VERSION ""

NS_ :

BS_:

BU_: Gateway_25 FCM_A0 FLR SRR_RL External_Tool SRR_FL Steering_E4 VCU_47 CLS_17 ESC_0B EMS_00
VAL_TABLE_ TSC1CtrlPurpose 31 "Temporary Powertrain Control" 6 " Automated Driving System Input\r" 5 "Transient-Optimized Torque Limi" 4 "Engine Protection\r" 3 "Road Speed Governor\r" 2 " PTO Governor\r" 1 "Cruise Control\r" 0 "AcceleratorPedalOperatorSelect" ;
VAL_TABLE_ TrctrMntdTrailerABSWarningSignal 3 " Take no action" 2 "Reserved\r" 1 "on" 0 "Off\r" ;
VAL_TABLE_ EBSBrakeSwitch 3 "Not available" 2 "Error" 1 "Brake pedal being pressed\r" 0 "Brake pedal not beingpressed\r" ;
VAL_TABLE_ TSC1TransRate 6 "20 ms transmission rate\r" 5 "50 ms transmission rate\r" 4 "100 ms transmission rate\r" 3 "250 ms transmission rate\r" 2 "500 ms transmission rate\r" 1 "750 ms transmission rate\r" 0 "1000 ms transmission rate" ;
VAL_TABLE_ SeatBeltSwitch 3 "Not Available" 2 " Error - Switch state cannot be determined\r" 1 "OK - Seat Belt is buckled\r" 0 "NOT Buckled\r" ;
VAL_TABLE_ HighLowBeamSwitch 3 "not available" 2 "error" 1 "High Beam Selected\r" 0 "Low Beam Selected\r" ;
VAL_TABLE_ HazardLightSwitch 3 "not available" 2 "error" 1 "Hazard Lamps to be Flashing" 0 "Hazard Lamps to be Off\r" ;
VAL_TABLE_ TurnSignalSwitch 15 "Not available (do not change)" 14 "Error (to include both left and right selected simultaneously)\r" 13 "Description for the value '0xD'" 12 "Description for the value '0xC'" 11 "Description for the value '0xB'" 10 "Description for the value '0xA'" 9 "Description for the value '0x9'" 8 "Description for the value '0x8'" 7 "Description for the value '0x7'" 6 "Description for the value '0x6'" 5 "Description for the value '0x5'" 4 "Description for the value '0x4'" 3 "Description for the value '0x3'" 2 "Right turn to be Flashing\r" 1 "Left Turn to be Flashing\r" 0 "No Turn being signaled\r" ;
VAL_TABLE_ YCBrakeCtrlActive 3 "take no action" 2 "reserved" 1 "YC brake control active" 0 "YC brake control passive but installed\r" ;
VAL_TABLE_ YCEngCtrlActive 3 "Don't care/Take no action" 2 "reserved" 1 "YC engine control active" 0 "YC engine control passive but installed\r" ;
VAL_TABLE_ ROPBrakeCtrlActive 3 "take no action" 2 "reserved" 1 "ROP brake control active\r" 0 "ROP brake control passive but installed\r" ;
VAL_TABLE_ ROPEngCtrlActive 3 "take no action" 2 "reserved" 1 "ROP engine control active\r" 0 "ROP engine control passive but installed\r" ;
VAL_TABLE_ VDCBrakeLightRq 3 "don't care/ take no action" 2 "reserved" 1 "Turn brake light on\r" 0 "Turn brake light not on\r" ;
VAL_TABLE_ VDCFullyOperational 3 "Don't care/Take no action" 2 "Reserved\r" 1 "Fully operational\r" 0 "Not fully operationa" ;
VAL_TABLE_ XBRActiveCtrlMode 15 "Not available" 14 "Description for the value '0xE'" 13 "Description for the value '0xD'" 12 "Description for the value '0xC'" 11 "Description for the value '0xB'" 10 "Description for the value '0xA'" 9 "Description for the value '0x9'" 8 "Description for the value '0x8'" 7 "Description for the value '0x7'" 6 "Description for the value '0x6'" 5 "Description for the value '0x5'" 4 "XBR Brake Hold is being executed to hold the vehicle still based on XBR Brake Hold Request\r" 3 "Maximum mode of XBR acceleration control being executed" 2 "Addition mode of XBR acceleration control being executed" 1 "Driver's brake demand being executed, no external brake demand\r" 0 "No brake demand being executed (default mode)\r" ;
VAL_TABLE_ XBRSystemState 3 "not available" 2 " No external brake demand will be accepted " 1 "Only external brake demand of highest XBR Priority (00b) will be accepted " 0 "Any external brake demand will be accepted (brake system fully operational)\r" ;
VAL_TABLE_ FoundationBrakeUse 3 "not available" 2 "reserved" 1 "Foundation brakes in use\r" 0 "Foundation brakes not in use" ;
VAL_TABLE_ ABSFullyOperational 3 "not available" 2 "reserved" 1 " Fully Operational" 0 "Not Fully Operational\r" ;
VAL_TABLE_ AntiLockBrakingActive 3 "not available" 2 "reserved" 1 "ABS active\r" 0 "ABS passive but installed" ;
VAL_TABLE_ ASRBrakeCtrlActive 3 "not available" 2 "reserved" 1 "ASR brake control active" 0 "ASR brake control passive but installed\r" ;
VAL_TABLE_ ASREngCtrlActive 3 "not available" 2 "reserved" 1 "ASR engine control active" 0 "ASR engine control passive but installed\r" ;
VAL_TABLE_ AccelPedalKickdownSwitch 3 "not available" 2 "error" 1 "kickdown active" 0 "kickdown passive" ;
VAL_TABLE_ brakeSwitch 3 "no available" 2 "error" 1 "pedal depressed" 0 "pedal released" ;
VAL_TABLE_ FrontOperatorWiperSwitch 15 "Not available (do not change)" 14 "Description for the value '0xE'" 13 "Description for the value '0xD'" 12 "Description for the value '0xC'" 11 "Description for the value '0xB'" 10 "Description for the value '0xA'" 9 "Description for the value '0x9'" 8 "Description for the value '0x8'" 7 "Description for the value '0x7'" 6 "Mist (position where external sensor  controls wiper rate)\r" 5 "Delayed 2 (used for the second delay choice when the wiper switch position controls the delay" 4 "Delayed 1 (used for the first delay choice when the wiper switch position controls the delay)\r" 3 "high" 2 "medium" 1 "low" 0 "Off" ;
VAL_TABLE_ LaneDepartureWarningEnableCmd 3 "dont care" 2 "Reserved\r" 1 "Enable Lane Departure Warning\r" 0 "Disable Lane Departure Warning\r" ;
VAL_TABLE_ DrvrActvtnDmndFrAdvncdEmrgncyBrk 3 "don't' care / take no action" 2 "reserved" 1 "the driver wants the Advanced Emergency Braking System to warn or intervene if necessary (no deactivation of system)\r" 0 " the driver does not want the Advanced Emergency Braking System to warn or intervene at any time (deactivation of system)\r" ;
VAL_TABLE_ WarningRelevanObjectDetected 7 "Not available / not installed" 6 "Error " 5 "Relevant object(s) is not being detected reliably " 4 "Description for the value '0x4'" 3 "Description for the value '0x3'" 2 "Multiple relevant objects are being monitored" 1 "Single relevant object is being monitored " 0 "No relevant object monitored" ;
VAL_TABLE_ CollisionWarningLevel 15 "don't care / take no action" 14 "reserved" 13 "reserved" 12 "reserved" 11 "reserved" 10 "reserved" 9 "reserved" 8 "reserved" 7 "warning level 7 - HIGHEST" 6 "warning level 6" 5 "warning level 5" 4 "warning level 4" 3 "warning level 3" 2 "warning level 2" 1 "warning level 1 - lowest\r" 0 "no warning\r" ;
VAL_TABLE_ MOISsystemState 15 "not available / not installed" 14 "error indication" 13 "Description for the value '0xD'" 12 "Description for the value '0xC'" 11 "Description for the value '0xB'" 10 "Description for the value '0xA'" 9 "Description for the value '0x9'" 8 "system performance and/or sensitivity limited (no warning and no braking active) " 7 "Description for the value '0x7'" 6 "collision warning with additional system response (e.g. braking/steering) " 5 "collision warning active with visual/audio cues (e.g. acoustic signal) " 4 "driver overrides system" 3 "system is ready and activated (no warning and no braking active) " 2 "system is deactivated by driver / Inform only mode" 1 "system is temporarily not available (e.g. due to boundary conditions necessary for operation" 0 "system is not ready (initialization not finished)" ;
VAL_TABLE_ BendOffProbMostImportantObject 7 "signal not available / not installed" 6 "error indication " 5 "monitored object is already in a bend-off maneuver " 4 "highest probability for a bend-off maneuver of the object " 3 "high probability for a bend-off maneuver of the object " 2 "medium probability for a bend-off maneuver of the object " 1 "low probability for a bend-off maneuver of the object " 0 "no indication for a bend-off maneuver of the object " ;
VAL_TABLE_ BSWarningRelevantObjectDetected 7 "Not available / not installed" 6 "Error " 5 "Relevant object(s) is not being detected reliably " 4 "Description for the value '0x4'" 3 "Description for the value '0x3'" 2 "Multiple relevant objects are being monitored" 1 "Single relevant object is being monitored " 0 "No relevant object monitored" ;
VAL_TABLE_ BlindSpotCollisionWarningLevel 15 "don't care / take no action" 14 "reserved" 13 "reserved" 12 "reserved" 11 "reserved" 10 "reserved" 9 "reserved" 8 "reserved" 7 "warning level 7 - HIGHEST" 6 "warning level 6" 5 "warning level 5" 4 "warning level 4" 3 "warning level 3" 2 "warning level 2" 1 "warning level 1 - lowest\r" 0 "no warning\r" ;
VAL_TABLE_ BlindspotDetectionState 15 "not available / not installed" 14 "error indication" 13 "Description for the value '0xD'" 12 "Description for the value '0xC'" 11 "Description for the value '0xB'" 10 "Description for the value '0xA'" 9 "Description for the value '0x9'" 8 "system performance and/or sensitivity limited (no warning and no braking active) " 7 "Description for the value '0x7'" 6 "collision warning with additional system response (e.g. braking/steering) " 5 "collision warning active with visual/audio cues (e.g. acoustic signal) " 4 "driver overrides system" 3 "system is ready and activated (no warning and no braking active) " 2 "system is deactivated by driver / Inform only mode" 1 "system is temporarily not available (e.g. due to boundary conditions necessary for operation" 0 "system is not ready (initialization not finished)" ;
VAL_TABLE_ ImagerStatus 15 "not available" 14 "error" 13 "Description for the value '0xD'" 12 "Description for the value '0xC'" 11 "Description for the value '0xB'" 10 "Description for the value '0xA'" 9 "Description for the value '0x9'" 8 "Description for the value '0x8'" 7 "Description for the value '0x7'" 6 "Description for the value '0x6'" 5 "Imager view degraded but functional\r" 4 "Imager misaligned" 3 "Imager fully blocked / fully blind\r" 2 "Imager partially blocked / partially blind" 1 "Imager warming up / initializing\r" 0 "Imager fully operational" ;
VAL_TABLE_ DepWarnSysSt 15 "Not available" 14 "Error\r" 13 "Description for the value '0xD'" 12 "Description for the value '0xC'" 11 "Description for the value '0xB'" 10 "Description for the value '0xA'" 9 "Description for the value '0x9'" 8 "Description for the value '0x8'" 7 "Description for the value '0x7'" 6 "Description for the value '0x6'" 5 "System is warning lane departure\r" 4 "Active warning suppressed by operator behavior (e.g. turn signal)\r" 3 "System is ready (no warnings active)\r" 2 "System is deactivated by driver\r" 1 "System is temporarily not available (not all activation conditions fulfulled)\r" 0 "System is not ready (initialization not finished" ;
VAL_TABLE_ DriverAlertnessWarningSysState 7 "Not Available / Not Installed" 6 "Description for the value '0x6'" 5 "Description for the value '0x5'" 4 "System monitoring driver behavior\r" 3 "System available" 2 "System temporarily not available\r" 1 "Initializing" 0 "System installed but disabled\r" ;
VAL_TABLE_ LnDpartureIndicationEnableStatus 3 "not used" 2 "Reserved\r" 1 "Lane Departure Indication enabled \r" 0 "Lane Departure indication disabled\r" ;
VAL_TABLE_ LeftSideLaneDepHapticWarnCmd 3 "not available" 2 "reserved" 1 "warning\r" 0 "Not warning" ;
VAL_TABLE_ RightSideLaneDepHapticWarnCmd 3 "not available" 2 "reserved" 1 "warning\r" 0 "Not warning" ;
VAL_TABLE_ LeftSideLaneDepAcstWarnCmd 3 "not available" 2 "reserved" 1 "warning\r" 0 "Not warning" ;
VAL_TABLE_ RightSideLaneDepAcstWarnCmd 3 "not available" 2 "reserved" 1 "warning\r" 0 "Not warning" ;
VAL_TABLE_ LeftSideLaneDepOpticalWarnCmd 3 "not available" 2 "reserved" 1 "warning\r" 0 "Not warning" ;
VAL_TABLE_ RightSideLaneDepOpticalWarnCmd 3 "not available" 2 "reserved" 1 "warning\r" 0 "Not warning" ;
VAL_TABLE_ DriverAlertnessWarning 7 "Not Available" 6 "Description for the value '0x6'" 5 "Description for the value '0x5'" 4 "Description for the value '0x4'" 3 "Level 3 - Driver alertness warning" 2 "Level 2 - Degradation in driving behavior detected" 1 "Level 1 - Mild distraction or extended driving condition detected" 0 "No distracted driving condition detected\r" ;
VAL_TABLE_ LaneDepartureImminentLeftside 3 "not used" 2 "reserved" 1 "Imminent\r" 0 "Not imminent\r" ;
VAL_TABLE_ LaneDepartureImminentRightSide 3 "not used" 2 "reserved" 1 "Imminent\r" 0 "Not imminent\r" ;
VAL_TABLE_ LaneDepartureRight 3 " Take no action" 2 "Reserved\r" 1 "Middle of the vehicle departs the lane to the right side\r" 0 "Middle of the vehicle does not depart the lane to the right side\r" ;
VAL_TABLE_ LaneDepartureLeft 3 "Take no action" 2 "Reserved\r" 1 "Middle of the vehicle departs the lane to the left side\r" 0 "Middle of the vehicle does not depart the lane to the left side" ;
VAL_TABLE_ XBRCtrlMode 3 "Not defined" 2 "Acceleration control with maximum mode Execute the XBR acceleration demand .\r" 1 "Acceleration control with addition mode - Add the XBR acceleration demand to the driver's acceleration demand.\r" 0 "Override disabled � Disable any existing control commanded by the source of this command" ;
VAL_TABLE_ XBRPriority 3 "Low priority � used in override disabled  XBR Control Mode" 2 "Medium priority � used for ACC-Systems." 1 "High priority � not defined" 0 " Highest priority � used for emergency situations" ;
VAL_TABLE_ XBREBIMode 3 "Not defined" 2 "Endurance Brake Integration allowed" 1 "Only Endurance Brakes allowed\r" 0 "No Endurance Brake Integration allowed\r\r
" ;
VAL_TABLE_ OverrideCtrlModePriority 3 "Low priority" 2 "Medium priority\r" 1 "High priority\r" 0 "Highest priority" ;
VAL_TABLE_ EngRequestedSpeedCtrlConditions 3 "Stability Optimized for driveline engaged and/or in lockup condition 2 (e.g., PTO driveline)\r" 2 "Stability Optimized for driveline engaged and/or in lockup condition 1 (e.g., vehicle driveline" 1 "Stability Optimized for driveline disengaged and non-lockup conditions\r" 0 " Transient Optimized for driveline disengaged and non-lockup conditions\r" ;
VAL_TABLE_ EngOverrideCtrlMode 3 "Speed/torque limit control - Limit speed and/or torque based on the included limit values.  " 2 "Torque control - Control torque to the included desired torque value" 1 "Speed control - Govern speed to the included desired speed value.\r" 0 "Override disabled - Disable any existing control commanded by the source of this command.\r" ;
VAL_TABLE_ RlvntObjctDtctdFrAdvncdEmrgncyBr 7 "Signal not available / not installed" 6 "Error indication\r" 5 "RESERVED" 4 "Description for the value '0x4'" 3 "Description for the value '0x3'" 2 "Relevant object is not being detected reliably" 1 "Relevant object is being monitored\r" 0 "No relevant object monitored" ;
VAL_TABLE_ AdvncdEmrgencyBrakingSystemState 15 "not available / not installed" 14 "error indication\r" 13 "Description for the value '0xD'" 12 "Description for the value '0xC'" 11 "Description for the value '0xB'" 10 "reserved for future use\r" 9 "reserved for future use\r" 8 "system performance and/or sensitivity limited (no warning and no braking active)\r" 7 "forward collision emergency braking active\r" 6 "forward collision warning with braking (e.g. brake jerk or partial braking)\r" 5 " forward collision warning active (e.g. acoustic signal, cruise control turned off, torque limitation" 4 "driver overrides system" 3 " system is ready and activated (no warning and no braking active)\r" 2 "system is deactivated by driver\r" 1 "system is temporarily not available (e.g. due to boundary conditions necessary for operation" 0 "system is not ready (initialization not finished" ;

BO_ 3221225472 VECTOR__INDEPENDENT_SIG_MSG: 0 Vector__XXX
 SG_ STS_XCP_RES_CTO_Byte7_Copy_1 : 0|8@0+ (1,0) [0|255] "" Vector__XXX
 SG_ CAP_AngleAzimuthRangeEnd_Copy_1 : 0|9@1- (1,0) [-180|180] "degree" Vector__XXX
 SG_ IDSM_Audit_Log : 0|64@0+ (1,0) [0|1.8446744074E+19] "" Vector__XXX
 SG_ AL_STS_002_CYCLE_COUNTER : 0|8@1+ (1,0) [0|255] "" Vector__XXX
 SG_ AL_STS_002_MH_CRC16 : 0|16@1+ (1,0) [0|65535] "" Vector__XXX
 SG_ STS_AlignmentShortTrackStatus : 0|3@1+ (1,0) [0|4] "" Vector__XXX
 SG_ STS_AverageSpeed : 0|32@1+ (0.01,0) [0|200] "m/s" Vector__XXX
 SG_ STS_DurationEffective : 0|32@1+ (1,0) [0|4294967295] "ms" Vector__XXX
 SG_ STS_DurationAbsolute : 0|32@1+ (1,0) [0|4294967295] "ms" Vector__XXX
 SG_ STS_AverageNumberOfDetections : 0|32@1+ (1,0) [0|4294967295] "" Vector__XXX
 SG_ STS_DistanceEffective : 0|32@1+ (1,0) [0|4294967295] "m" Vector__XXX
 SG_ STS_DistanceAbsolute : 0|32@1+ (1,0) [0|4294967295] "m" Vector__XXX
 SG_ STS_VehicleCondition : 0|3@1+ (1,0) [0|6] "" Vector__XXX
 SG_ STS_AlignmentServiceStatus : 0|3@1+ (1,0) [0|4] "" Vector__XXX
 SG_ STS_ImpactByInterference : 0|1@1+ (1,0) [0|1] "" Vector__XXX
 SG_ STS_MeasuredAmpSTD : 0|15@1+ (0.01,0) [0|327.67] "dBsm" Vector__XXX
 SG_ STS_MeasuredRawAmplitude : 0|13@1- (0.01,0) [-5|40] "dBsm" Vector__XXX
 SG_ STS_MeasuredRangeRateStd : 0|16@1- (1,0) [-10000|10000] "mm/s" Vector__XXX
 SG_ STS_MeasuredRangeRate : 0|18@1- (1,0) [-128000|128000] "mm/s" Vector__XXX
 SG_ STS_MeasuredRangeStd : 0|16@1+ (1,0) [0|10000] "mm" Vector__XXX
 SG_ STS_Measured_Range : 0|14@1+ (1,0) [0|10000] "mm" Vector__XXX
 SG_ STS_AlignmentStaticStatus : 0|3@1+ (1,0) [0|4] "" Vector__XXX
 SG_ STS_StartRoll : 0|15@1- (0.0002,0) [-3.14|3.14] "rad" Vector__XXX
 SG_ STS_AACurrentRoll : 0|15@1- (0.0002,0) [-3.14159|3.14159] "rad" Vector__XXX
 SG_ STS_AARoll_Std : 0|14@1+ (0.0002,0) [0|3.14] "rad" Vector__XXX
 SG_ STS_RollErrorNegative : 0|15@1- (0.0002,0) [-3.14|3.14] "rad" Vector__XXX
 SG_ STS_Roll_Updates : 0|32@1+ (1,0) [0|4294967295] "" Vector__XXX
 SG_ AL_STS_001_CYCLE_COUNTER : 0|8@1+ (1,0) [0|255] "" Vector__XXX
 SG_ AL_STS_001_MH_CRC16 : 0|16@1+ (1,0) [0|65535] "" Vector__XXX
 SG_ STS_ElevationUpdates : 0|32@1+ (1,0) [0|4294967295] "" Vector__XXX
 SG_ STS_AzimuthUpdates : 0|32@1+ (1,0) [0|4294967295] "" Vector__XXX
 SG_ STS_HostSpdCompensationFactorQF : 0|2@1+ (1,0) [0|3] "" Vector__XXX
 SG_ STS_HostSpeedCompensationFactor : 0|7@1+ (0.01,0) [0.9|1.1] "" Vector__XXX
 SG_ STS_ElevationErrorNegative : 0|11@1- (0.0002,0) [-0.1745|0.1745] "rad" Vector__XXX
 SG_ STS_AzimuthErrorNegative : 0|15@1- (0.0002,0) [-3.14|3.14] "rad" Vector__XXX
 SG_ STS_RollErrorPositive : 0|10@1- (0.01,0) [-3.14|3.14] "rad" Vector__XXX
 SG_ STS_ElevationErrorPositive : 0|11@1- (0.0002,0) [-0.1745|0.1745] "rad" Vector__XXX
 SG_ STS_AzimuthErrorPositive : 0|15@1- (0.0002,0) [-3.14|3.14] "rad" Vector__XXX
 SG_ STS_AAElevationStd : 0|14@1+ (0.0002,0) [0|3.14] "rad" Vector__XXX
 SG_ STS_AAAzimuthStd : 0|14@1+ (0.0002,0) [0|3.14] "rad" Vector__XXX
 SG_ STS_AACurrentElevation : 0|11@1- (0.0002,0) [-0.1745|0.1745] "rad" Vector__XXX
 SG_ STS_AACurrentAzimuth : 0|15@1- (0.0002,0) [-3.1416|3.1416] "rad" Vector__XXX
 SG_ STS_StartElevation : 0|11@1- (0.0002,0) [-0.139|0.139] "rad" Vector__XXX
 SG_ STS_StartAzimuth : 0|15@1- (0.0002,0) [-3.14|3.14] "rad" Vector__XXX
 SG_ STS_AutoAlignmentFailRootCause : 0|5@1+ (1,0) [0|20] "" Vector__XXX
 SG_ STS_AlignmentAutoStatus : 0|3@1+ (1,0) [0|4] "" Vector__XXX
 SG_ STS_CalDisplay : 0|1@1+ (1,0) [0|1] "" Vector__XXX
 SG_ STS_AlignmentError : 0|5@1+ (1,0) [0|18] "" Vector__XXX
 SG_ STS_ProgressPercent : 0|7@1+ (1,0) [0|100] "%" Vector__XXX
 SG_ STS_CalTime : 0|12@1+ (1,0) [0|3600] "s" Vector__XXX
 SG_ STS_ElevationStd : 0|13@1+ (0.001,0) [0|6] "degree" Vector__XXX
 SG_ STS_AzimuthStd : 0|13@1+ (0.001,0) [0|6] "degree" Vector__XXX
 SG_ STS_AlignmentElevation : 0|15@1+ (0.001,-10) [-10|10] "degree" Vector__XXX
 SG_ STS_AlignmentAzimuth : 0|15@1+ (0.001,-10) [-10|10] "degree" Vector__XXX
 SG_ STS_InitAlignRsltHostSpdCompFac : 0|7@1+ (0.01,0) [0.9|1.1] "" Vector__XXX
 SG_ STS_InitAlignRsltElevationUpdate : 0|16@1+ (1,0) [0|65535] "" Vector__XXX
 SG_ STS_InitAlignResultAzimuthUpdate : 0|16@1+ (1,0) [0|65535] "" Vector__XXX
 SG_ STS_AlignmentModeOut : 0|3@1+ (1,0) [0|4] "" Vector__XXX
 SG_ STS_InitLastSuccessfulAlignMode : 0|3@1+ (1,0) [0|5] "" Vector__XXX
 SG_ STS_InitAlignmentResultElevation : 0|14@1- (0.001,0) [-6|6] "degree" Vector__XXX
 SG_ STS_InitAlignmentResultAzimuth : 0|15@1- (0.001,0) [-10|10] "degree" Vector__XXX
 SG_ STS_RadarTypeInput : 0|3@1+ (1,0) [0|7] "" Vector__XXX
 SG_ STS_CoordinateSystemInput : 0|2@1+ (1,0) [0|2] "" Vector__XXX
 SG_ STS_AlignmentModeIn : 0|3@1+ (1,0) [0|5] "" Vector__XXX
 SG_ CAP_MaxDetRangePedestrian_2 : 0|9@1+ (1,0) [0|500] "m" Vector__XXX
 SG_ CAP_MaxDetRangePedestrian_1 : 0|9@1+ (1,0) [0|500] "m" Vector__XXX
 SG_ CAP_MaxDetRangeMotorbike_2 : 0|9@1+ (1,0) [0|500] "m" Vector__XXX
 SG_ CAP_MaxDetRangeMotorbike_0 : 0|9@1+ (1,0) [0|500] "m" Vector__XXX
 SG_ CAP_MaxDetectionRangeCar_2 : 0|9@1+ (1,0) [0|500] "m" Vector__XXX
 SG_ CAP_MaxDetectionRangeCar_1 : 0|9@1+ (1,0) [0|500] "m" Vector__XXX
 SG_ CAP_CYCLE_COUNTER : 0|8@1+ (1,0) [0|255] "" Vector__XXX
 SG_ CAP_MH_CRC16 : 0|16@1+ (1,0) [0|65535] "" Vector__XXX
 SG_ CAP_SideLobeLevelBeamformer : 0|8@1+ (1,0) [0|255] "" Vector__XXX
 SG_ CAP_SLLMonitoringStatus : 0|3@1+ (1,0) [0|4] "" Vector__XXX
 SG_ CAP_SLLMonitoringActive : 0|1@1+ (1,0) [0|1] "" Vector__XXX
 SG_ CAP_AngleAzimuthRangeEnd : 0|9@1- (1,0) [-180|180] "degree" Vector__XXX
 SG_ CAP_AngleAzimuthRangeStart : 0|9@1- (1,0) [-180|180] "degree" Vector__XXX
 SG_ CAP_MaxDetRangePedestrian_0 : 0|9@1+ (1,0) [0|500] "m" Vector__XXX
 SG_ CAP_MaxDetRangeMotorbike_1 : 0|9@1+ (1,0) [0|500] "m" Vector__XXX
 SG_ CAP_MaxDetectionRangeCar_0 : 0|9@1+ (1,0) [0|500] "m" Vector__XXX
 SG_ CAP_RangeEstimationStatus : 0|3@1+ (1,0) [0|4] "" Vector__XXX
 SG_ CAP_RangeEstimationActive : 0|1@1+ (1,0) [0|1] "" Vector__XXX
 SG_ CAP_DampingStandardDeviation : 0|8@1+ (1,0) [0|255] "dB" Vector__XXX
 SG_ CAP_DampingStatus : 0|3@1+ (1,0) [0|4] "" Vector__XXX
 SG_ CAP_DampingActive : 0|1@1+ (1,0) [0|1] "" Vector__XXX
 SG_ CAP_DampingCurrent : 0|16@1+ (0.01,0) [0|255] "dB" Vector__XXX
 SG_ CAP_SLBlockageFilterValue : 0|6@1+ (1,0) [0|35] "dB" Vector__XXX
 SG_ CAP_SLBlockageFlag : 0|1@1+ (1,0) [0|1] "" Vector__XXX
 SG_ CAP_FreeSightCheckStatus : 0|8@1+ (1,0) [0|255] "" Vector__XXX
 SG_ CAP_FreeSightCheckActive : 0|8@1+ (1,0) [0|255] "" Vector__XXX
 SG_ CAP_BlockageProbability : 0|7@1+ (1,0) [0|100] "%" Vector__XXX
 SG_ CAP_BlockageValue : 0|3@1+ (1,0) [0|6] "" Vector__XXX
 SG_ CAP_BlockageStatus : 0|3@1+ (1,0) [0|4] "" Vector__XXX
 SG_ CAP_BlockageActive : 0|1@1+ (1,0) [0|1] "" Vector__XXX
 SG_ CAP_BlockageSensitivity : 0|8@1+ (1,0) [0|255] "" Vector__XXX
 SG_ RDR_NM_PNC_Reserved3 : 0|8@0+ (1,0) [0|255] "" Vector__XXX
 SG_ RDR_NM_PNC_Reserved2 : 0|8@0+ (1,0) [0|255] "" Vector__XXX
 SG_ RDR_NM_PNC_Reserved1 : 0|8@0+ (1,0) [0|255] "" Vector__XXX
 SG_ RDR_NM_Wakeup_And_Reason : 0|8@0+ (1,0) [0|255] "" Vector__XXX
 SG_ RDR_NM_PN_User_Data : 0|8@0+ (1,0) [0|255] "" Vector__XXX
 SG_ RDR_NM_CAN_NM_State : 0|8@0+ (1,0) [0|255] "" Vector__XXX
 SG_ RDR_NM_CBV_ResdBit_7 : 0|1@0+ (1,0) [0|1] "" Vector__XXX
 SG_ RDR_NM_CBV_ResdBit_5 : 0|1@0+ (1,0) [0|1] "" Vector__XXX
 SG_ RDR_NM_CBV_ResdBit_2 : 0|1@0+ (1,0) [0|1] "" Vector__XXX
 SG_ RDR_NM_CBV_ResdBit_1 : 0|1@0+ (1,0) [0|1] "" Vector__XXX
 SG_ RDR_NM_CBV_ReptMsgBit0 : 0|1@0+ (1,0) [0|1] "" Vector__XXX
 SG_ RDR_NM_CBV_PNIBit_6 : 0|1@0+ (1,0) [0|1] "" Vector__XXX
 SG_ RDR_NM_CBV_NMCoordBit_3 : 0|1@0+ (1,0) [0|1] "" Vector__XXX
 SG_ RDR_NM_CBV_ActWakeBit_4 : 0|1@0+ (1,0) [0|1] "" Vector__XXX
 SG_ RDR_NM_SrcNodeID : 0|8@0+ (1,0) [0|255] "" Vector__XXX
 SG_ Diag_Req_Phys : 0|64@0+ (1,0) [0|0] "" Vector__XXX
 SG_ Diag_Resp_Phys : 0|64@0+ (1,0) [0|0] "" Vector__XXX
 SG_ STS_DIST_FRNT_BMPR_TO_RR_AXL : 0|13@1+ (0.001,0) [0|8.191] "m" Vector__XXX
 SG_ STS_SENSOR_POLARITY : 0|1@1+ (1,0) [0|1] "" Vector__XXX
 SG_ STS_SP_CORE_TIME_PEAK : 0|8@1+ (0.5,0) [0|127.5] "ms" Vector__XXX
 SG_ STS_SP_CORE_TIME_INST : 0|8@1+ (0.5,0) [0|127.5] "ms" Vector__XXX
 SG_ STS_RDD_CORE_TIME_PEAK : 0|8@1+ (0.5,0) [0|127.5] "ms" Vector__XXX
 SG_ STS_RDD_CORE_TIME_INST : 0|8@1+ (0.5,0) [0|127.5] "ms" Vector__XXX
 SG_ STS_MAIN_CORE_TIME_PEAK : 0|8@1+ (0.5,0) [0|127.5] "ms" Vector__XXX
 SG_ STS_MAIN_CORE_TIME_INST : 0|8@1+ (0.5,0) [0|127.5] "ms" Vector__XXX
 SG_ STS_AF_TIME_PEAK : 0|8@1+ (0.5,0) [0|127.5] "ms" Vector__XXX
 SG_ STS_AF_TIME_INST : 0|8@1+ (0.5,0) [0|127.5] "ms" Vector__XXX
 SG_ STS_PCAN_PROTOCOL_VER_MINOR : 0|8@1+ (1,0) [0|255] "" Vector__XXX
 SG_ STS_PCAN_PROTOCOL_VER_MAJOR : 0|8@1+ (1,0) [0|255] "" Vector__XXX
 SG_ STS_PLATFORM_VARIANT : 0|5@1+ (1,0) [0|18] "" Vector__XXX
 SG_ STS_HARDWARE_VERSION : 0|3@1+ (1,0) [0|5] "" Vector__XXX
 SG_ STS_SERIAL_NUMBER_SEQUENCE : 0|14@1+ (1,0) [0|9999] "" Vector__XXX
 SG_ STS_SERIAL_NUM_JULIAN_YEAR : 0|3@1+ (1,2020) [2020|2027] "years" Vector__XXX
 SG_ STS_SERIAL_NUM_JULIAN_DAY : 0|9@1+ (1,0) [0|366] "" Vector__XXX
 SG_ STS_SW_VERSION_FIELD1 : 0|8@1+ (1,0) [0|255] "" Vector__XXX
 SG_ STS_SW_VERSION_FIELD2 : 0|8@1+ (1,0) [0|255] "" Vector__XXX
 SG_ STS_SW_VERSION_FIELD3 : 0|8@1+ (1,0) [0|255] "" Vector__XXX
 SG_ STS_SW_VERSION_FIELD4 : 0|8@1+ (1,0) [0|255] "" Vector__XXX
 SG_ STS_PBL_VERSION_FIELD1 : 0|8@1+ (1,0) [0|255] "" Vector__XXX
 SG_ STS_PBL_VERSION_FIELD2 : 0|8@1+ (1,0) [0|255] "" Vector__XXX
 SG_ STS_PBL_VERSION_FIELD3 : 0|8@1+ (1,0) [0|255] "" Vector__XXX
 SG_ STS_PBL_VERSION_FIELD4 : 0|8@1+ (1,0) [0|255] "" Vector__XXX
 SG_ STS_USC_CAL_VER_MAJOR : 0|16@1+ (1,0) [0|65535] "" Vector__XXX
 SG_ STS_USC_CAL_VER_MINOR : 0|16@1+ (1,0) [0|65535] "" Vector__XXX
 SG_ STS_USC_SECTION_COMPTBLITY : 0|16@1+ (1,0) [0|255] "" Vector__XXX
 SG_ STS_SMC_CAL_VER_MAJOR : 0|16@1+ (1,0) [0|65535] "" Vector__XXX
 SG_ STS_SMC_CAL_VER_MINOR : 0|16@1+ (1,0) [0|65535] "" Vector__XXX
 SG_ STS_SMC_SECTION_COMPTBLITY : 0|16@1+ (1,0) [0|65535] "" Vector__XXX
 SG_ STS_SMC_PLATFROM_VERSION : 0|8@1+ (1,0) [0|14] "" Vector__XXX
 SG_ STS_SENSOR_MOUNT_POS_X : 0|14@1+ (0.001,-8.192) [-8.192|8.191] "m" Vector__XXX
 SG_ STS_SENSOR_MOUNT_POS_Y : 0|16@1+ (0.0001,-3.2768) [-3.2768|3.2767] "m" Vector__XXX
 SG_ STS_SENSOR_MOUNT_POS_Z : 0|16@1+ (0.0001,-3.2768) [-3.2768|3.2767] "m" Vector__XXX
 SG_ STS_SENSOR_MOUNT_ORNT_YAW : 0|14@1- (0.0004,0) [-3.14|3.14] "rad" Vector__XXX
 SG_ STS_SENSOR_MOUNT_ORNT_PITCH : 0|14@1- (0.0004,0) [-3.14|3.14] "rad" Vector__XXX
 SG_ STS_SENSOR_MOUNT_ORNT_ROLL : 0|14@1+ (0.0004,-3.14159) [-3.14159|3.41161] "rad" Vector__XXX
 SG_ STS_SENSOR_HEIGHT : 0|32@1+ (0.01,0) [0|42949672.95] "m" Vector__XXX
 SG_ STS_DET_DBC_BASE_VER_MINOR : 0|8@1+ (1,0) [0|255] "" Vector__XXX
 SG_ STS_DET_DBC_BASE_VER_MAJOR : 0|8@1+ (1,0) [0|255] "" Vector__XXX
 SG_ STS_TIME_SINCE_POWER_ON : 0|32@1+ (1,0) [0|4294967295] "s" Vector__XXX
 SG_ STS_SENSOR_POSITION : 0|3@1+ (1,0) [0|7] "" Vector__XXX
 SG_ STS_MH_001_CRC16 : 0|16@1+ (1,0) [0|65535] "" Vector__XXX
 SG_ STS_MH_001_CYCLE_COUNTER : 0|8@1+ (1,0) [0|255] "" Vector__XXX
 SG_ STS_INTRFC_VERSION_ID_PATCH : 0|8@1+ (1,0) [0|255] "" Vector__XXX
 SG_ STS_INTRFC_VERSION_ID_MINOR : 0|8@1+ (1,0) [0|255] "" Vector__XXX
 SG_ STS_INTRFC_VERSION_ID_MAJOR : 0|8@1+ (1,0) [0|255] "" Vector__XXX
 SG_ STS_Yaw_Rate_Calc_QF : 0|2@1+ (1,0) [0|3] "" Vector__XXX
 SG_ STS_Vehicle_Speed_Calc_QF : 0|2@1+ (1,0) [0|3] "" Vector__XXX
 SG_ STS_Gear_Position : 0|4@1+ (1,0) [0|15] "" Vector__XXX
 SG_ STS_RAIN_COUNT : 0|9@1+ (1,0) [0|400] "" Vector__XXX
 SG_ STS_Last_CAN_Det_Inst_Latency : 0|12@1+ (0.1,0) [0|255] "ms" Vector__XXX
 SG_ STS_First_CAN_Det_Inst_Latency : 0|12@1+ (0.1,0) [0|255] "ms" Vector__XXX
 SG_ STS_CAN_NM_State : 0|8@1+ (1,0) [0|255] "" Vector__XXX
 SG_ STS_Project_ACTV_FLT_BYTE_4_to_5 : 0|16@1+ (1,0) [0|65535] "" Vector__XXX
 SG_ STS_Project_ACTV_FLT_BYTE_0_to_3 : 0|32@1+ (1,0) [0|4294967295] "" Vector__XXX
 SG_ STS_CORE_ACTV_FLT_BYTE_11_to_15 : 0|32@1+ (1,0) [0|4294967295] "" Vector__XXX
 SG_ STS_CORE_ACTV_FLT_BYTE_8_to_11 : 0|32@1+ (1,0) [0|4294967295] "" Vector__XXX
 SG_ STS_CORE_ACTV_FLT_BYTE_0_to_3 : 0|32@1+ (1,0) [0|4294967295] "" Vector__XXX
 SG_ STS_MMIC_TEMP_TX0 : 0|8@1+ (1,-50) [-50|205] "C" Vector__XXX
 SG_ STS_VEHICLE_SUPPLY_VOLTAGE : 0|4@1+ (1,0) [0|15] "" Vector__XXX
 SG_ STS_MH_002_CYCLE_COUNTER : 0|8@1+ (1,0) [0|255] "" Vector__XXX
 SG_ STS_MH_002_CRC16 : 0|16@1+ (1,0) [0|65535] "" Vector__XXX
 SG_ STS_POINT_OF_TRIGGER : 0|10@1+ (0.1,0) [0|102.3] "ms" Vector__XXX
 SG_ STS_NO_TSYN_ERROR : 0|1@1+ (1,0) [0|1] "" Vector__XXX
 SG_ STS_BRR_STATUS : 0|2@1+ (1,0) [0|2] "" Vector__XXX
 SG_ STS_MMIC_TEMP_RX : 0|8@1+ (1,-50) [-50|205] "C" Vector__XXX
 SG_ STS_MMIC_RE_INIT_COUNT : 0|4@1+ (1,0) [0|15] "" Vector__XXX
 SG_ STS_MCU_TEMP : 0|8@1+ (1,-50) [-50|205] "C" Vector__XXX
 SG_ STS_MMIC_TEMP_TX3_4 : 0|8@1+ (1,-50) [-50|205] "C" Vector__XXX
 SG_ STS_MMIC_TEMP_TX1_2 : 0|8@1+ (1,-50) [-50|205] "C" Vector__XXX
 SG_ STS_RDD_CORE_THROUGHPUT : 0|6@1+ (1.588,0) [0|100] "%" Vector__XXX
 SG_ STS_AF_CORE_THROUGHPUT : 0|6@1+ (1.588,0) [0|100] "%" Vector__XXX
 SG_ STS_SCAN_TYPE : 0|1@1+ (1,0) [0|1] "" Vector__XXX
 SG_ STS_XCVR_OPERATIONAL : 0|1@1+ (1,0) [0|1] "" Vector__XXX
 SG_ STS_YAW_RATE_BIAS : 0|4@1+ (0.025,0) [0|0.375] "rad/s" Vector__XXX
 SG_ STS_CORE_ACTV_FLT_BYTE_4_to_7 : 0|32@1+ (1,0) [0|4294967295] "" Vector__XXX
 SG_ STS_VEH_SPEED_DIRECTION : 0|1@1+ (1,0) [0|1] "" Vector__XXX
 SG_ STS_STEERING_ANGLE_SIGN : 0|1@1+ (1,0) [0|1] "" Vector__XXX
 SG_ STS_STEERING_ANGLE : 0|8@1+ (0.0174533,0) [0|3.141599] "rad" Vector__XXX
 SG_ STS_VEHICLE_SPEED_CALC : 0|14@1+ (0.01,0) [0|163.83] "m/s" Vector__XXX
 SG_ STS_TIME_SYNC_OFFSET : 0|16@1- (1,0) [-32768|32767] "us" Vector__XXX
 SG_ HED_RDR_HEADER_CMAC : 0|40@1+ (1,0) [0|1099511627800] "" Vector__XXX
 SG_ HED_RDR_HEADER_FV : 0|56@1+ (1,0) [0|7.2057594038E+16] "" Vector__XXX
 SG_ HED_Rain_Level : 0|2@1+ (1,0) [0|2] "" Vector__XXX
 SG_ HED_V_WRAPPING : 0|11@1+ (0.01,-40) [-40|-19.53] "mps" Vector__XXX
 SG_ HED_R_WRAPPING : 0|8@1+ (0.01,-0.9) [-0.9|1.65] "m" Vector__XXX
 SG_ HED_Auth_CRC32 : 0|32@1+ (1,0) [0|4294967295] "" Vector__XXX
 SG_ HED_SLOPE_CORR_EXECUTIONFLAG : 0|2@1+ (1,0) [0|3] "" Vector__XXX
 SG_ HED_PROCESSED_RANGE : 0|9@1+ (1,0) [0|500] "" Vector__XXX
 SG_ HED_LOOK_INDEX : 0|16@1+ (1,0) [0|65535] "" Vector__XXX
 SG_ HED_OPERATION_MODE : 0|3@1+ (1,0) [0|5] "" Vector__XXX
 SG_ HED_MAX_NUM_OF_DETECTIONS : 0|9@1+ (1,0) [0|400] "" Vector__XXX
 SG_ HED_NUM_OF_RESTBINS_USED : 0|9@1+ (1,0) [0|511] "" Vector__XXX
 SG_ HED_NUM_OF_VALID_DETECTIONS : 0|9@1+ (1,0) [0|500] "" Vector__XXX
 SG_ HED_LOOK_ID : 0|2@1+ (1,0) [0|3] "" Vector__XXX
 SG_ HED_SCAN_INDEX : 0|16@1+ (1,0) [0|65535] "" Vector__XXX
 SG_ HED_MH_CYCLE_COUNTER : 0|8@1+ (1,0) [0|255] "" Vector__XXX
 SG_ HED_DATA_QUALIFIER : 0|3@1+ (1,0) [0|7] "" Vector__XXX
 SG_ HED_DET_RANGE_MAX : 0|16@1+ (0.01,0) [0|500] "m" Vector__XXX
 SG_ HED_DET_SPEED_RANGE_MAX : 0|16@1+ (0.00390625,-128) [-128|127.99609375] "m/s" Vector__XXX
 SG_ HED_FOV_HOR_MAX : 0|8@1+ (0.0174533,0) [0|3.14159] "rad" Vector__XXX
 SG_ HED_FOV_VER_MAX : 0|8@1+ (0.0174533,0) [0|3.14159] "rad" Vector__XXX
 SG_ HED_DET_RANGE_MIN : 0|16@1+ (0.01,0) [0|500] "m" Vector__XXX
 SG_ HED_DET_SPEED_RANGE_MIN : 0|16@1+ (0.00390625,-128) [-128|127.99609375] "m/s" Vector__XXX
 SG_ HED_FOV_HOR_MIN : 0|8@1- (0.0174533,0) [-2.2340224|2.2165691] "rad" Vector__XXX
 SG_ HED_FOV_VER_MIN : 0|8@1- (0.0174533,0) [-2.2340224|2.2165691] "rad" Vector__XXX
 SG_ HED_ALIGN_VER_REF : 0|10@1+ (0.0005,-0.1745) [-0.1745|0.337] "rad" Vector__XXX
 SG_ HED_ALIGN_HOR_REF : 0|13@1+ (0.0005,-0.1745) [-0.1745|3.921] "rad" Vector__XXX
 SG_ HED_SENSOR_TIME_STAMP_NS : 0|32@1+ (1,0) [0|4294967295] "ns" Vector__XXX
 SG_ HED_SENSOR_TIME_STAMP_SEC : 0|32@1+ (1,0) [0|4294967295] "s" Vector__XXX
 SG_ HED_TIME_SYNC_SRC_MASTER : 0|1@1+ (1,0) [0|1] "" Vector__XXX
 SG_ HED_TIME_SYNC_VALIDITY_FLAG : 0|2@1+ (1,0) [0|2] "" Vector__XXX
 SG_ HED_MH_CRC16 : 0|16@1+ (1,0) [0|65535] "" Vector__XXX
 SG_ HED_DET_NUM_OF_1PASS : 0|10@1+ (1,0) [0|1023] "" Vector__XXX
 SG_ HED_DET_NUM_OF_2PASS : 0|9@1+ (1,0) [0|511] "" Vector__XXX
 SG_ HED_TRIGGER_TIME : 0|32@1+ (1,0) [0|4294967295] "ns" Vector__XXX
 SG_ HED_DET_BI_STATIC_COUNT : 0|8@1+ (1,0) [0|255] "" Vector__XXX
 SG_ STS_XCP_REQ_CTO_Byte1 : 0|8@0+ (1,0) [0|255] "" Vector__XXX
 SG_ STS_XCP_REQ_CTO_Byte2 : 0|8@0+ (1,0) [0|255] "" Vector__XXX
 SG_ STS_XCP_REQ_CTO_Byte3 : 0|8@0+ (1,0) [0|255] "" Vector__XXX
 SG_ STS_XCP_REQ_CTO_Byte4 : 0|8@0+ (1,0) [0|255] "" Vector__XXX
 SG_ STS_XCP_REQ_CTO_Byte5 : 0|8@0+ (1,0) [0|255] "" Vector__XXX
 SG_ STS_XCP_REQ_CTO_Byte6 : 0|8@0+ (1,0) [0|255] "" Vector__XXX
 SG_ STS_XCP_REQ_CTO_Byte7 : 0|8@0+ (1,0) [0|255] "" Vector__XXX
 SG_ STS_XCP_REQ_CTO_Byte8 : 0|8@0+ (1,0) [0|255] "" Vector__XXX
 SG_ STS_XCP_REQ_CTO_Byte9 : 0|8@0+ (1,0) [0|255] "" Vector__XXX
 SG_ STS_XCP_REQ_CTO_Byte10 : 0|8@0+ (1,0) [0|255] "" Vector__XXX
 SG_ STS_XCP_REQ_CTO_Byte11 : 0|8@0+ (1,0) [0|255] "" Vector__XXX
 SG_ STS_XCP_REQ_CTO_Byte12 : 0|8@0+ (1,0) [0|255] "" Vector__XXX
 SG_ STS_XCP_REQ_CTO_Byte13 : 0|8@0+ (1,0) [0|255] "" Vector__XXX
 SG_ STS_XCP_REQ_CTO_Byte14 : 0|8@0+ (1,0) [0|255] "" Vector__XXX
 SG_ STS_XCP_REQ_CTO_Byte15 : 0|8@0+ (1,0) [0|255] "" Vector__XXX
 SG_ STS_XCP_REQ_CTO_Byte16 : 0|8@0+ (1,0) [0|255] "" Vector__XXX
 SG_ STS_XCP_REQ_CTO_Byte17 : 0|8@0+ (1,0) [0|255] "" Vector__XXX
 SG_ STS_XCP_REQ_CTO_Byte18 : 0|8@0+ (1,0) [0|255] "" Vector__XXX
 SG_ STS_XCP_REQ_CTO_Byte19 : 0|8@0+ (1,0) [0|255] "" Vector__XXX
 SG_ STS_XCP_REQ_CTO_Byte20 : 0|8@0+ (1,0) [0|255] "" Vector__XXX
 SG_ STS_XCP_REQ_CTO_Byte21 : 0|8@0+ (1,0) [0|255] "" Vector__XXX
 SG_ STS_XCP_REQ_CTO_Byte22 : 0|8@0+ (1,0) [0|255] "" Vector__XXX
 SG_ STS_XCP_REQ_CTO_Byte23 : 0|8@0+ (1,0) [0|255] "" Vector__XXX
 SG_ STS_XCP_REQ_CTO_Byte24 : 0|8@0+ (1,0) [0|255] "" Vector__XXX
 SG_ STS_XCP_REQ_CTO_Byte25 : 0|8@0+ (1,0) [0|255] "" Vector__XXX
 SG_ STS_XCP_REQ_CTO_Byte26 : 0|8@0+ (1,0) [0|255] "" Vector__XXX
 SG_ STS_XCP_REQ_CTO_Byte27 : 0|8@0+ (1,0) [0|255] "" Vector__XXX
 SG_ STS_XCP_REQ_CTO_Byte28 : 0|8@0+ (1,0) [0|255] "" Vector__XXX
 SG_ STS_XCP_REQ_CTO_Byte29 : 0|8@0+ (1,0) [0|255] "" Vector__XXX
 SG_ STS_XCP_REQ_CTO_Byte30 : 0|8@0+ (1,0) [0|255] "" Vector__XXX
 SG_ STS_XCP_REQ_CTO_Byte31 : 0|8@0+ (1,0) [0|255] "" Vector__XXX
 SG_ STS_XCP_REQ_CTO_Byte32 : 0|8@0+ (1,0) [0|255] "" Vector__XXX
 SG_ STS_XCP_REQ_CTO_Byte33 : 0|8@0+ (1,0) [0|255] "" Vector__XXX
 SG_ STS_XCP_REQ_CTO_Byte34 : 0|8@0+ (1,0) [0|255] "" Vector__XXX
 SG_ STS_XCP_REQ_CTO_Byte35 : 0|8@0+ (1,0) [0|255] "" Vector__XXX
 SG_ STS_XCP_REQ_CTO_Byte36 : 0|8@0+ (1,0) [0|255] "" Vector__XXX
 SG_ STS_XCP_REQ_CTO_Byte37 : 0|8@0+ (1,0) [0|255] "" Vector__XXX
 SG_ STS_XCP_REQ_CTO_Byte38 : 0|8@0+ (1,0) [0|255] "" Vector__XXX
 SG_ STS_XCP_REQ_CTO_Byte39 : 0|8@0+ (1,0) [0|255] "" Vector__XXX
 SG_ STS_XCP_REQ_CTO_Byte40 : 0|8@0+ (1,0) [0|255] "" Vector__XXX
 SG_ STS_XCP_REQ_CTO_Byte41 : 0|8@0+ (1,0) [0|255] "" Vector__XXX
 SG_ STS_XCP_REQ_CTO_Byte42 : 0|8@0+ (1,0) [0|255] "" Vector__XXX
 SG_ STS_XCP_REQ_CTO_Byte43 : 0|8@0+ (1,0) [0|255] "" Vector__XXX
 SG_ STS_XCP_REQ_CTO_Byte44 : 0|8@0+ (1,0) [0|255] "" Vector__XXX
 SG_ STS_XCP_REQ_CTO_Byte45 : 0|8@0+ (1,0) [0|255] "" Vector__XXX
 SG_ STS_XCP_REQ_CTO_Byte46 : 0|8@0+ (1,0) [0|255] "" Vector__XXX
 SG_ STS_XCP_REQ_CTO_Byte47 : 0|8@0+ (1,0) [0|255] "" Vector__XXX
 SG_ STS_XCP_REQ_CTO_Byte48 : 0|8@0+ (1,0) [0|255] "" Vector__XXX
 SG_ STS_XCP_REQ_CTO_Byte49 : 0|8@0+ (1,0) [0|255] "" Vector__XXX
 SG_ STS_XCP_REQ_CTO_Byte50 : 0|8@0+ (1,0) [0|255] "" Vector__XXX
 SG_ STS_XCP_REQ_CTO_Byte51 : 0|8@0+ (1,0) [0|255] "" Vector__XXX
 SG_ STS_XCP_REQ_CTO_Byte52 : 0|8@0+ (1,0) [0|255] "" Vector__XXX
 SG_ STS_XCP_REQ_CTO_Byte53 : 0|8@0+ (1,0) [0|255] "" Vector__XXX
 SG_ STS_XCP_REQ_CTO_Byte54 : 0|8@0+ (1,0) [0|255] "" Vector__XXX
 SG_ STS_XCP_REQ_CTO_Byte55 : 0|8@0+ (1,0) [0|255] "" Vector__XXX
 SG_ STS_XCP_REQ_CTO_Byte56 : 0|8@0+ (1,0) [0|255] "" Vector__XXX
 SG_ STS_XCP_REQ_CTO_Byte57 : 0|8@0+ (1,0) [0|255] "" Vector__XXX
 SG_ STS_XCP_REQ_CTO_Byte58 : 0|8@0+ (1,0) [0|255] "" Vector__XXX
 SG_ STS_XCP_REQ_CTO_Byte59 : 0|8@0+ (1,0) [0|255] "" Vector__XXX
 SG_ STS_XCP_REQ_CTO_Byte60 : 0|8@0+ (1,0) [0|255] "" Vector__XXX
 SG_ STS_XCP_REQ_CTO_Byte61 : 0|8@0+ (1,0) [0|255] "" Vector__XXX
 SG_ STS_XCP_REQ_CTO_Byte62 : 0|8@0+ (1,0) [0|255] "" Vector__XXX
 SG_ STS_XCP_REQ_CTO_Byte63 : 0|8@0+ (1,0) [0|255] "" Vector__XXX
 SG_ STS_PID : 0|8@0+ (1,0) [0|255] "" Vector__XXX
 SG_ STS_XCP_RES_CTO_Byte0 : 0|8@0+ (1,0) [0|255] "" Vector__XXX
 SG_ STS_XCP_RES_CTO_Byte1 : 0|8@0+ (1,0) [0|255] "" Vector__XXX
 SG_ STS_XCP_RES_CTO_Byte2 : 0|8@0+ (1,0) [0|255] "" Vector__XXX
 SG_ STS_XCP_RES_CTO_Byte3 : 0|8@0+ (1,0) [0|255] "" Vector__XXX
 SG_ STS_XCP_RES_CTO_Byte4 : 0|8@0+ (1,0) [0|255] "" Vector__XXX
 SG_ STS_XCP_RES_CTO_Byte5 : 0|8@0+ (1,0) [0|255] "" Vector__XXX
 SG_ STS_XCP_RES_CTO_Byte6 : 0|8@0+ (1,0) [0|255] "" Vector__XXX
 SG_ STS_XCP_RES_CTO_Byte7 : 0|8@0+ (1,0) [0|255] "" Vector__XXX
 SG_ STS_XCP_RES_CTO_Byte8 : 0|8@0+ (1,0) [0|255] "" Vector__XXX
 SG_ STS_XCP_RES_CTO_Byte9 : 0|8@0+ (1,0) [0|255] "" Vector__XXX
 SG_ STS_XCP_RES_CTO_Byte10 : 0|8@0+ (1,0) [0|255] "" Vector__XXX
 SG_ STS_XCP_RES_CTO_Byte11 : 0|8@0+ (1,0) [0|255] "" Vector__XXX
 SG_ STS_XCP_RES_CTO_Byte12 : 0|8@0+ (1,0) [0|255] "" Vector__XXX
 SG_ STS_XCP_RES_CTO_Byte13 : 0|8@0+ (1,0) [0|255] "" Vector__XXX
 SG_ STS_XCP_RES_CTO_Byte14 : 0|8@0+ (1,0) [0|255] "" Vector__XXX
 SG_ STS_XCP_RES_CTO_Byte15 : 0|8@0+ (1,0) [0|255] "" Vector__XXX
 SG_ STS_XCP_RES_CTO_Byte16 : 0|8@0+ (1,0) [0|255] "" Vector__XXX
 SG_ STS_XCP_RES_CTO_Byte17 : 0|8@0+ (1,0) [0|255] "" Vector__XXX
 SG_ STS_XCP_RES_CTO_Byte18 : 0|8@0+ (1,0) [0|255] "" Vector__XXX
 SG_ STS_XCP_RES_CTO_Byte19 : 0|8@0+ (1,0) [0|255] "" Vector__XXX
 SG_ STS_XCP_RES_CTO_Byte20 : 0|8@0+ (1,0) [0|255] "" Vector__XXX
 SG_ STS_XCP_RES_CTO_Byte21 : 0|8@0+ (1,0) [0|255] "" Vector__XXX
 SG_ STS_XCP_RES_CTO_Byte22 : 0|8@0+ (1,0) [0|255] "" Vector__XXX
 SG_ STS_XCP_RES_CTO_Byte23 : 0|8@0+ (1,0) [0|255] "" Vector__XXX
 SG_ STS_XCP_RES_CTO_Byte24 : 0|8@0+ (1,0) [0|255] "" Vector__XXX
 SG_ STS_XCP_RES_CTO_Byte25 : 0|8@0+ (1,0) [0|255] "" Vector__XXX
 SG_ STS_XCP_RES_CTO_Byte26 : 0|8@0+ (1,0) [0|255] "" Vector__XXX
 SG_ STS_XCP_RES_CTO_Byte27 : 0|8@0+ (1,0) [0|255] "" Vector__XXX
 SG_ STS_XCP_RES_CTO_Byte28 : 0|8@0+ (1,0) [0|255] "" Vector__XXX
 SG_ STS_XCP_RES_CTO_Byte29 : 0|8@0+ (1,0) [0|255] "" Vector__XXX
 SG_ STS_XCP_RES_CTO_Byte30 : 0|8@0+ (1,0) [0|255] "" Vector__XXX
 SG_ STS_XCP_RES_CTO_Byte31 : 0|8@0+ (1,0) [0|255] "" Vector__XXX
 SG_ STS_XCP_RES_CTO_Byte32 : 0|8@0+ (1,0) [0|255] "" Vector__XXX
 SG_ STS_XCP_RES_CTO_Byte33 : 0|8@0+ (1,0) [0|255] "" Vector__XXX
 SG_ STS_XCP_RES_CTO_Byte34 : 0|8@0+ (1,0) [0|255] "" Vector__XXX
 SG_ STS_XCP_RES_CTO_Byte35 : 0|8@0+ (1,0) [0|255] "" Vector__XXX
 SG_ STS_XCP_RES_CTO_Byte36 : 0|8@0+ (1,0) [0|255] "" Vector__XXX
 SG_ STS_XCP_RES_CTO_Byte37 : 0|8@0+ (1,0) [0|255] "" Vector__XXX
 SG_ STS_XCP_RES_CTO_Byte38 : 0|8@0+ (1,0) [0|255] "" Vector__XXX
 SG_ STS_XCP_RES_CTO_Byte39 : 0|8@0+ (1,0) [0|255] "" Vector__XXX
 SG_ STS_XCP_RES_CTO_Byte40 : 0|8@0+ (1,0) [0|255] "" Vector__XXX
 SG_ STS_XCP_RES_CTO_Byte41 : 0|8@0+ (1,0) [0|255] "" Vector__XXX
 SG_ STS_XCP_RES_CTO_Byte42 : 0|8@0+ (1,0) [0|255] "" Vector__XXX
 SG_ STS_XCP_RES_CTO_Byte43 : 0|8@0+ (1,0) [0|255] "" Vector__XXX
 SG_ STS_XCP_RES_CTO_Byte44 : 0|8@0+ (1,0) [0|255] "" Vector__XXX
 SG_ STS_XCP_RES_CTO_Byte45 : 0|8@0+ (1,0) [0|255] "" Vector__XXX
 SG_ STS_XCP_RES_CTO_Byte46 : 0|8@0+ (1,0) [0|255] "" Vector__XXX
 SG_ STS_XCP_RES_CTO_Byte47 : 0|8@0+ (1,0) [0|255] "" Vector__XXX
 SG_ STS_XCP_RES_CTO_Byte48 : 0|8@0+ (1,0) [0|255] "" Vector__XXX
 SG_ STS_XCP_RES_CTO_Byte49 : 0|8@0+ (1,0) [0|255] "" Vector__XXX
 SG_ STS_XCP_RES_CTO_Byte50 : 0|8@0+ (1,0) [0|255] "" Vector__XXX
 SG_ STS_XCP_RES_CTO_Byte51 : 0|8@0+ (1,0) [0|255] "" Vector__XXX
 SG_ STS_XCP_RES_CTO_Byte52 : 0|8@0+ (1,0) [0|255] "" Vector__XXX
 SG_ STS_XCP_RES_CTO_Byte53 : 0|8@0+ (1,0) [0|255] "" Vector__XXX
 SG_ STS_XCP_RES_CTO_Byte54 : 0|8@0+ (1,0) [0|255] "" Vector__XXX
 SG_ STS_XCP_RES_CTO_Byte55 : 0|8@0+ (1,0) [0|255] "" Vector__XXX
 SG_ STS_XCP_RES_CTO_Byte56 : 0|8@0+ (1,0) [0|255] "" Vector__XXX
 SG_ STS_XCP_RES_CTO_Byte57 : 0|8@0+ (1,0) [0|255] "" Vector__XXX
 SG_ STS_XCP_RES_CTO_Byte58 : 0|8@0+ (1,0) [0|255] "" Vector__XXX
 SG_ STS_XCP_RES_CTO_Byte59 : 0|8@0+ (1,0) [0|255] "" Vector__XXX
 SG_ STS_XCP_RES_CTO_Byte60 : 0|8@0+ (1,0) [0|255] "" Vector__XXX
 SG_ STS_XCP_RES_CTO_Byte61 : 0|8@0+ (1,0) [0|255] "" Vector__XXX
 SG_ STS_XCP_RES_CTO_Byte62 : 0|8@0+ (1,0) [0|255] "" Vector__XXX
 SG_ STS_XCP_RES_CTO_Byte63 : 0|8@0+ (1,0) [0|255] "" Vector__XXX
 SG_ STS_XCP_RES_DAQ_Byte0 : 0|8@0+ (1,0) [0|255] "" Vector__XXX
 SG_ STS_XCP_RES_DAQ_Byte1 : 0|8@0+ (1,0) [0|255] "" Vector__XXX
 SG_ STS_XCP_RES_DAQ_Byte2 : 0|8@0+ (1,0) [0|255] "" Vector__XXX
 SG_ STS_XCP_RES_DAQ_Byte3 : 0|8@0+ (1,0) [0|255] "" Vector__XXX
 SG_ STS_XCP_RES_DAQ_Byte4 : 0|8@0+ (1,0) [0|255] "" Vector__XXX
 SG_ STS_XCP_RES_DAQ_Byte5 : 0|8@0+ (1,0) [0|255] "" Vector__XXX
 SG_ STS_XCP_RES_DAQ_Byte6 : 0|8@0+ (1,0) [0|255] "" Vector__XXX
 SG_ STS_XCP_RES_DAQ_Byte7 : 0|8@0+ (1,0) [0|255] "" Vector__XXX
 SG_ STS_XCP_RES_DAQ_Byte8 : 0|8@0+ (1,0) [0|255] "" Vector__XXX
 SG_ STS_XCP_RES_DAQ_Byte9 : 0|8@0+ (1,0) [0|255] "" Vector__XXX
 SG_ STS_XCP_RES_DAQ_Byte10 : 0|8@0+ (1,0) [0|255] "" Vector__XXX
 SG_ STS_XCP_RES_DAQ_Byte11 : 0|8@0+ (1,0) [0|255] "" Vector__XXX
 SG_ STS_XCP_RES_DAQ_Byte12 : 0|8@0+ (1,0) [0|255] "" Vector__XXX
 SG_ STS_XCP_RES_DAQ_Byte13 : 0|8@0+ (1,0) [0|255] "" Vector__XXX
 SG_ STS_XCP_RES_DAQ_Byte14 : 0|8@0+ (1,0) [0|255] "" Vector__XXX
 SG_ STS_XCP_RES_DAQ_Byte15 : 0|8@0+ (1,0) [0|255] "" Vector__XXX
 SG_ STS_XCP_RES_DAQ_Byte16 : 0|8@0+ (1,0) [0|255] "" Vector__XXX
 SG_ STS_XCP_RES_DAQ_Byte17 : 0|8@0+ (1,0) [0|255] "" Vector__XXX
 SG_ STS_XCP_RES_DAQ_Byte18 : 0|8@0+ (1,0) [0|255] "" Vector__XXX
 SG_ STS_XCP_RES_DAQ_Byte19 : 0|8@0+ (1,0) [0|255] "" Vector__XXX
 SG_ STS_XCP_RES_DAQ_Byte20 : 0|8@0+ (1,0) [0|255] "" Vector__XXX
 SG_ STS_XCP_RES_DAQ_Byte21 : 0|8@0+ (1,0) [0|255] "" Vector__XXX
 SG_ STS_XCP_RES_DAQ_Byte22 : 0|8@0+ (1,0) [0|255] "" Vector__XXX
 SG_ STS_XCP_RES_DAQ_Byte23 : 0|8@0+ (1,0) [0|255] "" Vector__XXX
 SG_ STS_XCP_RES_DAQ_Byte24 : 0|8@0+ (1,0) [0|255] "" Vector__XXX
 SG_ STS_XCP_RES_DAQ_Byte25 : 0|8@0+ (1,0) [0|255] "" Vector__XXX
 SG_ STS_XCP_RES_DAQ_Byte26 : 0|8@0+ (1,0) [0|255] "" Vector__XXX
 SG_ STS_XCP_RES_DAQ_Byte27 : 0|8@0+ (1,0) [0|255] "" Vector__XXX
 SG_ STS_XCP_RES_DAQ_Byte28 : 0|8@0+ (1,0) [0|255] "" Vector__XXX
 SG_ STS_XCP_RES_DAQ_Byte29 : 0|8@0+ (1,0) [0|255] "" Vector__XXX
 SG_ STS_XCP_RES_DAQ_Byte30 : 0|8@0+ (1,0) [0|255] "" Vector__XXX
 SG_ STS_XCP_RES_DAQ_Byte31 : 0|8@0+ (1,0) [0|255] "" Vector__XXX
 SG_ STS_XCP_RES_DAQ_Byte32 : 0|8@0+ (1,0) [0|255] "" Vector__XXX
 SG_ STS_XCP_RES_DAQ_Byte33 : 0|8@0+ (1,0) [0|255] "" Vector__XXX
 SG_ STS_XCP_RES_DAQ_Byte34 : 0|8@0+ (1,0) [0|255] "" Vector__XXX
 SG_ STS_XCP_RES_DAQ_Byte35 : 0|8@0+ (1,0) [0|255] "" Vector__XXX
 SG_ STS_XCP_RES_DAQ_Byte36 : 0|8@0+ (1,0) [0|255] "" Vector__XXX
 SG_ STS_XCP_RES_DAQ_Byte37 : 0|8@0+ (1,0) [0|255] "" Vector__XXX
 SG_ STS_XCP_RES_DAQ_Byte38 : 0|8@0+ (1,0) [0|255] "" Vector__XXX
 SG_ STS_XCP_RES_DAQ_Byte39 : 0|8@0+ (1,0) [0|255] "" Vector__XXX
 SG_ STS_XCP_RES_DAQ_Byte40 : 0|8@0+ (1,0) [0|255] "" Vector__XXX
 SG_ STS_XCP_RES_DAQ_Byte41 : 0|8@0+ (1,0) [0|255] "" Vector__XXX
 SG_ STS_XCP_RES_DAQ_Byte42 : 0|8@0+ (1,0) [0|255] "" Vector__XXX
 SG_ STS_XCP_RES_DAQ_Byte43 : 0|8@0+ (1,0) [0|255] "" Vector__XXX
 SG_ STS_XCP_RES_DAQ_Byte44 : 0|8@0+ (1,0) [0|255] "" Vector__XXX
 SG_ STS_XCP_RES_DAQ_Byte45 : 0|8@0+ (1,0) [0|255] "" Vector__XXX
 SG_ STS_XCP_RES_DAQ_Byte46 : 0|8@0+ (1,0) [0|255] "" Vector__XXX
 SG_ STS_XCP_RES_DAQ_Byte47 : 0|8@0+ (1,0) [0|255] "" Vector__XXX
 SG_ STS_XCP_RES_DAQ_Byte48 : 0|8@0+ (1,0) [0|255] "" Vector__XXX
 SG_ STS_XCP_RES_DAQ_Byte49 : 0|8@0+ (1,0) [0|255] "" Vector__XXX
 SG_ STS_XCP_RES_DAQ_Byte50 : 0|8@0+ (1,0) [0|255] "" Vector__XXX
 SG_ STS_XCP_RES_DAQ_Byte51 : 0|8@0+ (1,0) [0|255] "" Vector__XXX
 SG_ STS_XCP_RES_DAQ_Byte52 : 0|8@0+ (1,0) [0|255] "" Vector__XXX
 SG_ STS_XCP_RES_DAQ_Byte53 : 0|8@0+ (1,0) [0|255] "" Vector__XXX
 SG_ STS_XCP_RES_DAQ_Byte54 : 0|8@0+ (1,0) [0|255] "" Vector__XXX
 SG_ STS_XCP_RES_DAQ_Byte55 : 0|8@0+ (1,0) [0|255] "" Vector__XXX
 SG_ STS_XCP_RES_DAQ_Byte56 : 0|8@0+ (1,0) [0|255] "" Vector__XXX
 SG_ STS_XCP_RES_DAQ_Byte57 : 0|8@0+ (1,0) [0|255] "" Vector__XXX
 SG_ STS_XCP_RES_DAQ_Byte58 : 0|8@0+ (1,0) [0|255] "" Vector__XXX
 SG_ STS_XCP_RES_DAQ_Byte59 : 0|8@0+ (1,0) [0|255] "" Vector__XXX
 SG_ STS_XCP_RES_DAQ_Byte60 : 0|8@0+ (1,0) [0|255] "" Vector__XXX
 SG_ STS_XCP_RES_DAQ_Byte61 : 0|8@0+ (1,0) [0|255] "" Vector__XXX
 SG_ STS_XCP_RES_DAQ_Byte62 : 0|8@0+ (1,0) [0|255] "" Vector__XXX
 SG_ STS_XCP_RES_DAQ_Byte63 : 0|8@0+ (1,0) [0|255] "" Vector__XXX
 SG_ SYS_NM_PNC_Reserved3 : 0|8@0+ (1,0) [0|255] "" Vector__XXX
 SG_ SYS_NM_PNC_Reserved2 : 0|8@0+ (1,0) [0|255] "" Vector__XXX
 SG_ SYS_NM_PNC_Reserved1 : 0|8@0+ (1,0) [0|255] "" Vector__XXX
 SG_ SYS_NM_Wakeup_And_Reason : 0|8@0+ (1,0) [0|255] "" Vector__XXX
 SG_ SYS_NM_CAN_NM_State : 0|8@0+ (1,0) [0|255] "" Vector__XXX
 SG_ SYS_NM_PN_User_Data : 0|8@0+ (1,0) [0|255] "" Vector__XXX
 SG_ SYS_NM_CBV_ResdBit_7 : 0|1@0+ (1,0) [0|1] "" Vector__XXX
 SG_ SYS_NM_CBV_ResdBit_5 : 0|1@0+ (1,0) [0|1] "" Vector__XXX
 SG_ SYS_NM_CBV_ResdBit_2 : 0|1@0+ (1,0) [0|1] "" Vector__XXX
 SG_ SYS_NM_CBV_ResdBit_1 : 0|1@0+ (1,0) [0|1] "" Vector__XXX
 SG_ SYS_NM_CBV_ReptMsgBit0 : 0|1@0+ (1,0) [0|1] "" Vector__XXX
 SG_ SYS_NM_CBV_PNIBit_6 : 0|1@0+ (1,0) [0|1] "" Vector__XXX
 SG_ SYS_NM_CBV_NMCoordBit_3 : 0|1@0+ (1,0) [0|1] "" Vector__XXX
 SG_ SYS_NM_CBV_ActWakeBit_4 : 0|1@0+ (1,0) [0|1] "" Vector__XXX
 SG_ SYS_NM_SrcNodeID : 0|8@0+ (1,0) [0|255] "" Vector__XXX
 SG_ RDR_NM_PNC_Reserved3 : 0|8@0+ (1,0) [0|255] "" Vector__XXX
 SG_ RDR_NM_PNC_Reserved2 : 0|8@0+ (1,0) [0|255] "" Vector__XXX
 SG_ RDR_NM_PNC_Reserved1 : 0|8@0+ (1,0) [0|255] "" Vector__XXX
 SG_ RDR_NM_Wakeup_And_Reason : 0|8@0+ (1,0) [0|255] "" Vector__XXX
 SG_ RDR_NM_PN_User_Data : 0|8@0+ (1,0) [0|255] "" Vector__XXX
 SG_ RDR_NM_CAN_NM_State : 0|8@0+ (1,0) [0|255] "" Vector__XXX
 SG_ RDR_NM_CBV_ResdBit_7 : 0|1@0+ (1,0) [0|1] "" Vector__XXX
 SG_ RDR_NM_CBV_ResdBit_5 : 0|1@0+ (1,0) [0|1] "" Vector__XXX
 SG_ RDR_NM_CBV_ResdBit_2 : 0|1@0+ (1,0) [0|1] "" Vector__XXX
 SG_ RDR_NM_CBV_ResdBit_1 : 0|1@0+ (1,0) [0|1] "" Vector__XXX
 SG_ RDR_NM_CBV_ReptMsgBit0 : 0|1@0+ (1,0) [0|1] "" Vector__XXX
 SG_ RDR_NM_CBV_PNIBit_6 : 0|1@0+ (1,0) [0|1] "" Vector__XXX
 SG_ RDR_NM_CBV_NMCoordBit_3 : 0|1@0+ (1,0) [0|1] "" Vector__XXX
 SG_ RDR_NM_CBV_ActWakeBit_4 : 0|1@0+ (1,0) [0|1] "" Vector__XXX
 SG_ RDR_NM_SrcNodeID : 0|8@0+ (1,0) [0|255] "" Vector__XXX
 SG_ IDSM_Audit_Log : 0|64@0+ (1,0) [0|1.8446744074E+19] "" Vector__XXX
 SG_ STS_StartRoll : 0|15@1- (0.0002,0) [-3.14|3.14] "rad" Vector__XXX
 SG_ STS_AACurrentRoll : 0|15@1- (0.0002,0) [-3.14159|3.14159] "rad" Vector__XXX
 SG_ STS_AARoll_Std : 0|14@1+ (0.0002,0) [0|3.14] "rad" Vector__XXX
 SG_ STS_RollErrorNegative : 0|15@1- (0.0002,0) [-3.14|3.14] "rad" Vector__XXX
 SG_ STS_Roll_Updates : 0|32@1+ (1,0) [0|4294967295] "" Vector__XXX
 SG_ STS_RollErrorPositive : 0|10@1- (0.01,0) [-3.14|3.14] "rad" Vector__XXX
 SG_ STS_RadarTypeInput : 0|3@1+ (1,0) [0|7] "" Vector__XXX
 SG_ STS_StartRoll : 0|15@1- (0.0002,0) [-3.14|3.14] "rad" Vector__XXX
 SG_ STS_AACurrentRoll : 0|15@1- (0.0002,0) [-3.14159|3.14159] "rad" Vector__XXX
 SG_ STS_AARoll_Std : 0|14@1+ (0.0002,0) [0|3.14] "rad" Vector__XXX
 SG_ STS_RollErrorNegative : 0|15@1- (0.0002,0) [-3.14|3.14] "rad" Vector__XXX
 SG_ STS_Roll_Updates : 0|32@1+ (1,0) [0|4294967295] "" Vector__XXX
 SG_ STS_RollErrorPositive : 0|10@1- (0.01,0) [-3.14|3.14] "rad" Vector__XXX
 SG_ STS_RadarTypeInput : 0|3@1+ (1,0) [0|7] "" Vector__XXX
 SG_ STS_StartRoll : 0|15@1- (0.0002,0) [-3.14|3.14] "rad" Vector__XXX
 SG_ STS_AACurrentRoll : 0|15@1- (0.0002,0) [-3.14159|3.14159] "rad" Vector__XXX
 SG_ STS_AARoll_Std : 0|14@1+ (0.0002,0) [0|3.14] "rad" Vector__XXX
 SG_ STS_RollErrorNegative : 0|15@1- (0.0002,0) [-3.14|3.14] "rad" Vector__XXX
 SG_ STS_Roll_Updates : 0|32@1+ (1,0) [0|4294967295] "" Vector__XXX
 SG_ STS_RollErrorPositive : 0|10@1- (0.01,0) [-3.14|3.14] "rad" Vector__XXX
 SG_ STS_RadarTypeInput : 0|3@1+ (1,0) [0|7] "" Vector__XXX
 SG_ HED_RDR_HEADER_CMAC : 0|40@1+ (1,0) [0|1099511627800] "" Vector__XXX
 SG_ HED_RDR_HEADER_FV : 0|56@1+ (1,0) [0|7.2057594038E+16] "" Vector__XXX
 SG_ BlindSpotWarnigRelevantObjDetect : 0|3@1+ (1,0) [0|7] "" Vector__XXX
 SG_ BendOffPrbablityofMstImportatObj : 0|3@1+ (1,0) [0|7] "" Vector__XXX

BO_ 1796 FCM_IFV_SWVersion: 64 Vector__XXX
 SG_ SWVersion_PATCH : 16|8@1+ (1,0) [0|255] "" Vector__XXX
 SG_ SWVersion_MINOR : 8|8@1+ (1,0) [0|255] "" Vector__XXX
 SG_ SWVersion_MAJOR : 0|8@1+ (1,0) [0|255] "" Vector__XXX

BO_ 82 FCM_XCP_DAQ_RESP: 64 FCM_A0
 SG_ STS_XCP_RES_DAQ_Byte0 : 7|8@0+ (1,0) [0|255] "" Vector__XXX
 SG_ STS_XCP_RES_DAQ_Byte1 : 15|8@0+ (1,0) [0|255] "" Vector__XXX
 SG_ STS_XCP_RES_DAQ_Byte2 : 23|8@0+ (1,0) [0|255] "" Vector__XXX
 SG_ STS_XCP_RES_DAQ_Byte3 : 31|8@0+ (1,0) [0|255] "" Vector__XXX
 SG_ STS_XCP_RES_DAQ_Byte4 : 39|8@0+ (1,0) [0|255] "" Vector__XXX
 SG_ STS_XCP_RES_DAQ_Byte5 : 47|8@0+ (1,0) [0|255] "" Vector__XXX
 SG_ STS_XCP_RES_DAQ_Byte6 : 55|8@0+ (1,0) [0|255] "" Vector__XXX
 SG_ STS_XCP_RES_DAQ_Byte7 : 63|8@0+ (1,0) [0|255] "" Vector__XXX
 SG_ STS_XCP_RES_DAQ_Byte8 : 71|8@0+ (1,0) [0|255] "" Vector__XXX
 SG_ STS_XCP_RES_DAQ_Byte9 : 79|8@0+ (1,0) [0|255] "" Vector__XXX
 SG_ STS_XCP_RES_DAQ_Byte10 : 87|8@0+ (1,0) [0|255] "" Vector__XXX
 SG_ STS_XCP_RES_DAQ_Byte11 : 95|8@0+ (1,0) [0|255] "" Vector__XXX
 SG_ STS_XCP_RES_DAQ_Byte12 : 103|8@0+ (1,0) [0|255] "" Vector__XXX
 SG_ STS_XCP_RES_DAQ_Byte13 : 111|8@0+ (1,0) [0|255] "" Vector__XXX
 SG_ STS_XCP_RES_DAQ_Byte14 : 119|8@0+ (1,0) [0|255] "" Vector__XXX
 SG_ STS_XCP_RES_DAQ_Byte15 : 127|8@0+ (1,0) [0|255] "" Vector__XXX
 SG_ STS_XCP_RES_DAQ_Byte16 : 135|8@0+ (1,0) [0|255] "" Vector__XXX
 SG_ STS_XCP_RES_DAQ_Byte17 : 143|8@0+ (1,0) [0|255] "" Vector__XXX
 SG_ STS_XCP_RES_DAQ_Byte18 : 151|8@0+ (1,0) [0|255] "" Vector__XXX
 SG_ STS_XCP_RES_DAQ_Byte19 : 159|8@0+ (1,0) [0|255] "" Vector__XXX
 SG_ STS_XCP_RES_DAQ_Byte20 : 167|8@0+ (1,0) [0|255] "" Vector__XXX
 SG_ STS_XCP_RES_DAQ_Byte21 : 175|8@0+ (1,0) [0|255] "" Vector__XXX
 SG_ STS_XCP_RES_DAQ_Byte22 : 183|8@0+ (1,0) [0|255] "" Vector__XXX
 SG_ STS_XCP_RES_DAQ_Byte23 : 191|8@0+ (1,0) [0|255] "" Vector__XXX
 SG_ STS_XCP_RES_DAQ_Byte24 : 199|8@0+ (1,0) [0|255] "" Vector__XXX
 SG_ STS_XCP_RES_DAQ_Byte25 : 207|8@0+ (1,0) [0|255] "" Vector__XXX
 SG_ STS_XCP_RES_DAQ_Byte26 : 215|8@0+ (1,0) [0|255] "" Vector__XXX
 SG_ STS_XCP_RES_DAQ_Byte27 : 223|8@0+ (1,0) [0|255] "" Vector__XXX
 SG_ STS_XCP_RES_DAQ_Byte28 : 231|8@0+ (1,0) [0|255] "" Vector__XXX
 SG_ STS_XCP_RES_DAQ_Byte29 : 239|8@0+ (1,0) [0|255] "" Vector__XXX
 SG_ STS_XCP_RES_DAQ_Byte30 : 247|8@0+ (1,0) [0|255] "" Vector__XXX
 SG_ STS_XCP_RES_DAQ_Byte31 : 255|8@0+ (1,0) [0|255] "" Vector__XXX
 SG_ STS_XCP_RES_DAQ_Byte32 : 263|8@0+ (1,0) [0|255] "" Vector__XXX
 SG_ STS_XCP_RES_DAQ_Byte33 : 271|8@0+ (1,0) [0|255] "" Vector__XXX
 SG_ STS_XCP_RES_DAQ_Byte34 : 279|8@0+ (1,0) [0|255] "" Vector__XXX
 SG_ STS_XCP_RES_DAQ_Byte35 : 287|8@0+ (1,0) [0|255] "" Vector__XXX
 SG_ STS_XCP_RES_DAQ_Byte36 : 295|8@0+ (1,0) [0|255] "" Vector__XXX
 SG_ STS_XCP_RES_DAQ_Byte37 : 303|8@0+ (1,0) [0|255] "" Vector__XXX
 SG_ STS_XCP_RES_DAQ_Byte38 : 311|8@0+ (1,0) [0|255] "" Vector__XXX
 SG_ STS_XCP_RES_DAQ_Byte39 : 319|8@0+ (1,0) [0|255] "" Vector__XXX
 SG_ STS_XCP_RES_DAQ_Byte40 : 327|8@0+ (1,0) [0|255] "" Vector__XXX
 SG_ STS_XCP_RES_DAQ_Byte41 : 335|8@0+ (1,0) [0|255] "" Vector__XXX
 SG_ STS_XCP_RES_DAQ_Byte42 : 343|8@0+ (1,0) [0|255] "" Vector__XXX
 SG_ STS_XCP_RES_DAQ_Byte43 : 351|8@0+ (1,0) [0|255] "" Vector__XXX
 SG_ STS_XCP_RES_DAQ_Byte44 : 359|8@0+ (1,0) [0|255] "" Vector__XXX
 SG_ STS_XCP_RES_DAQ_Byte45 : 367|8@0+ (1,0) [0|255] "" Vector__XXX
 SG_ STS_XCP_RES_DAQ_Byte46 : 375|8@0+ (1,0) [0|255] "" Vector__XXX
 SG_ STS_XCP_RES_DAQ_Byte47 : 383|8@0+ (1,0) [0|255] "" Vector__XXX
 SG_ STS_XCP_RES_DAQ_Byte48 : 391|8@0+ (1,0) [0|255] "" Vector__XXX
 SG_ STS_XCP_RES_DAQ_Byte49 : 399|8@0+ (1,0) [0|255] "" Vector__XXX
 SG_ STS_XCP_RES_DAQ_Byte50 : 407|8@0+ (1,0) [0|255] "" Vector__XXX
 SG_ STS_XCP_RES_DAQ_Byte51 : 415|8@0+ (1,0) [0|255] "" Vector__XXX
 SG_ STS_XCP_RES_DAQ_Byte52 : 423|8@0+ (1,0) [0|255] "" Vector__XXX
 SG_ STS_XCP_RES_DAQ_Byte53 : 431|8@0+ (1,0) [0|255] "" Vector__XXX
 SG_ STS_XCP_RES_DAQ_Byte54 : 439|8@0+ (1,0) [0|255] "" Vector__XXX
 SG_ STS_XCP_RES_DAQ_Byte55 : 447|8@0+ (1,0) [0|255] "" Vector__XXX
 SG_ STS_XCP_RES_DAQ_Byte56 : 455|8@0+ (1,0) [0|255] "" Vector__XXX
 SG_ STS_XCP_RES_DAQ_Byte57 : 463|8@0+ (1,0) [0|255] "" Vector__XXX
 SG_ STS_XCP_RES_DAQ_Byte58 : 471|8@0+ (1,0) [0|255] "" Vector__XXX
 SG_ STS_XCP_RES_DAQ_Byte59 : 479|8@0+ (1,0) [0|255] "" Vector__XXX
 SG_ STS_XCP_RES_DAQ_Byte60 : 487|8@0+ (1,0) [0|255] "" Vector__XXX
 SG_ STS_XCP_RES_DAQ_Byte61 : 495|8@0+ (1,0) [0|255] "" Vector__XXX
 SG_ STS_XCP_RES_DAQ_Byte62 : 503|8@0+ (1,0) [0|255] "" Vector__XXX
 SG_ STS_XCP_RES_DAQ_Byte63 : 511|8@0+ (1,0) [0|255] "" Vector__XXX

BO_ 81 FCM_XCP_CTO_RESP: 64 FCM_A0
 SG_ STS_XCP_RES_CTO_Byte0 : 7|8@0+ (1,0) [0|255] "" Vector__XXX
 SG_ STS_XCP_RES_CTO_Byte1 : 15|8@0+ (1,0) [0|255] "" Vector__XXX
 SG_ STS_XCP_RES_CTO_Byte2 : 23|8@0+ (1,0) [0|255] "" Vector__XXX
 SG_ STS_XCP_RES_CTO_Byte3 : 31|8@0+ (1,0) [0|255] "" Vector__XXX
 SG_ STS_XCP_RES_CTO_Byte4 : 39|8@0+ (1,0) [0|255] "" Vector__XXX
 SG_ STS_XCP_RES_CTO_Byte5 : 47|8@0+ (1,0) [0|255] "" Vector__XXX
 SG_ STS_XCP_RES_CTO_Byte6 : 55|8@0+ (1,0) [0|255] "" Vector__XXX
 SG_ STS_XCP_RES_CTO_Byte7 : 63|8@0+ (1,0) [0|255] "" Vector__XXX
 SG_ STS_XCP_RES_CTO_Byte8 : 71|8@0+ (1,0) [0|255] "" Vector__XXX
 SG_ STS_XCP_RES_CTO_Byte9 : 79|8@0+ (1,0) [0|255] "" Vector__XXX
 SG_ STS_XCP_RES_CTO_Byte10 : 87|8@0+ (1,0) [0|255] "" Vector__XXX
 SG_ STS_XCP_RES_CTO_Byte11 : 95|8@0+ (1,0) [0|255] "" Vector__XXX
 SG_ STS_XCP_RES_CTO_Byte12 : 103|8@0+ (1,0) [0|255] "" Vector__XXX
 SG_ STS_XCP_RES_CTO_Byte13 : 111|8@0+ (1,0) [0|255] "" Vector__XXX
 SG_ STS_XCP_RES_CTO_Byte14 : 119|8@0+ (1,0) [0|255] "" Vector__XXX
 SG_ STS_XCP_RES_CTO_Byte15 : 127|8@0+ (1,0) [0|255] "" Vector__XXX
 SG_ STS_XCP_RES_CTO_Byte16 : 135|8@0+ (1,0) [0|255] "" Vector__XXX
 SG_ STS_XCP_RES_CTO_Byte17 : 143|8@0+ (1,0) [0|255] "" Vector__XXX
 SG_ STS_XCP_RES_CTO_Byte18 : 151|8@0+ (1,0) [0|255] "" Vector__XXX
 SG_ STS_XCP_RES_CTO_Byte19 : 159|8@0+ (1,0) [0|255] "" Vector__XXX
 SG_ STS_XCP_RES_CTO_Byte20 : 167|8@0+ (1,0) [0|255] "" Vector__XXX
 SG_ STS_XCP_RES_CTO_Byte21 : 175|8@0+ (1,0) [0|255] "" Vector__XXX
 SG_ STS_XCP_RES_CTO_Byte22 : 183|8@0+ (1,0) [0|255] "" Vector__XXX
 SG_ STS_XCP_RES_CTO_Byte23 : 191|8@0+ (1,0) [0|255] "" Vector__XXX
 SG_ STS_XCP_RES_CTO_Byte24 : 199|8@0+ (1,0) [0|255] "" Vector__XXX
 SG_ STS_XCP_RES_CTO_Byte25 : 207|8@0+ (1,0) [0|255] "" Vector__XXX
 SG_ STS_XCP_RES_CTO_Byte26 : 215|8@0+ (1,0) [0|255] "" Vector__XXX
 SG_ STS_XCP_RES_CTO_Byte27 : 223|8@0+ (1,0) [0|255] "" Vector__XXX
 SG_ STS_XCP_RES_CTO_Byte28 : 231|8@0+ (1,0) [0|255] "" Vector__XXX
 SG_ STS_XCP_RES_CTO_Byte29 : 239|8@0+ (1,0) [0|255] "" Vector__XXX
 SG_ STS_XCP_RES_CTO_Byte30 : 247|8@0+ (1,0) [0|255] "" Vector__XXX
 SG_ STS_XCP_RES_CTO_Byte31 : 255|8@0+ (1,0) [0|255] "" Vector__XXX
 SG_ STS_XCP_RES_CTO_Byte32 : 263|8@0+ (1,0) [0|255] "" Vector__XXX
 SG_ STS_XCP_RES_CTO_Byte33 : 271|8@0+ (1,0) [0|255] "" Vector__XXX
 SG_ STS_XCP_RES_CTO_Byte34 : 279|8@0+ (1,0) [0|255] "" Vector__XXX
 SG_ STS_XCP_RES_CTO_Byte35 : 287|8@0+ (1,0) [0|255] "" Vector__XXX
 SG_ STS_XCP_RES_CTO_Byte36 : 295|8@0+ (1,0) [0|255] "" Vector__XXX
 SG_ STS_XCP_RES_CTO_Byte37 : 303|8@0+ (1,0) [0|255] "" Vector__XXX
 SG_ STS_XCP_RES_CTO_Byte38 : 311|8@0+ (1,0) [0|255] "" Vector__XXX
 SG_ STS_XCP_RES_CTO_Byte39 : 319|8@0+ (1,0) [0|255] "" Vector__XXX
 SG_ STS_XCP_RES_CTO_Byte40 : 327|8@0+ (1,0) [0|255] "" Vector__XXX
 SG_ STS_XCP_RES_CTO_Byte41 : 335|8@0+ (1,0) [0|255] "" Vector__XXX
 SG_ STS_XCP_RES_CTO_Byte42 : 343|8@0+ (1,0) [0|255] "" Vector__XXX
 SG_ STS_XCP_RES_CTO_Byte43 : 351|8@0+ (1,0) [0|255] "" Vector__XXX
 SG_ STS_XCP_RES_CTO_Byte44 : 359|8@0+ (1,0) [0|255] "" Vector__XXX
 SG_ STS_XCP_RES_CTO_Byte45 : 367|8@0+ (1,0) [0|255] "" Vector__XXX
 SG_ STS_XCP_RES_CTO_Byte46 : 375|8@0+ (1,0) [0|255] "" Vector__XXX
 SG_ STS_XCP_RES_CTO_Byte47 : 383|8@0+ (1,0) [0|255] "" Vector__XXX
 SG_ STS_XCP_RES_CTO_Byte48 : 391|8@0+ (1,0) [0|255] "" Vector__XXX
 SG_ STS_XCP_RES_CTO_Byte49 : 399|8@0+ (1,0) [0|255] "" Vector__XXX
 SG_ STS_XCP_RES_CTO_Byte50 : 407|8@0+ (1,0) [0|255] "" Vector__XXX
 SG_ STS_XCP_RES_CTO_Byte51 : 415|8@0+ (1,0) [0|255] "" Vector__XXX
 SG_ STS_XCP_RES_CTO_Byte52 : 423|8@0+ (1,0) [0|255] "" Vector__XXX
 SG_ STS_XCP_RES_CTO_Byte53 : 431|8@0+ (1,0) [0|255] "" Vector__XXX
 SG_ STS_XCP_RES_CTO_Byte54 : 439|8@0+ (1,0) [0|255] "" Vector__XXX
 SG_ STS_XCP_RES_CTO_Byte55 : 447|8@0+ (1,0) [0|255] "" Vector__XXX
 SG_ STS_XCP_RES_CTO_Byte56 : 455|8@0+ (1,0) [0|255] "" Vector__XXX
 SG_ STS_XCP_RES_CTO_Byte57 : 463|8@0+ (1,0) [0|255] "" Vector__XXX
 SG_ STS_XCP_RES_CTO_Byte58 : 471|8@0+ (1,0) [0|255] "" Vector__XXX
 SG_ STS_XCP_RES_CTO_Byte59 : 479|8@0+ (1,0) [0|255] "" Vector__XXX
 SG_ STS_XCP_RES_CTO_Byte60 : 487|8@0+ (1,0) [0|255] "" Vector__XXX
 SG_ STS_XCP_RES_CTO_Byte61 : 495|8@0+ (1,0) [0|255] "" Vector__XXX
 SG_ STS_XCP_RES_CTO_Byte62 : 503|8@0+ (1,0) [0|255] "" Vector__XXX
 SG_ STS_XCP_RES_CTO_Byte63 : 511|8@0+ (1,0) [0|255] "" Vector__XXX

BO_ 80 FCM_XCP_CTO_REQ: 64 Vector__XXX
 SG_ STS_XCP_REQ_CTO_Byte1 : 15|8@0+ (1,0) [0|255] ""  FCM_A0
 SG_ STS_XCP_REQ_CTO_Byte2 : 23|8@0+ (1,0) [0|255] ""  FCM_A0
 SG_ STS_XCP_REQ_CTO_Byte3 : 31|8@0+ (1,0) [0|255] ""  FCM_A0
 SG_ STS_XCP_REQ_CTO_Byte4 : 39|8@0+ (1,0) [0|255] ""  FCM_A0
 SG_ STS_XCP_REQ_CTO_Byte5 : 47|8@0+ (1,0) [0|255] ""  FCM_A0
 SG_ STS_XCP_REQ_CTO_Byte6 : 55|8@0+ (1,0) [0|255] ""  FCM_A0
 SG_ STS_XCP_REQ_CTO_Byte7 : 63|8@0+ (1,0) [0|255] ""  FCM_A0
 SG_ STS_XCP_REQ_CTO_Byte8 : 71|8@0+ (1,0) [0|255] ""  FCM_A0
 SG_ STS_XCP_REQ_CTO_Byte9 : 79|8@0+ (1,0) [0|255] ""  FCM_A0
 SG_ STS_XCP_REQ_CTO_Byte10 : 87|8@0+ (1,0) [0|255] ""  FCM_A0
 SG_ STS_XCP_REQ_CTO_Byte11 : 95|8@0+ (1,0) [0|255] ""  FCM_A0
 SG_ STS_XCP_REQ_CTO_Byte12 : 103|8@0+ (1,0) [0|255] ""  FCM_A0
 SG_ STS_XCP_REQ_CTO_Byte13 : 111|8@0+ (1,0) [0|255] ""  FCM_A0
 SG_ STS_XCP_REQ_CTO_Byte14 : 119|8@0+ (1,0) [0|255] ""  FCM_A0
 SG_ STS_XCP_REQ_CTO_Byte15 : 127|8@0+ (1,0) [0|255] ""  FCM_A0
 SG_ STS_XCP_REQ_CTO_Byte16 : 135|8@0+ (1,0) [0|255] ""  FCM_A0
 SG_ STS_XCP_REQ_CTO_Byte17 : 143|8@0+ (1,0) [0|255] ""  FCM_A0
 SG_ STS_XCP_REQ_CTO_Byte18 : 151|8@0+ (1,0) [0|255] ""  FCM_A0
 SG_ STS_XCP_REQ_CTO_Byte19 : 159|8@0+ (1,0) [0|255] ""  FCM_A0
 SG_ STS_XCP_REQ_CTO_Byte20 : 167|8@0+ (1,0) [0|255] ""  FCM_A0
 SG_ STS_XCP_REQ_CTO_Byte21 : 175|8@0+ (1,0) [0|255] ""  FCM_A0
 SG_ STS_XCP_REQ_CTO_Byte22 : 183|8@0+ (1,0) [0|255] ""  FCM_A0
 SG_ STS_XCP_REQ_CTO_Byte23 : 191|8@0+ (1,0) [0|255] ""  FCM_A0
 SG_ STS_XCP_REQ_CTO_Byte24 : 199|8@0+ (1,0) [0|255] ""  FCM_A0
 SG_ STS_XCP_REQ_CTO_Byte25 : 207|8@0+ (1,0) [0|255] ""  FCM_A0
 SG_ STS_XCP_REQ_CTO_Byte26 : 215|8@0+ (1,0) [0|255] ""  FCM_A0
 SG_ STS_XCP_REQ_CTO_Byte27 : 223|8@0+ (1,0) [0|255] ""  FCM_A0
 SG_ STS_XCP_REQ_CTO_Byte28 : 231|8@0+ (1,0) [0|255] ""  FCM_A0
 SG_ STS_XCP_REQ_CTO_Byte29 : 239|8@0+ (1,0) [0|255] ""  FCM_A0
 SG_ STS_XCP_REQ_CTO_Byte30 : 247|8@0+ (1,0) [0|255] ""  FCM_A0
 SG_ STS_XCP_REQ_CTO_Byte31 : 255|8@0+ (1,0) [0|255] ""  FCM_A0
 SG_ STS_XCP_REQ_CTO_Byte32 : 263|8@0+ (1,0) [0|255] ""  FCM_A0
 SG_ STS_XCP_REQ_CTO_Byte33 : 271|8@0+ (1,0) [0|255] ""  FCM_A0
 SG_ STS_XCP_REQ_CTO_Byte34 : 279|8@0+ (1,0) [0|255] ""  FCM_A0
 SG_ STS_XCP_REQ_CTO_Byte35 : 287|8@0+ (1,0) [0|255] ""  FCM_A0
 SG_ STS_XCP_REQ_CTO_Byte36 : 295|8@0+ (1,0) [0|255] ""  FCM_A0
 SG_ STS_XCP_REQ_CTO_Byte37 : 303|8@0+ (1,0) [0|255] ""  FCM_A0
 SG_ STS_XCP_REQ_CTO_Byte38 : 311|8@0+ (1,0) [0|255] ""  FCM_A0
 SG_ STS_XCP_REQ_CTO_Byte39 : 319|8@0+ (1,0) [0|255] ""  FCM_A0
 SG_ STS_XCP_REQ_CTO_Byte40 : 327|8@0+ (1,0) [0|255] ""  FCM_A0
 SG_ STS_XCP_REQ_CTO_Byte41 : 335|8@0+ (1,0) [0|255] ""  FCM_A0
 SG_ STS_XCP_REQ_CTO_Byte42 : 343|8@0+ (1,0) [0|255] ""  FCM_A0
 SG_ STS_XCP_REQ_CTO_Byte43 : 351|8@0+ (1,0) [0|255] ""  FCM_A0
 SG_ STS_XCP_REQ_CTO_Byte44 : 359|8@0+ (1,0) [0|255] ""  FCM_A0
 SG_ STS_XCP_REQ_CTO_Byte45 : 367|8@0+ (1,0) [0|255] ""  FCM_A0
 SG_ STS_XCP_REQ_CTO_Byte46 : 375|8@0+ (1,0) [0|255] ""  FCM_A0
 SG_ STS_XCP_REQ_CTO_Byte47 : 383|8@0+ (1,0) [0|255] ""  FCM_A0
 SG_ STS_XCP_REQ_CTO_Byte48 : 391|8@0+ (1,0) [0|255] ""  FCM_A0
 SG_ STS_XCP_REQ_CTO_Byte49 : 399|8@0+ (1,0) [0|255] ""  FCM_A0
 SG_ STS_XCP_REQ_CTO_Byte50 : 407|8@0+ (1,0) [0|255] ""  FCM_A0
 SG_ STS_XCP_REQ_CTO_Byte51 : 415|8@0+ (1,0) [0|255] ""  FCM_A0
 SG_ STS_XCP_REQ_CTO_Byte52 : 423|8@0+ (1,0) [0|255] ""  FCM_A0
 SG_ STS_XCP_REQ_CTO_Byte53 : 431|8@0+ (1,0) [0|255] ""  FCM_A0
 SG_ STS_XCP_REQ_CTO_Byte54 : 439|8@0+ (1,0) [0|255] ""  FCM_A0
 SG_ STS_XCP_REQ_CTO_Byte55 : 447|8@0+ (1,0) [0|255] ""  FCM_A0
 SG_ STS_XCP_REQ_CTO_Byte56 : 455|8@0+ (1,0) [0|255] ""  FCM_A0
 SG_ STS_XCP_REQ_CTO_Byte57 : 463|8@0+ (1,0) [0|255] ""  FCM_A0
 SG_ STS_XCP_REQ_CTO_Byte58 : 471|8@0+ (1,0) [0|255] ""  FCM_A0
 SG_ STS_XCP_REQ_CTO_Byte59 : 479|8@0+ (1,0) [0|255] ""  FCM_A0
 SG_ STS_XCP_REQ_CTO_Byte60 : 487|8@0+ (1,0) [0|255] ""  FCM_A0
 SG_ STS_XCP_REQ_CTO_Byte61 : 495|8@0+ (1,0) [0|255] ""  FCM_A0
 SG_ STS_XCP_REQ_CTO_Byte62 : 503|8@0+ (1,0) [0|255] ""  FCM_A0
 SG_ STS_XCP_REQ_CTO_Byte63 : 511|8@0+ (1,0) [0|255] ""  FCM_A0
 SG_ STS_PID : 7|8@0+ (1,0) [0|255] ""  FCM_A0

BO_ 2564530421 FCM_DIAG_REQ_FUNC_PLANT: 64 Vector__XXX
 SG_ Dummy_signal : 0|64@1+ (1,0) [0|1.84467440737096E+19] ""  FCM_A0

BO_ 2564530420 FCM_DIAG_REQ_FUNC_OTA: 64 Vector__XXX
 SG_ Dummy_signal : 0|64@1+ (1,0) [0|1.84467440737096E+19] ""  FCM_A0

BO_ 2564464885 FCM_DIAG_REQ_PHYS_PLANT: 64 Vector__XXX
 SG_ Dummy_signal : 0|64@1+ (1,0) [0|1.84467440737096E+19] ""  FCM_A0

BO_ 2564464884 FCM_DIAG_REQ_PHYS_OTA: 64 Vector__XXX
 SG_ Dummy_signal : 0|64@1+ (1,0) [0|1.84467440737096E+19] ""  FCM_A0

BO_ 2564486560 FCM_DIAG_RESP_PHYS_PLANT: 64 FCM_A0
 SG_ Dummy_signal : 0|64@1+ (1,0) [0|1.84467440737096E+19] "" Vector__XXX

BO_ 2564486304 FCM_DIAG_RESP_PHYS_OTA: 64 FCM_A0
 SG_ Dummy_signal : 0|64@1+ (1,0) [0|1.84467440737096E+19] "" Vector__XXX

BO_ 2564485536 FCM_DIAG_RESP_PHYS_OBD2: 64 FCM_A0
 SG_ Dummy_signal : 0|64@1+ (1,0) [0|1.84467440737096E+19] "" Vector__XXX

BO_ 2564485280 FCM_DIAG_RESP_PHYS_OBD1: 64 FCM_A0
 SG_ Dummy_signal : 0|64@1+ (1,0) [0|1.84467440737096E+19] "" Vector__XXX

BO_ 2564552096 FCM_DIAG_RESP_FUNC_PLANT: 8 FCM_A0
 SG_ Dummy_signal : 0|64@1+ (1,0) [0|1.84467440737096E+19] "" Vector__XXX

BO_ 2564551840 FCM_DIAG_RESP_FUNC_OTA: 8 FCM_A0
 SG_ Dummy_signal : 0|64@1+ (1,0) [0|1.84467440737096E+19] "" Vector__XXX

BO_ 2564551072 FCM_DIAG_RESP_FUNC_OBD2: 8 FCM_A0
 SG_ Dummy_signal : 0|64@1+ (1,0) [0|1.84467440737096E+19] "" Vector__XXX

BO_ 2564550816 FCM_DIAG_RESP_FUNC_OBD1: 8 FCM_A0
 SG_ Dummy_signal : 0|64@1+ (1,0) [0|1.84467440737096E+19] "" Vector__XXX

BO_ 2564464881 FCM_DIAG_REQ_PHYS_OBD2: 64 Vector__XXX
 SG_ Dummy_signal : 0|64@1+ (1,0) [0|1.84467440737096E+19] ""  FCM_A0

BO_ 2564464880 FCM_DIAG_REQ_PHYS_OBD1: 64 Vector__XXX
 SG_ Dummy_signal : 0|64@1+ (1,0) [0|1.84467440737096E+19] ""  FCM_A0

BO_ 2564530417 FCM_DIAG_REQ_FUNC_OBD2: 64 Vector__XXX
 SG_ Dummy_signal : 0|64@1+ (1,0) [0|1.84467440737096E+19] ""  FCM_A0

BO_ 2564530416 FCM_DIAG_REQ_FUNC_OBD1: 64 Vector__XXX
 SG_ Dummy_signal : 0|64@1+ (1,0) [0|1.84467440737096E+19] ""  FCM_A0

BO_ 2566843429 FLR_VI: 8 FLR
 SG_ VehicleIdentification : 0|8@1+ (1,0) [0|255] ""  SRR_RL,SRR_FL

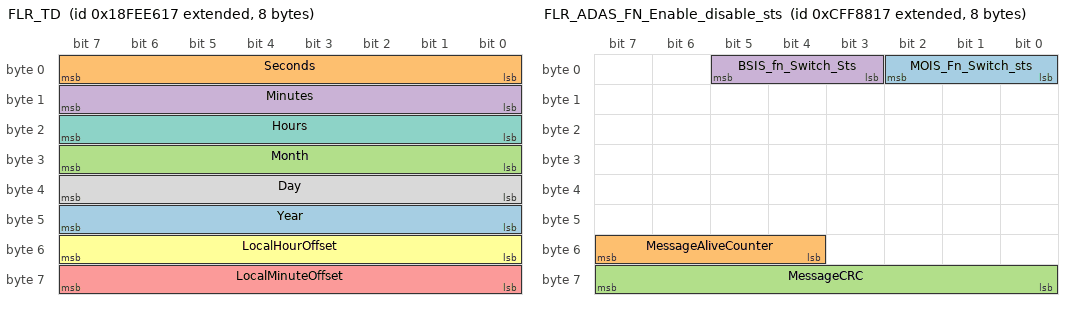
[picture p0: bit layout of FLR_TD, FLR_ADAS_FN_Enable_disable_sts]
BO_ 2566841879 FLR_TD: 8 FLR
 SG_ Year : 40|8@1+ (1,0) [0|255] "year"  SRR_RL,SRR_FL
 SG_ Seconds : 0|8@1+ (0.25,0) [0|59] "s"  SRR_RL,SRR_FL
 SG_ Month : 24|8@1+ (1,0) [0|12] "month"  SRR_RL,SRR_FL
 SG_ Minutes : 8|8@1+ (1,0) [0|59] "min"  SRR_RL,SRR_FL
 SG_ LocalMinuteOffset : 56|8@1+ (1,-125) [-23|23] "h"  SRR_RL,SRR_FL
 SG_ LocalHourOffset : 48|8@1+ (1,-125) [-59|59] "min"  SRR_RL,SRR_FL
 SG_ Hours : 16|8@1+ (1,0) [0|23] "h"  SRR_RL,SRR_FL
 SG_ Day : 32|8@1+ (0.25,0) [0|31] "day"  SRR_RL,SRR_FL

BO_ 2566848791 FLR_CLS_Tx_16: 8 FLR
 SG_ Transmission_type_info : 41|3@1+ (1,0) [0|7] ""  SRR_RL,SRR_FL
 SG_ Crawler_confi_status_info : 40|1@1+ (1,0) [0|1] ""  SRR_RL,SRR_FL

BO_ 2566869015 FLR_CLS_Tx_4: 8 FLR
 SG_ Ignition : 32|2@1+ (1,0) [0|3] ""  SRR_RL,SRR_FL
 SG_ ReverseSwitchInfo : 28|2@1+ (1,0) [0|3] ""  SRR_RL,SRR_FL

BO_ 2365556759 FLR_ADAS_FN_Enable_disable_sts: 8 FLR
 SG_ MOIS_Fn_Switch_sts : 0|3@1+ (1,0) [0|7] ""  SRR_RL,SRR_FL
 SG_ MessageAliveCounter : 52|4@1+ (1,0) [0|15] "count"  SRR_RL,SRR_FL
 SG_ MessageCRC : 56|8@1+ (1,0) [0|255] "count"  SRR_RL,SRR_FL
 SG_ BSIS_fn_Switch_Sts : 3|3@1+ (1,0) [0|7] ""  SRR_RL,SRR_FL

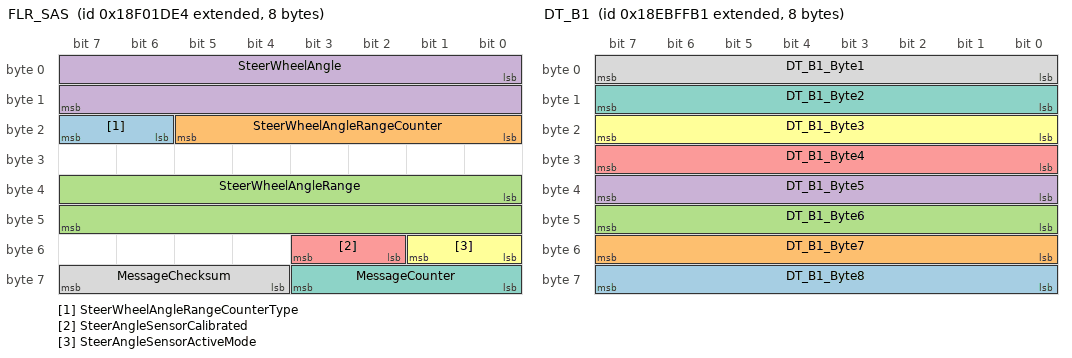
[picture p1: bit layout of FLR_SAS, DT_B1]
BO_ 2565873124 FLR_SAS: 8 FLR
 SG_ SteerWheelAngleRangeCounterType : 22|2@1+ (1,0) [0|3] ""  SRR_RL,SRR_FL
 SG_ SteerWheelAngleRangeCounter : 16|6@1+ (1,-32) [-32|29] "ranges"  SRR_RL,SRR_FL
 SG_ SteerWheelAngleRange : 32|16@1+ (0.0009765625,-31.374) [0|31.374] "rad"  SRR_RL,SRR_FL
 SG_ SteerWheelAngle : 0|16@1+ (0.0009765625,-31.374) [-31.374|31.374] "rad"  SRR_RL,SRR_FL
 SG_ SteerAngleSensorCalibrated : 50|2@1+ (1,0) [0|3] ""  SRR_RL,SRR_FL
 SG_ SteerAngleSensorActiveMode : 48|2@1+ (1,0) [0|3] ""  SRR_RL,SRR_FL
 SG_ MessageCounter : 56|4@1+ (1,0) [0|15] ""  SRR_RL,SRR_FL
 SG_ MessageChecksum : 60|4@1+ (1,0) [0|15] ""  SRR_RL,SRR_FL

BO_ 2365428224 FLR_EOI: 8 Vector__XXX
 SG_ TimeRemainingInEngOperatingState : 48|16@1+ (1,0) [0|64255] "s" Vector__XXX
 SG_ FuelPumpPrimerCtrl : 46|2@1+ (1,0) [0|3] "" Vector__XXX
 SG_ EngStarterMotorRelayCtrl : 44|2@1+ (1,0) [0|3] "" Vector__XXX
 SG_ EngOperatingState : 40|4@1+ (1,0) [0|15] "" Vector__XXX
 SG_ EngOilPrimingPumpCtrl : 38|2@1+ (1,0) [0|3] "" Vector__XXX
 SG_ EngOilPreheaterCtrl : 36|2@1+ (1,0) [0|3] "" Vector__XXX
 SG_ EngFuelShutoffVentCtrl : 34|2@1+ (1,0) [0|3] "" Vector__XXX
 SG_ EngFuelShutoffValveLeakTestCtrl : 32|2@1+ (1,0) [0|3] "" Vector__XXX
 SG_ EngFuelShutoff2Ctrl : 30|2@1+ (1,0) [0|3] "" Vector__XXX
 SG_ EngFuelShutoff1Ctrl : 28|2@1+ (1,0) [0|3] "" Vector__XXX
 SG_ EngEmergencyShutdownIndication : 26|2@1+ (1,0) [0|3] "" Vector__XXX
 SG_ EngElctrclSystmPwrCnsrvationCtrl : 24|2@1+ (1,0) [0|3] "" Vector__XXX
 SG_ EngDesiredTorqueRq : 16|8@1+ (1,-125) [0|125] "%" Vector__XXX
 SG_ EngDerateRq : 8|8@1+ (0.4,0) [0|100] "%" Vector__XXX
 SG_ EngCoolantCirculatingPumpCtrl : 6|2@1+ (1,0) [0|3] "" Vector__XXX
 SG_ EngControlledShutdownRq : 4|2@1+ (1,0) [0|3] "" Vector__XXX
 SG_ EngColdAmbientElevatedIdleStatus : 2|2@1+ (1,0) [0|3] "" Vector__XXX
 SG_ EngBlock_CoolantPreheaterCtrl : 0|2@1+ (1,0) [0|3] "" Vector__XXX

BO_ 2566840320 FLR_VD: 8 FLR
 SG_ Total_vehicle_distance : 32|32@1+ (0.125,0) [0|536870911.875] "km"  SRR_RL,SRR_FL

BO_ 2565481936 FLR_RQST: 8 Vector__XXX
 SG_ ParameterGroupNumber : 0|24@1+ (1,0) [0|16777215] "" Vector__XXX

BO_ 132 SRR_RL_STATUS_002: 64 SRR_RL
 SG_ STS_INTRFC_VERSION_ID_PATCH : 392|8@1+ (1,0) [0|255] "" Vector__XXX
 SG_ STS_INTRFC_VERSION_ID_MINOR : 384|8@1+ (1,0) [0|255] "" Vector__XXX
 SG_ STS_INTRFC_VERSION_ID_MAJOR : 376|8@1+ (1,0) [0|255] "" Vector__XXX
 SG_ STS_Yaw_Rate_Calc_QF : 142|2@1+ (1,0) [0|3] "" Vector__XXX
 SG_ STS_Vehicle_Speed_Calc_QF : 134|2@1+ (1,0) [0|3] "" Vector__XXX
 SG_ STS_Gear_Position : 59|4@1+ (1,0) [0|15] "" Vector__XXX
 SG_ STS_RAIN_COUNT : 360|9@1+ (1,0) [0|400] "" Vector__XXX
 SG_ STS_Last_CAN_Det_Inst_Latency : 336|12@1+ (0.1,0) [0|255] "ms" Vector__XXX
 SG_ STS_First_CAN_Det_Inst_Latency : 348|12@1+ (0.1,0) [0|255] "ms" Vector__XXX
 SG_ STS_CAN_NM_State : 64|8@1+ (1,0) [0|255] "" Vector__XXX
 SG_ STS_Project_ACTV_FLT_BYTE_4_to_5 : 320|16@1+ (1,0) [0|65535] "" Vector__XXX
 SG_ STS_Project_ACTV_FLT_BYTE_0_to_3 : 288|32@1+ (1,0) [0|4294967295] "" Vector__XXX
 SG_ STS_CORE_ACTV_FLT_BYTE_11_to_15 : 256|32@1+ (1,0) [0|4294967295] "" Vector__XXX
 SG_ STS_CORE_ACTV_FLT_BYTE_8_to_11 : 224|32@1+ (1,0) [0|4294967295] "" Vector__XXX
 SG_ STS_CORE_ACTV_FLT_BYTE_0_to_3 : 192|32@1+ (1,0) [0|4294967295] "" Vector__XXX
 SG_ STS_MMIC_TEMP_TX0 : 168|8@1+ (1,-50) [-50|205] "C" Vector__XXX
 SG_ STS_VEHICLE_SUPPLY_VOLTAGE : 24|4@1+ (1,0) [0|15] "" Vector__XXX
 SG_ STS_MH_002_CYCLE_COUNTER : 16|8@1+ (1,0) [0|255] "" Vector__XXX
 SG_ STS_MH_002_CRC16 : 0|16@1+ (1,0) [0|65535] "" Vector__XXX
 SG_ STS_POINT_OF_TRIGGER : 48|10@1+ (0.1,0) [0|102.3] "ms" Vector__XXX
 SG_ STS_NO_TSYN_ERROR : 40|1@1+ (1,0) [0|1] "" Vector__XXX
 SG_ STS_BRR_STATUS : 41|2@1+ (1,0) [0|2] "" Vector__XXX
 SG_ STS_MMIC_TEMP_RX : 144|8@1+ (1,-50) [-50|205] "C" Vector__XXX
 SG_ STS_MMIC_RE_INIT_COUNT : 44|4@1+ (1,0) [0|15] "" Vector__XXX
 SG_ STS_MCU_TEMP : 88|8@1+ (1,-50) [-50|205] "C" Vector__XXX
 SG_ STS_MMIC_TEMP_TX3_4 : 80|8@1+ (1,-50) [-50|205] "C" Vector__XXX
 SG_ STS_MMIC_TEMP_TX1_2 : 72|8@1+ (1,-50) [-50|205] "C" Vector__XXX
 SG_ STS_RDD_CORE_THROUGHPUT : 136|6@1+ (1.588,0) [0|100] "%" Vector__XXX
 SG_ STS_AF_CORE_THROUGHPUT : 128|6@1+ (1.588,0) [0|100] "%" Vector__XXX
 SG_ STS_SCAN_TYPE : 58|1@1+ (1,0) [0|1] "" Vector__XXX
 SG_ STS_XCVR_OPERATIONAL : 43|1@1+ (1,0) [0|1] "" Vector__XXX
 SG_ STS_YAW_RATE_BIAS : 28|4@1+ (0.025,0) [0|0.375] "rad/s" Vector__XXX
 SG_ STS_CORE_ACTV_FLT_BYTE_4_to_7 : 96|32@1+ (1,0) [0|4294967295] "" Vector__XXX
 SG_ STS_VEH_SPEED_DIRECTION : 177|1@1+ (1,0) [0|1] "" Vector__XXX
 SG_ STS_STEERING_ANGLE_SIGN : 176|1@1+ (1,0) [0|1] "" Vector__XXX
 SG_ STS_STEERING_ANGLE : 32|8@1+ (0.0174533,0) [0|3.141599] "rad" Vector__XXX
 SG_ STS_VEHICLE_SPEED_CALC : 178|14@1+ (0.01,0) [0|163.83] "m/s" Vector__XXX
 SG_ STS_TIME_SYNC_OFFSET : 152|16@1- (1,0) [-32768|32767] "us" Vector__XXX

BO_ 131 SRR_RL_STATUS_001: 64 SRR_RL
 SG_ STS_DIST_FRNT_BMPR_TO_RR_AXL : 248|13@1+ (0.001,0) [0|8.191] "m" Vector__XXX
 SG_ STS_SENSOR_POLARITY : 246|1@1+ (1,0) [0|1] "" Vector__XXX
 SG_ STS_SP_CORE_TIME_PEAK : 472|8@1+ (0.5,0) [0|127.5] "ms" Vector__XXX
 SG_ STS_SP_CORE_TIME_INST : 480|8@1+ (0.5,0) [0|127.5] "ms" Vector__XXX
 SG_ STS_RDD_CORE_TIME_PEAK : 464|8@1+ (0.5,0) [0|127.5] "ms" Vector__XXX
 SG_ STS_RDD_CORE_TIME_INST : 456|8@1+ (0.5,0) [0|127.5] "ms" Vector__XXX
 SG_ STS_MAIN_CORE_TIME_PEAK : 448|8@1+ (0.5,0) [0|127.5] "ms" Vector__XXX
 SG_ STS_MAIN_CORE_TIME_INST : 440|8@1+ (0.5,0) [0|127.5] "ms" Vector__XXX
 SG_ STS_AF_TIME_PEAK : 432|8@1+ (0.5,0) [0|127.5] "ms" Vector__XXX
 SG_ STS_AF_TIME_INST : 424|8@1+ (0.5,0) [0|127.5] "ms" Vector__XXX
 SG_ STS_PCAN_PROTOCOL_VER_MINOR : 128|8@1+ (1,0) [0|255] "" Vector__XXX
 SG_ STS_PCAN_PROTOCOL_VER_MAJOR : 120|8@1+ (1,0) [0|255] "" Vector__XXX
 SG_ STS_PLATFORM_VARIANT : 162|5@1+ (1,0) [0|18] "" Vector__XXX
 SG_ STS_HARDWARE_VERSION : 112|3@1+ (1,0) [0|5] "" Vector__XXX
 SG_ STS_SERIAL_NUMBER_SEQUENCE : 148|14@1+ (1,0) [0|9999] "" Vector__XXX
 SG_ STS_SERIAL_NUM_JULIAN_YEAR : 145|3@1+ (1,2020) [2020|2027] "years" Vector__XXX
 SG_ STS_SERIAL_NUM_JULIAN_DAY : 136|9@1+ (1,0) [0|366] "" Vector__XXX
 SG_ STS_SW_VERSION_FIELD1 : 168|8@1+ (1,0) [0|255] "" Vector__XXX
 SG_ STS_SW_VERSION_FIELD2 : 176|8@1+ (1,0) [0|255] "" Vector__XXX
 SG_ STS_SW_VERSION_FIELD3 : 184|8@1+ (1,0) [0|255] "" Vector__XXX
 SG_ STS_SW_VERSION_FIELD4 : 192|8@1+ (1,0) [0|255] "" Vector__XXX
 SG_ STS_PBL_VERSION_FIELD1 : 200|8@1+ (1,0) [0|255] "" Vector__XXX
 SG_ STS_PBL_VERSION_FIELD2 : 208|8@1+ (1,0) [0|255] "" Vector__XXX
 SG_ STS_PBL_VERSION_FIELD3 : 216|8@1+ (1,0) [0|255] "" Vector__XXX
 SG_ STS_PBL_VERSION_FIELD4 : 224|8@1+ (1,0) [0|255] "" Vector__XXX
 SG_ STS_USC_CAL_VER_MAJOR : 24|16@1+ (1,0) [0|65535] "" Vector__XXX
 SG_ STS_USC_CAL_VER_MINOR : 40|16@1+ (1,0) [0|65535] "" Vector__XXX
 SG_ STS_USC_SECTION_COMPTBLITY : 56|16@1+ (1,0) [0|255] "" Vector__XXX
 SG_ STS_SMC_CAL_VER_MAJOR : 72|16@1+ (1,0) [0|65535] "" Vector__XXX
 SG_ STS_SMC_CAL_VER_MINOR : 88|16@1+ (1,0) [0|65535] "" Vector__XXX
 SG_ STS_SMC_SECTION_COMPTBLITY : 488|16@1+ (1,0) [0|65535] "" Vector__XXX
 SG_ STS_SMC_PLATFROM_VERSION : 104|8@1+ (1,0) [0|14] "" Vector__XXX
 SG_ STS_SENSOR_MOUNT_POS_X : 296|14@1+ (0.001,-8.192) [-8.192|8.191] "m" Vector__XXX
 SG_ STS_SENSOR_MOUNT_POS_Y : 312|16@1+ (0.0001,-3.2768) [-3.2768|3.2767] "m" Vector__XXX
 SG_ STS_SENSOR_MOUNT_POS_Z : 328|16@1+ (0.0001,-3.2768) [-3.2768|3.2767] "m" Vector__XXX
 SG_ STS_SENSOR_MOUNT_ORNT_YAW : 232|14@1- (0.0004,0) [-3.14|3.14] "rad" Vector__XXX
 SG_ STS_SENSOR_MOUNT_ORNT_PITCH : 264|14@1- (0.0004,0) [-3.14|3.14] "rad" Vector__XXX
 SG_ STS_SENSOR_MOUNT_ORNT_ROLL : 280|14@1+ (0.0004,-3.14159) [-3.14159|3.41161] "rad" Vector__XXX
 SG_ STS_SENSOR_HEIGHT : 344|32@1+ (0.01,0) [0|42949672.95] "m" Vector__XXX
 SG_ STS_DET_DBC_BASE_VER_MINOR : 384|8@1+ (1,0) [0|255] "" Vector__XXX
 SG_ STS_DET_DBC_BASE_VER_MAJOR : 376|8@1+ (1,0) [0|255] "" Vector__XXX
 SG_ STS_TIME_SINCE_POWER_ON : 392|32@1+ (1,0) [0|4294967295] "s" Vector__XXX
 SG_ STS_SENSOR_POSITION : 115|3@1+ (1,0) [0|7] "" Vector__XXX
 SG_ STS_MH_001_CRC16 : 0|16@1+ (1,0) [0|65535] "" Vector__XXX
 SG_ STS_MH_001_CYCLE_COUNTER : 16|8@1+ (1,0) [0|255] "" Vector__XXX

BO_ 128 SRR_RL_HEADER_001: 64 SRR_RL
 SG_ HED_RDR_HEADER_CMAC : 472|40@1+ (1,0) [0|1099511627800] "" Vector__XXX
 SG_ HED_RDR_HEADER_FV : 416|56@1+ (1,0) [0|7.2057594038E+16] "" Vector__XXX
 SG_ HED_Rain_Level : 318|2@1+ (1,0) [0|2] "" Vector__XXX
 SG_ HED_V_WRAPPING : 197|11@1+ (0.01,-40) [-40|-19.53] "mps" Vector__XXX
 SG_ HED_R_WRAPPING : 368|8@1+ (0.01,-0.9) [-0.9|1.65] "m" Vector__XXX
 SG_ HED_Auth_CRC32 : 376|32@1+ (1,0) [0|4294967295] "" Vector__XXX
 SG_ HED_SLOPE_CORR_EXECUTIONFLAG : 172|2@1+ (1,0) [0|3] "" Vector__XXX
 SG_ HED_PROCESSED_RANGE : 160|9@1+ (1,0) [0|500] "" Vector__XXX
 SG_ HED_LOOK_INDEX : 208|16@1+ (1,0) [0|65535] "" Vector__XXX
 SG_ HED_OPERATION_MODE : 315|3@1+ (1,0) [0|5] "" Vector__XXX
 SG_ HED_MAX_NUM_OF_DETECTIONS : 352|9@1+ (1,0) [0|400] "" Vector__XXX
 SG_ HED_NUM_OF_RESTBINS_USED : 24|9@1+ (1,0) [0|511] "" Vector__XXX
 SG_ HED_NUM_OF_VALID_DETECTIONS : 33|9@1+ (1,0) [0|500] "" Vector__XXX
 SG_ HED_LOOK_ID : 42|2@1+ (1,0) [0|3] "" Vector__XXX
 SG_ HED_SCAN_INDEX : 48|16@1+ (1,0) [0|65535] "" Vector__XXX
 SG_ HED_MH_CYCLE_COUNTER : 16|8@1+ (1,0) [0|255] "" Vector__XXX
 SG_ HED_DATA_QUALIFIER : 44|3@1+ (1,0) [0|7] "" Vector__XXX
 SG_ HED_DET_RANGE_MAX : 64|16@1+ (0.01,0) [0|500] "m" Vector__XXX
 SG_ HED_DET_SPEED_RANGE_MAX : 96|16@1+ (0.00390625,-128) [-128|127.99609375] "m/s" Vector__XXX
 SG_ HED_FOV_HOR_MAX : 136|8@1+ (0.0174533,0) [0|3.14159] "rad" Vector__XXX
 SG_ HED_FOV_VER_MAX : 152|8@1+ (0.0174533,0) [0|3.14159] "rad" Vector__XXX
 SG_ HED_DET_RANGE_MIN : 80|16@1+ (0.01,0) [0|500] "m" Vector__XXX
 SG_ HED_DET_SPEED_RANGE_MIN : 112|16@1+ (0.00390625,-128) [-128|127.99609375] "m/s" Vector__XXX
 SG_ HED_FOV_HOR_MIN : 128|8@1+ (0.0174533,-2.2340224) [-2.2340224|2.2165691] "rad" Vector__XXX
 SG_ HED_FOV_VER_MIN : 144|8@1+ (0.0174533,0) [-2.2340224|2.2165691] "rad" Vector__XXX
 SG_ HED_ALIGN_VER_REF : 174|10@1+ (0.0005,-0.1745) [-0.1745|0.337] "rad" Vector__XXX
 SG_ HED_ALIGN_HOR_REF : 184|13@1+ (0.0005,-0.1745) [-0.1745|3.921] "rad" Vector__XXX
 SG_ HED_SENSOR_TIME_STAMP_NS : 224|32@1+ (1,0) [0|4294967295] "ns" Vector__XXX
 SG_ HED_SENSOR_TIME_STAMP_SEC : 256|32@1+ (1,0) [0|4294967295] "s" Vector__XXX
 SG_ HED_TIME_SYNC_SRC_MASTER : 169|1@1+ (1,0) [0|1] "" Vector__XXX
 SG_ HED_TIME_SYNC_VALIDITY_FLAG : 170|2@1+ (1,0) [0|2] "" Vector__XXX
 SG_ HED_MH_CRC16 : 0|16@1+ (1,0) [0|65535] "" Vector__XXX
 SG_ HED_DET_NUM_OF_1PASS : 296|10@1+ (1,0) [0|1023] "" Vector__XXX
 SG_ HED_DET_NUM_OF_2PASS : 306|9@1+ (1,0) [0|511] "" Vector__XXX
 SG_ HED_TRIGGER_TIME : 320|32@1+ (1,0) [0|4294967295] "ns" Vector__XXX
 SG_ HED_DET_BI_STATIC_COUNT : 288|8@1+ (1,0) [0|255] "" Vector__XXX

BO_ 2565603249 DT_B1: 8 SRR_FL
 SG_ DT_B1_Byte8 : 56|8@1+ (1,0) [0|255] ""  FLR
 SG_ DT_B1_Byte7 : 48|8@1+ (1,0) [0|255] ""  FLR
 SG_ DT_B1_Byte6 : 40|8@1+ (1,0) [0|255] ""  FLR
 SG_ DT_B1_Byte5 : 32|8@1+ (1,0) [0|255] ""  FLR
 SG_ DT_B1_Byte4 : 24|8@1+ (1,0) [0|255] ""  FLR
 SG_ DT_B1_Byte3 : 16|8@1+ (1,0) [0|255] ""  FLR
 SG_ DT_B1_Byte2 : 8|8@1+ (1,0) [0|255] ""  FLR
 SG_ DT_B1_Byte1 : 0|8@1+ (1,0) [0|255] ""  FLR

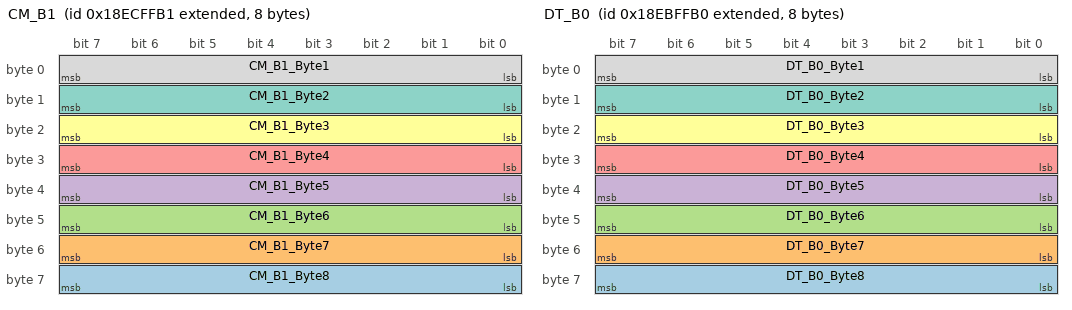
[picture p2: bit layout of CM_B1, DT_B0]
BO_ 2565668785 CM_B1: 8 SRR_FL
 SG_ CM_B1_Byte8 : 56|8@1+ (1,0) [0|255] ""  FLR
 SG_ CM_B1_Byte7 : 48|8@1+ (1,0) [0|255] ""  FLR
 SG_ CM_B1_Byte6 : 40|8@1+ (1,0) [0|255] ""  FLR
 SG_ CM_B1_Byte5 : 32|8@1+ (1,0) [0|255] ""  FLR
 SG_ CM_B1_Byte4 : 24|8@1+ (1,0) [0|255] ""  FLR
 SG_ CM_B1_Byte3 : 16|8@1+ (1,0) [0|255] ""  FLR
 SG_ CM_B1_Byte2 : 8|8@1+ (1,0) [0|255] ""  FLR
 SG_ CM_B1_Byte1 : 0|8@1+ (1,0) [0|255] ""  FLR

BO_ 2565603248 DT_B0: 8 SRR_RL
 SG_ DT_B0_Byte8 : 56|8@1+ (1,0) [0|255] ""  FLR
 SG_ DT_B0_Byte7 : 48|8@1+ (1,0) [0|255] ""  FLR
 SG_ DT_B0_Byte6 : 40|8@1+ (1,0) [0|255] ""  FLR
 SG_ DT_B0_Byte5 : 32|8@1+ (1,0) [0|255] ""  FLR
 SG_ DT_B0_Byte4 : 24|8@1+ (1,0) [0|255] ""  FLR
 SG_ DT_B0_Byte3 : 16|8@1+ (1,0) [0|255] ""  FLR
 SG_ DT_B0_Byte2 : 8|8@1+ (1,0) [0|255] ""  FLR
 SG_ DT_B0_Byte1 : 0|8@1+ (1,0) [0|255] ""  FLR

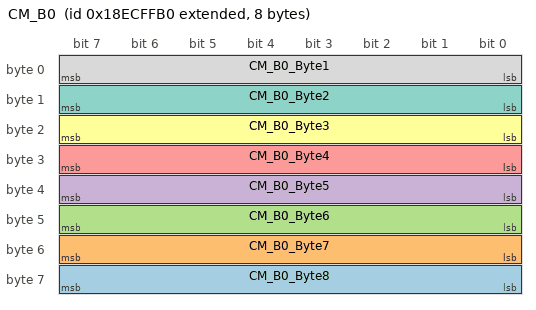
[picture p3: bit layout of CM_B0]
BO_ 2565668784 CM_B0: 8 SRR_RL
 SG_ CM_B0_Byte8 : 56|8@1+ (1,0) [0|255] ""  FLR
 SG_ CM_B0_Byte7 : 48|8@1+ (1,0) [0|255] ""  FLR
 SG_ CM_B0_Byte6 : 40|8@1+ (1,0) [0|255] ""  FLR
 SG_ CM_B0_Byte5 : 32|8@1+ (1,0) [0|255] ""  FLR
 SG_ CM_B0_Byte4 : 24|8@1+ (1,0) [0|255] ""  FLR
 SG_ CM_B0_Byte3 : 16|8@1+ (1,0) [0|255] ""  FLR
 SG_ CM_B0_Byte2 : 8|8@1+ (1,0) [0|255] ""  FLR
 SG_ CM_B0_Byte1 : 0|8@1+ (1,0) [0|255] ""  FLR

BO_ 50 FLR_XCP_DAQ_RESP: 64 FLR
 SG_ STS_XCP_RES_DAQ_Byte0 : 7|8@0+ (1,0) [0|255] ""  External_Tool
 SG_ STS_XCP_RES_DAQ_Byte1 : 15|8@0+ (1,0) [0|255] ""  External_Tool
 SG_ STS_XCP_RES_DAQ_Byte2 : 23|8@0+ (1,0) [0|255] ""  External_Tool
 SG_ STS_XCP_RES_DAQ_Byte3 : 31|8@0+ (1,0) [0|255] ""  External_Tool
 SG_ STS_XCP_RES_DAQ_Byte4 : 39|8@0+ (1,0) [0|255] ""  External_Tool
 SG_ STS_XCP_RES_DAQ_Byte5 : 47|8@0+ (1,0) [0|255] ""  External_Tool
 SG_ STS_XCP_RES_DAQ_Byte6 : 55|8@0+ (1,0) [0|255] ""  External_Tool
 SG_ STS_XCP_RES_DAQ_Byte7 : 63|8@0+ (1,0) [0|255] ""  External_Tool
 SG_ STS_XCP_RES_DAQ_Byte8 : 71|8@0+ (1,0) [0|255] ""  External_Tool
 SG_ STS_XCP_RES_DAQ_Byte9 : 79|8@0+ (1,0) [0|255] ""  External_Tool
 SG_ STS_XCP_RES_DAQ_Byte10 : 87|8@0+ (1,0) [0|255] ""  External_Tool
 SG_ STS_XCP_RES_DAQ_Byte11 : 95|8@0+ (1,0) [0|255] ""  External_Tool
 SG_ STS_XCP_RES_DAQ_Byte12 : 103|8@0+ (1,0) [0|255] ""  External_Tool
 SG_ STS_XCP_RES_DAQ_Byte13 : 111|8@0+ (1,0) [0|255] ""  External_Tool
 SG_ STS_XCP_RES_DAQ_Byte14 : 119|8@0+ (1,0) [0|255] ""  External_Tool
 SG_ STS_XCP_RES_DAQ_Byte15 : 127|8@0+ (1,0) [0|255] ""  External_Tool
 SG_ STS_XCP_RES_DAQ_Byte16 : 135|8@0+ (1,0) [0|255] ""  External_Tool
 SG_ STS_XCP_RES_DAQ_Byte17 : 143|8@0+ (1,0) [0|255] ""  External_Tool
 SG_ STS_XCP_RES_DAQ_Byte18 : 151|8@0+ (1,0) [0|255] ""  External_Tool
 SG_ STS_XCP_RES_DAQ_Byte19 : 159|8@0+ (1,0) [0|255] ""  External_Tool
 SG_ STS_XCP_RES_DAQ_Byte20 : 167|8@0+ (1,0) [0|255] ""  External_Tool
 SG_ STS_XCP_RES_DAQ_Byte21 : 175|8@0+ (1,0) [0|255] ""  External_Tool
 SG_ STS_XCP_RES_DAQ_Byte22 : 183|8@0+ (1,0) [0|255] ""  External_Tool
 SG_ STS_XCP_RES_DAQ_Byte23 : 191|8@0+ (1,0) [0|255] ""  External_Tool
 SG_ STS_XCP_RES_DAQ_Byte24 : 199|8@0+ (1,0) [0|255] ""  External_Tool
 SG_ STS_XCP_RES_DAQ_Byte25 : 207|8@0+ (1,0) [0|255] ""  External_Tool
 SG_ STS_XCP_RES_DAQ_Byte26 : 215|8@0+ (1,0) [0|255] ""  External_Tool
 SG_ STS_XCP_RES_DAQ_Byte27 : 223|8@0+ (1,0) [0|255] ""  External_Tool
 SG_ STS_XCP_RES_DAQ_Byte28 : 231|8@0+ (1,0) [0|255] ""  External_Tool
 SG_ STS_XCP_RES_DAQ_Byte29 : 239|8@0+ (1,0) [0|255] ""  External_Tool
 SG_ STS_XCP_RES_DAQ_Byte30 : 247|8@0+ (1,0) [0|255] ""  External_Tool
 SG_ STS_XCP_RES_DAQ_Byte31 : 255|8@0+ (1,0) [0|255] ""  External_Tool
 SG_ STS_XCP_RES_DAQ_Byte32 : 263|8@0+ (1,0) [0|255] ""  External_Tool
 SG_ STS_XCP_RES_DAQ_Byte33 : 271|8@0+ (1,0) [0|255] ""  External_Tool
 SG_ STS_XCP_RES_DAQ_Byte34 : 279|8@0+ (1,0) [0|255] ""  External_Tool
 SG_ STS_XCP_RES_DAQ_Byte35 : 287|8@0+ (1,0) [0|255] ""  External_Tool
 SG_ STS_XCP_RES_DAQ_Byte36 : 295|8@0+ (1,0) [0|255] ""  External_Tool
 SG_ STS_XCP_RES_DAQ_Byte37 : 303|8@0+ (1,0) [0|255] ""  External_Tool
 SG_ STS_XCP_RES_DAQ_Byte38 : 311|8@0+ (1,0) [0|255] ""  External_Tool
 SG_ STS_XCP_RES_DAQ_Byte39 : 319|8@0+ (1,0) [0|255] ""  External_Tool
 SG_ STS_XCP_RES_DAQ_Byte40 : 327|8@0+ (1,0) [0|255] ""  External_Tool
 SG_ STS_XCP_RES_DAQ_Byte41 : 335|8@0+ (1,0) [0|255] ""  External_Tool
 SG_ STS_XCP_RES_DAQ_Byte42 : 343|8@0+ (1,0) [0|255] ""  External_Tool
 SG_ STS_XCP_RES_DAQ_Byte43 : 351|8@0+ (1,0) [0|255] ""  External_Tool
 SG_ STS_XCP_RES_DAQ_Byte44 : 359|8@0+ (1,0) [0|255] ""  External_Tool
 SG_ STS_XCP_RES_DAQ_Byte45 : 367|8@0+ (1,0) [0|255] ""  External_Tool
 SG_ STS_XCP_RES_DAQ_Byte46 : 375|8@0+ (1,0) [0|255] ""  External_Tool
 SG_ STS_XCP_RES_DAQ_Byte47 : 383|8@0+ (1,0) [0|255] ""  External_Tool
 SG_ STS_XCP_RES_DAQ_Byte48 : 391|8@0+ (1,0) [0|255] ""  External_Tool
 SG_ STS_XCP_RES_DAQ_Byte49 : 399|8@0+ (1,0) [0|255] ""  External_Tool
 SG_ STS_XCP_RES_DAQ_Byte50 : 407|8@0+ (1,0) [0|255] ""  External_Tool
 SG_ STS_XCP_RES_DAQ_Byte51 : 415|8@0+ (1,0) [0|255] ""  External_Tool
 SG_ STS_XCP_RES_DAQ_Byte52 : 423|8@0+ (1,0) [0|255] ""  External_Tool
 SG_ STS_XCP_RES_DAQ_Byte53 : 431|8@0+ (1,0) [0|255] ""  External_Tool
 SG_ STS_XCP_RES_DAQ_Byte54 : 439|8@0+ (1,0) [0|255] ""  External_Tool
 SG_ STS_XCP_RES_DAQ_Byte55 : 447|8@0+ (1,0) [0|255] ""  External_Tool
 SG_ STS_XCP_RES_DAQ_Byte56 : 455|8@0+ (1,0) [0|255] ""  External_Tool
 SG_ STS_XCP_RES_DAQ_Byte57 : 463|8@0+ (1,0) [0|255] ""  External_Tool
 SG_ STS_XCP_RES_DAQ_Byte58 : 471|8@0+ (1,0) [0|255] ""  External_Tool
 SG_ STS_XCP_RES_DAQ_Byte59 : 479|8@0+ (1,0) [0|255] ""  External_Tool
 SG_ STS_XCP_RES_DAQ_Byte60 : 487|8@0+ (1,0) [0|255] ""  External_Tool
 SG_ STS_XCP_RES_DAQ_Byte61 : 495|8@0+ (1,0) [0|255] ""  External_Tool
 SG_ STS_XCP_RES_DAQ_Byte62 : 503|8@0+ (1,0) [0|255] ""  External_Tool
 SG_ STS_XCP_RES_DAQ_Byte63 : 511|8@0+ (1,0) [0|255] ""  External_Tool

BO_ 49 FLR_XCP_CTO_RESP: 64 FLR
 SG_ STS_XCP_RES_CTO_Byte0 : 7|8@0+ (1,0) [0|255] ""  External_Tool
 SG_ STS_XCP_RES_CTO_Byte1 : 15|8@0+ (1,0) [0|255] ""  External_Tool
 SG_ STS_XCP_RES_CTO_Byte2 : 23|8@0+ (1,0) [0|255] ""  External_Tool
 SG_ STS_XCP_RES_CTO_Byte3 : 31|8@0+ (1,0) [0|255] ""  External_Tool
 SG_ STS_XCP_RES_CTO_Byte4 : 39|8@0+ (1,0) [0|255] ""  External_Tool
 SG_ STS_XCP_RES_CTO_Byte5 : 47|8@0+ (1,0) [0|255] ""  External_Tool
 SG_ STS_XCP_RES_CTO_Byte6 : 55|8@0+ (1,0) [0|255] ""  External_Tool
 SG_ STS_XCP_RES_CTO_Byte7 : 63|8@0+ (1,0) [0|255] ""  External_Tool
 SG_ STS_XCP_RES_CTO_Byte8 : 71|8@0+ (1,0) [0|255] ""  External_Tool
 SG_ STS_XCP_RES_CTO_Byte9 : 79|8@0+ (1,0) [0|255] ""  External_Tool
 SG_ STS_XCP_RES_CTO_Byte10 : 87|8@0+ (1,0) [0|255] ""  External_Tool
 SG_ STS_XCP_RES_CTO_Byte11 : 95|8@0+ (1,0) [0|255] ""  External_Tool
 SG_ STS_XCP_RES_CTO_Byte12 : 103|8@0+ (1,0) [0|255] ""  External_Tool
 SG_ STS_XCP_RES_CTO_Byte13 : 111|8@0+ (1,0) [0|255] ""  External_Tool
 SG_ STS_XCP_RES_CTO_Byte14 : 119|8@0+ (1,0) [0|255] ""  External_Tool
 SG_ STS_XCP_RES_CTO_Byte15 : 127|8@0+ (1,0) [0|255] ""  External_Tool
 SG_ STS_XCP_RES_CTO_Byte16 : 135|8@0+ (1,0) [0|255] ""  External_Tool
 SG_ STS_XCP_RES_CTO_Byte17 : 143|8@0+ (1,0) [0|255] ""  External_Tool
 SG_ STS_XCP_RES_CTO_Byte18 : 151|8@0+ (1,0) [0|255] ""  External_Tool
 SG_ STS_XCP_RES_CTO_Byte19 : 159|8@0+ (1,0) [0|255] ""  External_Tool
 SG_ STS_XCP_RES_CTO_Byte20 : 167|8@0+ (1,0) [0|255] ""  External_Tool
 SG_ STS_XCP_RES_CTO_Byte21 : 175|8@0+ (1,0) [0|255] ""  External_Tool
 SG_ STS_XCP_RES_CTO_Byte22 : 183|8@0+ (1,0) [0|255] ""  External_Tool
 SG_ STS_XCP_RES_CTO_Byte23 : 191|8@0+ (1,0) [0|255] ""  External_Tool
 SG_ STS_XCP_RES_CTO_Byte24 : 199|8@0+ (1,0) [0|255] ""  External_Tool
 SG_ STS_XCP_RES_CTO_Byte25 : 207|8@0+ (1,0) [0|255] ""  External_Tool
 SG_ STS_XCP_RES_CTO_Byte26 : 215|8@0+ (1,0) [0|255] ""  External_Tool
 SG_ STS_XCP_RES_CTO_Byte27 : 223|8@0+ (1,0) [0|255] ""  External_Tool
 SG_ STS_XCP_RES_CTO_Byte28 : 231|8@0+ (1,0) [0|255] ""  External_Tool
 SG_ STS_XCP_RES_CTO_Byte29 : 239|8@0+ (1,0) [0|255] ""  External_Tool
 SG_ STS_XCP_RES_CTO_Byte30 : 247|8@0+ (1,0) [0|255] ""  External_Tool
 SG_ STS_XCP_RES_CTO_Byte31 : 255|8@0+ (1,0) [0|255] ""  External_Tool
 SG_ STS_XCP_RES_CTO_Byte32 : 263|8@0+ (1,0) [0|255] ""  External_Tool
 SG_ STS_XCP_RES_CTO_Byte33 : 271|8@0+ (1,0) [0|255] ""  External_Tool
 SG_ STS_XCP_RES_CTO_Byte34 : 279|8@0+ (1,0) [0|255] ""  External_Tool
 SG_ STS_XCP_RES_CTO_Byte35 : 287|8@0+ (1,0) [0|255] ""  External_Tool
 SG_ STS_XCP_RES_CTO_Byte36 : 295|8@0+ (1,0) [0|255] ""  External_Tool
 SG_ STS_XCP_RES_CTO_Byte37 : 303|8@0+ (1,0) [0|255] ""  External_Tool
 SG_ STS_XCP_RES_CTO_Byte38 : 311|8@0+ (1,0) [0|255] ""  External_Tool
 SG_ STS_XCP_RES_CTO_Byte39 : 319|8@0+ (1,0) [0|255] ""  External_Tool
 SG_ STS_XCP_RES_CTO_Byte40 : 327|8@0+ (1,0) [0|255] ""  External_Tool
 SG_ STS_XCP_RES_CTO_Byte41 : 335|8@0+ (1,0) [0|255] ""  External_Tool
 SG_ STS_XCP_RES_CTO_Byte42 : 343|8@0+ (1,0) [0|255] ""  External_Tool
 SG_ STS_XCP_RES_CTO_Byte43 : 351|8@0+ (1,0) [0|255] ""  External_Tool
 SG_ STS_XCP_RES_CTO_Byte44 : 359|8@0+ (1,0) [0|255] ""  External_Tool
 SG_ STS_XCP_RES_CTO_Byte45 : 367|8@0+ (1,0) [0|255] ""  External_Tool
 SG_ STS_XCP_RES_CTO_Byte46 : 375|8@0+ (1,0) [0|255] ""  External_Tool
 SG_ STS_XCP_RES_CTO_Byte47 : 383|8@0+ (1,0) [0|255] ""  External_Tool
 SG_ STS_XCP_RES_CTO_Byte48 : 391|8@0+ (1,0) [0|255] ""  External_Tool
 SG_ STS_XCP_RES_CTO_Byte49 : 399|8@0+ (1,0) [0|255] ""  External_Tool
 SG_ STS_XCP_RES_CTO_Byte50 : 407|8@0+ (1,0) [0|255] ""  External_Tool
 SG_ STS_XCP_RES_CTO_Byte51 : 415|8@0+ (1,0) [0|255] ""  External_Tool
 SG_ STS_XCP_RES_CTO_Byte52 : 423|8@0+ (1,0) [0|255] ""  External_Tool
 SG_ STS_XCP_RES_CTO_Byte53 : 431|8@0+ (1,0) [0|255] ""  External_Tool
 SG_ STS_XCP_RES_CTO_Byte54 : 439|8@0+ (1,0) [0|255] ""  External_Tool
 SG_ STS_XCP_RES_CTO_Byte55 : 447|8@0+ (1,0) [0|255] ""  External_Tool
 SG_ STS_XCP_RES_CTO_Byte56 : 455|8@0+ (1,0) [0|255] ""  External_Tool
 SG_ STS_XCP_RES_CTO_Byte57 : 463|8@0+ (1,0) [0|255] ""  External_Tool
 SG_ STS_XCP_RES_CTO_Byte58 : 471|8@0+ (1,0) [0|255] ""  External_Tool
 SG_ STS_XCP_RES_CTO_Byte59 : 479|8@0+ (1,0) [0|255] ""  External_Tool
 SG_ STS_XCP_RES_CTO_Byte60 : 487|8@0+ (1,0) [0|255] ""  External_Tool
 SG_ STS_XCP_RES_CTO_Byte61 : 495|8@0+ (1,0) [0|255] ""  External_Tool
 SG_ STS_XCP_RES_CTO_Byte62 : 503|8@0+ (1,0) [0|255] ""  External_Tool
 SG_ STS_XCP_RES_CTO_Byte63 : 511|8@0+ (1,0) [0|255] ""  External_Tool

BO_ 48 FLR_XCP_CTO_REQ: 64 External_Tool
 SG_ STS_XCP_REQ_CTO_Byte1 : 15|8@0+ (1,0) [0|255] ""  FLR
 SG_ STS_XCP_REQ_CTO_Byte2 : 23|8@0+ (1,0) [0|255] ""  FLR
 SG_ STS_XCP_REQ_CTO_Byte3 : 31|8@0+ (1,0) [0|255] ""  FLR
 SG_ STS_XCP_REQ_CTO_Byte4 : 39|8@0+ (1,0) [0|255] ""  FLR
 SG_ STS_XCP_REQ_CTO_Byte5 : 47|8@0+ (1,0) [0|255] ""  FLR
 SG_ STS_XCP_REQ_CTO_Byte6 : 55|8@0+ (1,0) [0|255] ""  FLR
 SG_ STS_XCP_REQ_CTO_Byte7 : 63|8@0+ (1,0) [0|255] ""  FLR
 SG_ STS_XCP_REQ_CTO_Byte8 : 71|8@0+ (1,0) [0|255] ""  FLR
 SG_ STS_XCP_REQ_CTO_Byte9 : 79|8@0+ (1,0) [0|255] ""  FLR
 SG_ STS_XCP_REQ_CTO_Byte10 : 87|8@0+ (1,0) [0|255] ""  FLR
 SG_ STS_XCP_REQ_CTO_Byte11 : 95|8@0+ (1,0) [0|255] ""  FLR
 SG_ STS_XCP_REQ_CTO_Byte12 : 103|8@0+ (1,0) [0|255] ""  FLR
 SG_ STS_XCP_REQ_CTO_Byte13 : 111|8@0+ (1,0) [0|255] ""  FLR
 SG_ STS_XCP_REQ_CTO_Byte14 : 119|8@0+ (1,0) [0|255] ""  FLR
 SG_ STS_XCP_REQ_CTO_Byte15 : 127|8@0+ (1,0) [0|255] ""  FLR
 SG_ STS_XCP_REQ_CTO_Byte16 : 135|8@0+ (1,0) [0|255] ""  FLR
 SG_ STS_XCP_REQ_CTO_Byte17 : 143|8@0+ (1,0) [0|255] ""  FLR
 SG_ STS_XCP_REQ_CTO_Byte18 : 151|8@0+ (1,0) [0|255] ""  FLR
 SG_ STS_XCP_REQ_CTO_Byte19 : 159|8@0+ (1,0) [0|255] ""  FLR
 SG_ STS_XCP_REQ_CTO_Byte20 : 167|8@0+ (1,0) [0|255] ""  FLR
 SG_ STS_XCP_REQ_CTO_Byte21 : 175|8@0+ (1,0) [0|255] ""  FLR
 SG_ STS_XCP_REQ_CTO_Byte22 : 183|8@0+ (1,0) [0|255] ""  FLR
 SG_ STS_XCP_REQ_CTO_Byte23 : 191|8@0+ (1,0) [0|255] ""  FLR
 SG_ STS_XCP_REQ_CTO_Byte24 : 199|8@0+ (1,0) [0|255] ""  FLR
 SG_ STS_XCP_REQ_CTO_Byte25 : 207|8@0+ (1,0) [0|255] ""  FLR
 SG_ STS_XCP_REQ_CTO_Byte26 : 215|8@0+ (1,0) [0|255] ""  FLR
 SG_ STS_XCP_REQ_CTO_Byte27 : 223|8@0+ (1,0) [0|255] ""  FLR
 SG_ STS_XCP_REQ_CTO_Byte28 : 231|8@0+ (1,0) [0|255] ""  FLR
 SG_ STS_XCP_REQ_CTO_Byte29 : 239|8@0+ (1,0) [0|255] ""  FLR
 SG_ STS_XCP_REQ_CTO_Byte30 : 247|8@0+ (1,0) [0|255] ""  FLR
 SG_ STS_XCP_REQ_CTO_Byte31 : 255|8@0+ (1,0) [0|255] ""  FLR
 SG_ STS_XCP_REQ_CTO_Byte32 : 263|8@0+ (1,0) [0|255] ""  FLR
 SG_ STS_XCP_REQ_CTO_Byte33 : 271|8@0+ (1,0) [0|255] ""  FLR
 SG_ STS_XCP_REQ_CTO_Byte34 : 279|8@0+ (1,0) [0|255] ""  FLR
 SG_ STS_XCP_REQ_CTO_Byte35 : 287|8@0+ (1,0) [0|255] ""  FLR
 SG_ STS_XCP_REQ_CTO_Byte36 : 295|8@0+ (1,0) [0|255] ""  FLR
 SG_ STS_XCP_REQ_CTO_Byte37 : 303|8@0+ (1,0) [0|255] ""  FLR
 SG_ STS_XCP_REQ_CTO_Byte38 : 311|8@0+ (1,0) [0|255] ""  FLR
 SG_ STS_XCP_REQ_CTO_Byte39 : 319|8@0+ (1,0) [0|255] ""  FLR
 SG_ STS_XCP_REQ_CTO_Byte40 : 327|8@0+ (1,0) [0|255] ""  FLR
 SG_ STS_XCP_REQ_CTO_Byte41 : 335|8@0+ (1,0) [0|255] ""  FLR
 SG_ STS_XCP_REQ_CTO_Byte42 : 343|8@0+ (1,0) [0|255] ""  FLR
 SG_ STS_XCP_REQ_CTO_Byte43 : 351|8@0+ (1,0) [0|255] ""  FLR
 SG_ STS_XCP_REQ_CTO_Byte44 : 359|8@0+ (1,0) [0|255] ""  FLR
 SG_ STS_XCP_REQ_CTO_Byte45 : 367|8@0+ (1,0) [0|255] ""  FLR
 SG_ STS_XCP_REQ_CTO_Byte46 : 375|8@0+ (1,0) [0|255] ""  FLR
 SG_ STS_XCP_REQ_CTO_Byte47 : 383|8@0+ (1,0) [0|255] ""  FLR
 SG_ STS_XCP_REQ_CTO_Byte48 : 391|8@0+ (1,0) [0|255] ""  FLR
 SG_ STS_XCP_REQ_CTO_Byte49 : 399|8@0+ (1,0) [0|255] ""  FLR
 SG_ STS_XCP_REQ_CTO_Byte50 : 407|8@0+ (1,0) [0|255] ""  FLR
 SG_ STS_XCP_REQ_CTO_Byte51 : 415|8@0+ (1,0) [0|255] ""  FLR
 SG_ STS_XCP_REQ_CTO_Byte52 : 423|8@0+ (1,0) [0|255] ""  FLR
 SG_ STS_XCP_REQ_CTO_Byte53 : 431|8@0+ (1,0) [0|255] ""  FLR
 SG_ STS_XCP_REQ_CTO_Byte54 : 439|8@0+ (1,0) [0|255] ""  FLR
 SG_ STS_XCP_REQ_CTO_Byte55 : 447|8@0+ (1,0) [0|255] ""  FLR
 SG_ STS_XCP_REQ_CTO_Byte56 : 455|8@0+ (1,0) [0|255] ""  FLR
 SG_ STS_XCP_REQ_CTO_Byte57 : 463|8@0+ (1,0) [0|255] ""  FLR
 SG_ STS_XCP_REQ_CTO_Byte58 : 471|8@0+ (1,0) [0|255] ""  FLR
 SG_ STS_XCP_REQ_CTO_Byte59 : 479|8@0+ (1,0) [0|255] ""  FLR
 SG_ STS_XCP_REQ_CTO_Byte60 : 487|8@0+ (1,0) [0|255] ""  FLR
 SG_ STS_XCP_REQ_CTO_Byte61 : 495|8@0+ (1,0) [0|255] ""  FLR
 SG_ STS_XCP_REQ_CTO_Byte62 : 503|8@0+ (1,0) [0|255] ""  FLR
 SG_ STS_XCP_REQ_CTO_Byte63 : 511|8@0+ (1,0) [0|255] ""  FLR
 SG_ STS_PID : 7|8@0+ (1,0) [0|255] ""  FLR

BO_ 18 SRR_RL_XCP_DAQ_RESP: 64 SRR_RL
 SG_ STS_XCP_RES_DAQ_Byte0 : 7|8@0+ (1,0) [0|255] ""  External_Tool
 SG_ STS_XCP_RES_DAQ_Byte1 : 15|8@0+ (1,0) [0|255] ""  External_Tool
 SG_ STS_XCP_RES_DAQ_Byte2 : 23|8@0+ (1,0) [0|255] ""  External_Tool
 SG_ STS_XCP_RES_DAQ_Byte3 : 31|8@0+ (1,0) [0|255] ""  External_Tool
 SG_ STS_XCP_RES_DAQ_Byte4 : 39|8@0+ (1,0) [0|255] ""  External_Tool
 SG_ STS_XCP_RES_DAQ_Byte5 : 47|8@0+ (1,0) [0|255] ""  External_Tool
 SG_ STS_XCP_RES_DAQ_Byte6 : 55|8@0+ (1,0) [0|255] ""  External_Tool
 SG_ STS_XCP_RES_DAQ_Byte7 : 63|8@0+ (1,0) [0|255] ""  External_Tool
 SG_ STS_XCP_RES_DAQ_Byte8 : 71|8@0+ (1,0) [0|255] ""  External_Tool
 SG_ STS_XCP_RES_DAQ_Byte9 : 79|8@0+ (1,0) [0|255] ""  External_Tool
 SG_ STS_XCP_RES_DAQ_Byte10 : 87|8@0+ (1,0) [0|255] ""  External_Tool
 SG_ STS_XCP_RES_DAQ_Byte11 : 95|8@0+ (1,0) [0|255] ""  External_Tool
 SG_ STS_XCP_RES_DAQ_Byte12 : 103|8@0+ (1,0) [0|255] ""  External_Tool
 SG_ STS_XCP_RES_DAQ_Byte13 : 111|8@0+ (1,0) [0|255] ""  External_Tool
 SG_ STS_XCP_RES_DAQ_Byte14 : 119|8@0+ (1,0) [0|255] ""  External_Tool
 SG_ STS_XCP_RES_DAQ_Byte15 : 127|8@0+ (1,0) [0|255] ""  External_Tool
 SG_ STS_XCP_RES_DAQ_Byte16 : 135|8@0+ (1,0) [0|255] ""  External_Tool
 SG_ STS_XCP_RES_DAQ_Byte17 : 143|8@0+ (1,0) [0|255] ""  External_Tool
 SG_ STS_XCP_RES_DAQ_Byte18 : 151|8@0+ (1,0) [0|255] ""  External_Tool
 SG_ STS_XCP_RES_DAQ_Byte19 : 159|8@0+ (1,0) [0|255] ""  External_Tool
 SG_ STS_XCP_RES_DAQ_Byte20 : 167|8@0+ (1,0) [0|255] ""  External_Tool
 SG_ STS_XCP_RES_DAQ_Byte21 : 175|8@0+ (1,0) [0|255] ""  External_Tool
 SG_ STS_XCP_RES_DAQ_Byte22 : 183|8@0+ (1,0) [0|255] ""  External_Tool
 SG_ STS_XCP_RES_DAQ_Byte23 : 191|8@0+ (1,0) [0|255] ""  External_Tool
 SG_ STS_XCP_RES_DAQ_Byte24 : 199|8@0+ (1,0) [0|255] ""  External_Tool
 SG_ STS_XCP_RES_DAQ_Byte25 : 207|8@0+ (1,0) [0|255] ""  External_Tool
 SG_ STS_XCP_RES_DAQ_Byte26 : 215|8@0+ (1,0) [0|255] ""  External_Tool
 SG_ STS_XCP_RES_DAQ_Byte27 : 223|8@0+ (1,0) [0|255] ""  External_Tool
 SG_ STS_XCP_RES_DAQ_Byte28 : 231|8@0+ (1,0) [0|255] ""  External_Tool
 SG_ STS_XCP_RES_DAQ_Byte29 : 239|8@0+ (1,0) [0|255] ""  External_Tool
 SG_ STS_XCP_RES_DAQ_Byte30 : 247|8@0+ (1,0) [0|255] ""  External_Tool
 SG_ STS_XCP_RES_DAQ_Byte31 : 255|8@0+ (1,0) [0|255] ""  External_Tool
 SG_ STS_XCP_RES_DAQ_Byte32 : 263|8@0+ (1,0) [0|255] ""  External_Tool
 SG_ STS_XCP_RES_DAQ_Byte33 : 271|8@0+ (1,0) [0|255] ""  External_Tool
 SG_ STS_XCP_RES_DAQ_Byte34 : 279|8@0+ (1,0) [0|255] ""  External_Tool
 SG_ STS_XCP_RES_DAQ_Byte35 : 287|8@0+ (1,0) [0|255] ""  External_Tool
 SG_ STS_XCP_RES_DAQ_Byte36 : 295|8@0+ (1,0) [0|255] ""  External_Tool
 SG_ STS_XCP_RES_DAQ_Byte37 : 303|8@0+ (1,0) [0|255] ""  External_Tool
 SG_ STS_XCP_RES_DAQ_Byte38 : 311|8@0+ (1,0) [0|255] ""  External_Tool
 SG_ STS_XCP_RES_DAQ_Byte39 : 319|8@0+ (1,0) [0|255] ""  External_Tool
 SG_ STS_XCP_RES_DAQ_Byte40 : 327|8@0+ (1,0) [0|255] ""  External_Tool
 SG_ STS_XCP_RES_DAQ_Byte41 : 335|8@0+ (1,0) [0|255] ""  External_Tool
 SG_ STS_XCP_RES_DAQ_Byte42 : 343|8@0+ (1,0) [0|255] ""  External_Tool
 SG_ STS_XCP_RES_DAQ_Byte43 : 351|8@0+ (1,0) [0|255] ""  External_Tool
 SG_ STS_XCP_RES_DAQ_Byte44 : 359|8@0+ (1,0) [0|255] ""  External_Tool
 SG_ STS_XCP_RES_DAQ_Byte45 : 367|8@0+ (1,0) [0|255] ""  External_Tool
 SG_ STS_XCP_RES_DAQ_Byte46 : 375|8@0+ (1,0) [0|255] ""  External_Tool
 SG_ STS_XCP_RES_DAQ_Byte47 : 383|8@0+ (1,0) [0|255] ""  External_Tool
 SG_ STS_XCP_RES_DAQ_Byte48 : 391|8@0+ (1,0) [0|255] ""  External_Tool
 SG_ STS_XCP_RES_DAQ_Byte49 : 399|8@0+ (1,0) [0|255] ""  External_Tool
 SG_ STS_XCP_RES_DAQ_Byte50 : 407|8@0+ (1,0) [0|255] ""  External_Tool
 SG_ STS_XCP_RES_DAQ_Byte51 : 415|8@0+ (1,0) [0|255] ""  External_Tool
 SG_ STS_XCP_RES_DAQ_Byte52 : 423|8@0+ (1,0) [0|255] ""  External_Tool
 SG_ STS_XCP_RES_DAQ_Byte53 : 431|8@0+ (1,0) [0|255] ""  External_Tool
 SG_ STS_XCP_RES_DAQ_Byte54 : 439|8@0+ (1,0) [0|255] ""  External_Tool
 SG_ STS_XCP_RES_DAQ_Byte55 : 447|8@0+ (1,0) [0|255] ""  External_Tool
 SG_ STS_XCP_RES_DAQ_Byte56 : 455|8@0+ (1,0) [0|255] ""  External_Tool
 SG_ STS_XCP_RES_DAQ_Byte57 : 463|8@0+ (1,0) [0|255] ""  External_Tool
 SG_ STS_XCP_RES_DAQ_Byte58 : 471|8@0+ (1,0) [0|255] ""  External_Tool
 SG_ STS_XCP_RES_DAQ_Byte59 : 479|8@0+ (1,0) [0|255] ""  External_Tool
 SG_ STS_XCP_RES_DAQ_Byte60 : 487|8@0+ (1,0) [0|255] ""  External_Tool
 SG_ STS_XCP_RES_DAQ_Byte61 : 495|8@0+ (1,0) [0|255] ""  External_Tool
 SG_ STS_XCP_RES_DAQ_Byte62 : 503|8@0+ (1,0) [0|255] ""  External_Tool
 SG_ STS_XCP_RES_DAQ_Byte63 : 511|8@0+ (1,0) [0|255] ""  External_Tool

BO_ 17 SRR_RL_XCP_CTO_RESP: 64 SRR_RL
 SG_ STS_XCP_RES_CTO_Byte0 : 7|8@0+ (1,0) [0|255] ""  External_Tool
 SG_ STS_XCP_RES_CTO_Byte1 : 15|8@0+ (1,0) [0|255] ""  External_Tool
 SG_ STS_XCP_RES_CTO_Byte2 : 23|8@0+ (1,0) [0|255] ""  External_Tool
 SG_ STS_XCP_RES_CTO_Byte3 : 31|8@0+ (1,0) [0|255] ""  External_Tool
 SG_ STS_XCP_RES_CTO_Byte4 : 39|8@0+ (1,0) [0|255] ""  External_Tool
 SG_ STS_XCP_RES_CTO_Byte5 : 47|8@0+ (1,0) [0|255] ""  External_Tool
 SG_ STS_XCP_RES_CTO_Byte6 : 55|8@0+ (1,0) [0|255] ""  External_Tool
 SG_ STS_XCP_RES_CTO_Byte7 : 63|8@0+ (1,0) [0|255] ""  External_Tool
 SG_ STS_XCP_RES_CTO_Byte8 : 71|8@0+ (1,0) [0|255] ""  External_Tool
 SG_ STS_XCP_RES_CTO_Byte9 : 79|8@0+ (1,0) [0|255] ""  External_Tool
 SG_ STS_XCP_RES_CTO_Byte10 : 87|8@0+ (1,0) [0|255] ""  External_Tool
 SG_ STS_XCP_RES_CTO_Byte11 : 95|8@0+ (1,0) [0|255] ""  External_Tool
 SG_ STS_XCP_RES_CTO_Byte12 : 103|8@0+ (1,0) [0|255] ""  External_Tool
 SG_ STS_XCP_RES_CTO_Byte13 : 111|8@0+ (1,0) [0|255] ""  External_Tool
 SG_ STS_XCP_RES_CTO_Byte14 : 119|8@0+ (1,0) [0|255] ""  External_Tool
 SG_ STS_XCP_RES_CTO_Byte15 : 127|8@0+ (1,0) [0|255] ""  External_Tool
 SG_ STS_XCP_RES_CTO_Byte16 : 135|8@0+ (1,0) [0|255] ""  External_Tool
 SG_ STS_XCP_RES_CTO_Byte17 : 143|8@0+ (1,0) [0|255] ""  External_Tool
 SG_ STS_XCP_RES_CTO_Byte18 : 151|8@0+ (1,0) [0|255] ""  External_Tool
 SG_ STS_XCP_RES_CTO_Byte19 : 159|8@0+ (1,0) [0|255] ""  External_Tool
 SG_ STS_XCP_RES_CTO_Byte20 : 167|8@0+ (1,0) [0|255] ""  External_Tool
 SG_ STS_XCP_RES_CTO_Byte21 : 175|8@0+ (1,0) [0|255] ""  External_Tool
 SG_ STS_XCP_RES_CTO_Byte22 : 183|8@0+ (1,0) [0|255] ""  External_Tool
 SG_ STS_XCP_RES_CTO_Byte23 : 191|8@0+ (1,0) [0|255] ""  External_Tool
 SG_ STS_XCP_RES_CTO_Byte24 : 199|8@0+ (1,0) [0|255] ""  External_Tool
 SG_ STS_XCP_RES_CTO_Byte25 : 207|8@0+ (1,0) [0|255] ""  External_Tool
 SG_ STS_XCP_RES_CTO_Byte26 : 215|8@0+ (1,0) [0|255] ""  External_Tool
 SG_ STS_XCP_RES_CTO_Byte27 : 223|8@0+ (1,0) [0|255] ""  External_Tool
 SG_ STS_XCP_RES_CTO_Byte28 : 231|8@0+ (1,0) [0|255] ""  External_Tool
 SG_ STS_XCP_RES_CTO_Byte29 : 239|8@0+ (1,0) [0|255] ""  External_Tool
 SG_ STS_XCP_RES_CTO_Byte30 : 247|8@0+ (1,0) [0|255] ""  External_Tool
 SG_ STS_XCP_RES_CTO_Byte31 : 255|8@0+ (1,0) [0|255] ""  External_Tool
 SG_ STS_XCP_RES_CTO_Byte32 : 263|8@0+ (1,0) [0|255] ""  External_Tool
 SG_ STS_XCP_RES_CTO_Byte33 : 271|8@0+ (1,0) [0|255] ""  External_Tool
 SG_ STS_XCP_RES_CTO_Byte34 : 279|8@0+ (1,0) [0|255] ""  External_Tool
 SG_ STS_XCP_RES_CTO_Byte35 : 287|8@0+ (1,0) [0|255] ""  External_Tool
 SG_ STS_XCP_RES_CTO_Byte36 : 295|8@0+ (1,0) [0|255] ""  External_Tool
 SG_ STS_XCP_RES_CTO_Byte37 : 303|8@0+ (1,0) [0|255] ""  External_Tool
 SG_ STS_XCP_RES_CTO_Byte38 : 311|8@0+ (1,0) [0|255] ""  External_Tool
 SG_ STS_XCP_RES_CTO_Byte39 : 319|8@0+ (1,0) [0|255] ""  External_Tool
 SG_ STS_XCP_RES_CTO_Byte40 : 327|8@0+ (1,0) [0|255] ""  External_Tool
 SG_ STS_XCP_RES_CTO_Byte41 : 335|8@0+ (1,0) [0|255] ""  External_Tool
 SG_ STS_XCP_RES_CTO_Byte42 : 343|8@0+ (1,0) [0|255] ""  External_Tool
 SG_ STS_XCP_RES_CTO_Byte43 : 351|8@0+ (1,0) [0|255] ""  External_Tool
 SG_ STS_XCP_RES_CTO_Byte44 : 359|8@0+ (1,0) [0|255] ""  External_Tool
 SG_ STS_XCP_RES_CTO_Byte45 : 367|8@0+ (1,0) [0|255] ""  External_Tool
 SG_ STS_XCP_RES_CTO_Byte46 : 375|8@0+ (1,0) [0|255] ""  External_Tool
 SG_ STS_XCP_RES_CTO_Byte47 : 383|8@0+ (1,0) [0|255] ""  External_Tool
 SG_ STS_XCP_RES_CTO_Byte48 : 391|8@0+ (1,0) [0|255] ""  External_Tool
 SG_ STS_XCP_RES_CTO_Byte49 : 399|8@0+ (1,0) [0|255] ""  External_Tool
 SG_ STS_XCP_RES_CTO_Byte50 : 407|8@0+ (1,0) [0|255] ""  External_Tool
 SG_ STS_XCP_RES_CTO_Byte51 : 415|8@0+ (1,0) [0|255] ""  External_Tool
 SG_ STS_XCP_RES_CTO_Byte52 : 423|8@0+ (1,0) [0|255] ""  External_Tool
 SG_ STS_XCP_RES_CTO_Byte53 : 431|8@0+ (1,0) [0|255] ""  External_Tool
 SG_ STS_XCP_RES_CTO_Byte54 : 439|8@0+ (1,0) [0|255] ""  External_Tool
 SG_ STS_XCP_RES_CTO_Byte55 : 447|8@0+ (1,0) [0|255] ""  External_Tool
 SG_ STS_XCP_RES_CTO_Byte56 : 455|8@0+ (1,0) [0|255] ""  External_Tool
 SG_ STS_XCP_RES_CTO_Byte57 : 463|8@0+ (1,0) [0|255] ""  External_Tool
 SG_ STS_XCP_RES_CTO_Byte58 : 471|8@0+ (1,0) [0|255] ""  External_Tool
 SG_ STS_XCP_RES_CTO_Byte59 : 479|8@0+ (1,0) [0|255] ""  External_Tool
 SG_ STS_XCP_RES_CTO_Byte60 : 487|8@0+ (1,0) [0|255] ""  External_Tool
 SG_ STS_XCP_RES_CTO_Byte61 : 495|8@0+ (1,0) [0|255] ""  External_Tool
 SG_ STS_XCP_RES_CTO_Byte62 : 503|8@0+ (1,0) [0|255] ""  External_Tool
 SG_ STS_XCP_RES_CTO_Byte63 : 511|8@0+ (1,0) [0|255] ""  External_Tool

BO_ 16 SRR_RL_XCP_CTO_REQ: 64 External_Tool
 SG_ STS_XCP_REQ_CTO_Byte1 : 15|8@0+ (1,0) [0|255] ""  SRR_RL
 SG_ STS_XCP_REQ_CTO_Byte2 : 23|8@0+ (1,0) [0|255] ""  SRR_RL
 SG_ STS_XCP_REQ_CTO_Byte3 : 31|8@0+ (1,0) [0|255] ""  SRR_RL
 SG_ STS_XCP_REQ_CTO_Byte4 : 39|8@0+ (1,0) [0|255] ""  SRR_RL
 SG_ STS_XCP_REQ_CTO_Byte5 : 47|8@0+ (1,0) [0|255] ""  SRR_RL
 SG_ STS_XCP_REQ_CTO_Byte6 : 55|8@0+ (1,0) [0|255] ""  SRR_RL
 SG_ STS_XCP_REQ_CTO_Byte7 : 63|8@0+ (1,0) [0|255] ""  SRR_RL
 SG_ STS_XCP_REQ_CTO_Byte8 : 71|8@0+ (1,0) [0|255] ""  SRR_RL
 SG_ STS_XCP_REQ_CTO_Byte9 : 79|8@0+ (1,0) [0|255] ""  SRR_RL
 SG_ STS_XCP_REQ_CTO_Byte10 : 87|8@0+ (1,0) [0|255] ""  SRR_RL
 SG_ STS_XCP_REQ_CTO_Byte11 : 95|8@0+ (1,0) [0|255] ""  SRR_RL
 SG_ STS_XCP_REQ_CTO_Byte12 : 103|8@0+ (1,0) [0|255] ""  SRR_RL
 SG_ STS_XCP_REQ_CTO_Byte13 : 111|8@0+ (1,0) [0|255] ""  SRR_RL
 SG_ STS_XCP_REQ_CTO_Byte14 : 119|8@0+ (1,0) [0|255] ""  SRR_RL
 SG_ STS_XCP_REQ_CTO_Byte15 : 127|8@0+ (1,0) [0|255] ""  SRR_RL
 SG_ STS_XCP_REQ_CTO_Byte16 : 135|8@0+ (1,0) [0|255] ""  SRR_RL
 SG_ STS_XCP_REQ_CTO_Byte17 : 143|8@0+ (1,0) [0|255] ""  SRR_RL
 SG_ STS_XCP_REQ_CTO_Byte18 : 151|8@0+ (1,0) [0|255] ""  SRR_RL
 SG_ STS_XCP_REQ_CTO_Byte19 : 159|8@0+ (1,0) [0|255] ""  SRR_RL
 SG_ STS_XCP_REQ_CTO_Byte20 : 167|8@0+ (1,0) [0|255] ""  SRR_RL
 SG_ STS_XCP_REQ_CTO_Byte21 : 175|8@0+ (1,0) [0|255] ""  SRR_RL
 SG_ STS_XCP_REQ_CTO_Byte22 : 183|8@0+ (1,0) [0|255] ""  SRR_RL
 SG_ STS_XCP_REQ_CTO_Byte23 : 191|8@0+ (1,0) [0|255] ""  SRR_RL
 SG_ STS_XCP_REQ_CTO_Byte24 : 199|8@0+ (1,0) [0|255] ""  SRR_RL
 SG_ STS_XCP_REQ_CTO_Byte25 : 207|8@0+ (1,0) [0|255] ""  SRR_RL
 SG_ STS_XCP_REQ_CTO_Byte26 : 215|8@0+ (1,0) [0|255] ""  SRR_RL
 SG_ STS_XCP_REQ_CTO_Byte27 : 223|8@0+ (1,0) [0|255] ""  SRR_RL
 SG_ STS_XCP_REQ_CTO_Byte28 : 231|8@0+ (1,0) [0|255] ""  SRR_RL
 SG_ STS_XCP_REQ_CTO_Byte29 : 239|8@0+ (1,0) [0|255] ""  SRR_RL
 SG_ STS_XCP_REQ_CTO_Byte30 : 247|8@0+ (1,0) [0|255] ""  SRR_RL
 SG_ STS_XCP_REQ_CTO_Byte31 : 255|8@0+ (1,0) [0|255] ""  SRR_RL
 SG_ STS_XCP_REQ_CTO_Byte32 : 263|8@0+ (1,0) [0|255] ""  SRR_RL
 SG_ STS_XCP_REQ_CTO_Byte33 : 271|8@0+ (1,0) [0|255] ""  SRR_RL
 SG_ STS_XCP_REQ_CTO_Byte34 : 279|8@0+ (1,0) [0|255] ""  SRR_RL
 SG_ STS_XCP_REQ_CTO_Byte35 : 287|8@0+ (1,0) [0|255] ""  SRR_RL
 SG_ STS_XCP_REQ_CTO_Byte36 : 295|8@0+ (1,0) [0|255] ""  SRR_RL
 SG_ STS_XCP_REQ_CTO_Byte37 : 303|8@0+ (1,0) [0|255] ""  SRR_RL
 SG_ STS_XCP_REQ_CTO_Byte38 : 311|8@0+ (1,0) [0|255] ""  SRR_RL
 SG_ STS_XCP_REQ_CTO_Byte39 : 319|8@0+ (1,0) [0|255] ""  SRR_RL
 SG_ STS_XCP_REQ_CTO_Byte40 : 327|8@0+ (1,0) [0|255] ""  SRR_RL
 SG_ STS_XCP_REQ_CTO_Byte41 : 335|8@0+ (1,0) [0|255] ""  SRR_RL
 SG_ STS_XCP_REQ_CTO_Byte42 : 343|8@0+ (1,0) [0|255] ""  SRR_RL
 SG_ STS_XCP_REQ_CTO_Byte43 : 351|8@0+ (1,0) [0|255] ""  SRR_RL
 SG_ STS_XCP_REQ_CTO_Byte44 : 359|8@0+ (1,0) [0|255] ""  SRR_RL
 SG_ STS_XCP_REQ_CTO_Byte45 : 367|8@0+ (1,0) [0|255] ""  SRR_RL
 SG_ STS_XCP_REQ_CTO_Byte46 : 375|8@0+ (1,0) [0|255] ""  SRR_RL
 SG_ STS_XCP_REQ_CTO_Byte47 : 383|8@0+ (1,0) [0|255] ""  SRR_RL
 SG_ STS_XCP_REQ_CTO_Byte48 : 391|8@0+ (1,0) [0|255] ""  SRR_RL
 SG_ STS_XCP_REQ_CTO_Byte49 : 399|8@0+ (1,0) [0|255] ""  SRR_RL
 SG_ STS_XCP_REQ_CTO_Byte50 : 407|8@0+ (1,0) [0|255] ""  SRR_RL
 SG_ STS_XCP_REQ_CTO_Byte51 : 415|8@0+ (1,0) [0|255] ""  SRR_RL
 SG_ STS_XCP_REQ_CTO_Byte52 : 423|8@0+ (1,0) [0|255] ""  SRR_RL
 SG_ STS_XCP_REQ_CTO_Byte53 : 431|8@0+ (1,0) [0|255] ""  SRR_RL
 SG_ STS_XCP_REQ_CTO_Byte54 : 439|8@0+ (1,0) [0|255] ""  SRR_RL
 SG_ STS_XCP_REQ_CTO_Byte55 : 447|8@0+ (1,0) [0|255] ""  SRR_RL
 SG_ STS_XCP_REQ_CTO_Byte56 : 455|8@0+ (1,0) [0|255] ""  SRR_RL
 SG_ STS_XCP_REQ_CTO_Byte57 : 463|8@0+ (1,0) [0|255] ""  SRR_RL
 SG_ STS_XCP_REQ_CTO_Byte58 : 471|8@0+ (1,0) [0|255] ""  SRR_RL
 SG_ STS_XCP_REQ_CTO_Byte59 : 479|8@0+ (1,0) [0|255] ""  SRR_RL
 SG_ STS_XCP_REQ_CTO_Byte60 : 487|8@0+ (1,0) [0|255] ""  SRR_RL
 SG_ STS_XCP_REQ_CTO_Byte61 : 495|8@0+ (1,0) [0|255] ""  SRR_RL
 SG_ STS_XCP_REQ_CTO_Byte62 : 503|8@0+ (1,0) [0|255] ""  SRR_RL
 SG_ STS_XCP_REQ_CTO_Byte63 : 511|8@0+ (1,0) [0|255] ""  SRR_RL
 SG_ STS_PID : 7|8@0+ (1,0) [0|255] ""  SRR_RL

BO_ 2564486576 SRR_RL_DIAG_RESP_PHYS_PLANT: 64 SRR_RL
 SG_ Dummy_signal : 0|64@1+ (1,0) [0|1.84467440737096E+19] ""  FLR

BO_ 2564486320 SRR_RL_DIAG_RESP_PHYS_OTA: 64 SRR_RL
 SG_ Dummy_signal : 0|64@1+ (1,0) [0|1.84467440737096E+19] ""  FLR

BO_ 2564485552 SRR_RL_DIAG_RESP_PHYS_OBD2: 64 SRR_RL
 SG_ Dummy_signal : 0|64@1+ (1,0) [0|1.84467440737096E+19] ""  FLR

BO_ 2564485296 SRR_RL_DIAG_RESP_PHYS_OBD1: 64 SRR_RL
 SG_ Dummy_signal : 0|64@1+ (1,0) [0|1.84467440737096E+19] ""  FLR

BO_ 2564552112 SRR_RL_DIAG_RESP_FNC_PLANT: 64 Vector__XXX
 SG_ Dummy_signal : 0|64@1+ (1,0) [0|1.84467440737096E+19] "" Vector__XXX

BO_ 2564551856 SRR_RL_DIAG_RESP_FNC_OTA: 64 Vector__XXX
 SG_ Dummy_signal : 0|64@1+ (1,0) [0|1.84467440737096E+19] "" Vector__XXX

BO_ 2564551088 SRR_RL_DIAG_RESP_FNC_OBD2: 64 Vector__XXX
 SG_ Dummy_signal : 0|64@1+ (1,0) [0|1.84467440737096E+19] "" Vector__XXX

BO_ 2564550832 SRR_RL_DIAG_RESP_FNC_OBD1: 64 Vector__XXX
 SG_ Dummy_signal : 0|64@1+ (1,0) [0|1.84467440737096E+19] "" Vector__XXX

BO_ 2564468981 SRR_RL_DIAG_REQ_PHYS_PLANT: 64 FLR
 SG_ Dummy_signal : 0|64@1+ (1,0) [0|1.84467440737096E+19] ""  SRR_RL

BO_ 2564468980 SRR_RL_DIAG_REQ_PHYS_OTA: 64 FLR
 SG_ Dummy_signal : 0|64@1+ (1,0) [0|1.84467440737096E+19] ""  SRR_RL

BO_ 2564468976 SRR_RL_DIAG_REQ_PHYS_OBD1: 64 FLR
 SG_ Dummy_signal : 0|64@1+ (1,0) [0|1.84467440737096E+19] ""  SRR_RL

BO_ 2564468977 SRR_RL_DIAG_REQ_PHYS_OBD2: 64 FLR
 SG_ Dummy_signal : 0|64@1+ (1,0) [0|1.84467440737096E+19] ""  SRR_RL

BO_ 2564534517 SRR_RL_DIAG_REQ_FUNC_PLANT: 64 FLR
 SG_ Dummy_signal : 0|64@1+ (1,0) [0|1.84467440737096E+19] "" Vector__XXX

BO_ 2564534516 SRR_RL_DIAG_REQ_FUNC_OTA: 64 FLR
 SG_ Dummy_signal : 0|64@1+ (1,0) [0|1.84467440737096E+19] "" Vector__XXX

BO_ 2564534513 SRR_RL_DIAG_REQ_FUNC_OBD2: 64 FLR
 SG_ Dummy_signal : 0|64@1+ (1,0) [0|1.84467440737096E+19] "" Vector__XXX

BO_ 2564534512 SRR_RL_DIAG_REQ_FUNC_OBD1: 64 FLR
 SG_ Dummy_signal : 0|64@1+ (1,0) [0|1.84467440737096E+19] "" Vector__XXX

BO_ 2564534773 SRR_FL_DIAG_REQ_FUNC_PLANT: 64 FLR
 SG_ Dummy_signal : 0|64@1+ (1,0) [0|1.84467440737096E+19] "" Vector__XXX

BO_ 2564534772 SRR_FL_DIAG_REQ_FUNC_OTA: 64 FLR
 SG_ Dummy_signal : 0|64@1+ (1,0) [0|1.84467440737096E+19] "" Vector__XXX

BO_ 2564534768 SRR_FL_DIAG_REQ_FUNC_OBD1: 64 FLR
 SG_ Dummy_signal : 0|64@1+ (1,0) [0|1.84467440737096E+19] "" Vector__XXX

BO_ 2564534769 SRR_FL_DIAG_REQ_FUNC_OBD2: 64 FLR
 SG_ Dummy_signal : 0|64@1+ (1,0) [0|1.84467440737096E+19] "" Vector__XXX

BO_ 2564486577 SRR_FL_DIAG_RESP_PHYS_PLANT: 64 SRR_FL
 SG_ Dummy_signal : 0|64@1+ (1,0) [0|1.84467440737096E+19] ""  FLR

BO_ 2564486321 SRR_FL_DIAG_RESP_PHYS_OTA: 64 SRR_FL
 SG_ Dummy_signal : 0|64@1+ (1,0) [0|1.84467440737096E+19] ""  FLR

BO_ 2564485553 SRR_FL_DIAG_RESP_PHYS_OBD2: 64 SRR_FL
 SG_ Dummy_signal : 0|64@1+ (1,0) [0|1.84467440737096E+19] ""  FLR

BO_ 2564485297 SRR_FL_DIAG_RESP_PHYS_OBD1: 64 SRR_FL
 SG_ Dummy_signal : 0|64@1+ (1,0) [0|1.84467440737096E+19] ""  FLR

BO_ 2564552113 SRR_FL_DIAG_RESP_FNC_PLANT: 64 Vector__XXX
 SG_ Dummy_signal : 0|64@1+ (1,0) [0|1.84467440737096E+19] "" Vector__XXX

BO_ 2564551857 SRR_FL_DIAG_RESP_FNC_OTA: 64 Vector__XXX
 SG_ Dummy_signal : 0|64@1+ (1,0) [0|1.84467440737096E+19] "" Vector__XXX

BO_ 2564551089 SRR_FL_DIAG_RESP_FNC_OBD2: 64 Vector__XXX
 SG_ Dummy_signal : 0|64@1+ (1,0) [0|1.84467440737096E+19] "" Vector__XXX

BO_ 2564550833 SRR_FL_DIAG_RESP_FNC_OBD1: 64 Vector__XXX
 SG_ Dummy_signal : 0|64@1+ (1,0) [0|1.84467440737096E+19] "" Vector__XXX

BO_ 2564469237 SRR_FL_DIAG_REQ_PHYS_PLANT: 64 FLR
 SG_ Dummy_signal : 0|64@1+ (1,0) [0|1.84467440737096E+19] ""  SRR_FL

BO_ 2564469236 SRR_FL_DIAG_REQ_PHYS_OTA: 64 FLR
 SG_ Dummy_signal : 0|64@1+ (1,0) [0|1.84467440737096E+19] ""  SRR_FL

BO_ 2564486352 FLR_DIAG_RESP_PHYS_OTA: 64 FLR
 SG_ Dummy_signal : 0|64@1+ (1,0) [0|1.84467440737096E+19] ""  External_Tool

BO_ 2564486608 FLR_DIAG_RESP_PHYS_PLANT: 64 FLR
 SG_ Dummy_signal : 0|64@1+ (1,0) [0|1.84467440737096E+19] ""  External_Tool

BO_ 2564477173 FLR_DIAG_REQ_PHYS_PLANT: 64 External_Tool
 SG_ Dummy_signal : 0|64@1+ (1,0) [0|1.84467440737096E+19] ""  FLR

BO_ 2564477172 FLR_DIAG_REQ_PHYS_OTA: 64 External_Tool
 SG_ Dummy_signal : 0|64@1+ (1,0) [0|1.84467440737096E+19] ""  FLR

BO_ 2564477169 FLR_DIAG_REQ_PHYS_OBD2: 64 External_Tool
 SG_ Dummy_signal : 0|64@1+ (1,0) [0|1.84467440737096E+19] ""  FLR

BO_ 2564477168 FLR_DIAG_REQ_PHYS_OBD1: 64 External_Tool
 SG_ Dummy_signal : 0|64@1+ (1,0) [0|1.84467440737096E+19] ""  FLR

BO_ 2564542709 FLR_DIAG10: 64 Vector__XXX
 SG_ Dummy_signal : 0|64@1+ (1,0) [0|1.84467440737096E+19] "" Vector__XXX

BO_ 2564542708 FLR_DIAG12: 64 Vector__XXX
 SG_ Dummy_signal : 0|64@1+ (1,0) [0|1.84467440737096E+19] "" Vector__XXX

BO_ 2564552144 FLR_DIAG_RESP_FUNC_PLANT: 64 FLR
 SG_ Dummy_signal : 0|64@1+ (1,0) [0|1.84467440737096E+19] ""  External_Tool

BO_ 2564551888 FLR_DIAG_RESP_FUNC_OTA: 64 FLR
 SG_ Dummy_signal : 0|64@1+ (1,0) [0|1.84467440737096E+19] ""  External_Tool

BO_ 2564551120 FLR_DIAG_RESP_FUNC_OBD2: 64 FLR
 SG_ Dummy_signal : 0|64@1+ (1,0) [0|1.84467440737096E+19] ""  External_Tool

BO_ 2564550864 FLR_DIAG_RESP_FUNC_OBD1: 64 FLR
 SG_ Dummy_signal : 0|64@1+ (1,0) [0|1.84467440737096E+19] ""  External_Tool

BO_ 2565517591 RQST_17_SRR_FL: 3 FLR
 SG_ ParameterGroupNumber : 0|24@1+ (1,0) [0|16777215] ""  SRR_FL

BO_ 2565517335 RQST_17_SRR_RL: 3 FLR
 SG_ ParameterGroupNumber : 0|24@1+ (1,0) [0|16777215] ""  SRR_RL

BO_ 2565481904 SRR_RL_RQST_B0: 3 SRR_RL
 SG_ ParameterGroupNumber : 0|24@1+ (1,0) [0|16777215] ""  FLR

BO_ 2565481905 SRR_FL_RQST_B1: 3 SRR_FL
 SG_ ParameterGroupNumber : 0|24@1+ (1,0) [0|16777215] ""  FLR

BO_ 2566838961 SRR_FL_SOFT_B1: 8 SRR_FL
 SG_ SoftIdentification_FR : 8|8@1+ (1,0) [0|0] ""  FLR
 SG_ NumberOfSWIdentifierFields_FR : 0|8@1+ (1,0) [0|255] ""  FLR

BO_ 2566838960 SRR_RL_SOFT_B0: 8 SRR_RL
 SG_ SoftIdentification_FR : 8|8@1+ (1,0) [0|0] ""  FLR
 SG_ NumberOfSWIdentifierFields_FR : 0|8@1+ (1,0) [0|255] ""  FLR

BO_ 164 FLR_STATUS_002: 64 FLR
 SG_ STS_INTRFC_VERSION_ID_PATCH : 392|8@1+ (1,0) [0|255] ""  FCM_A0
 SG_ STS_INTRFC_VERSION_ID_MINOR : 384|8@1+ (1,0) [0|255] ""  FCM_A0
 SG_ STS_INTRFC_VERSION_ID_MAJOR : 376|8@1+ (1,0) [0|255] ""  FCM_A0
 SG_ STS_Yaw_Rate_Calc_QF : 142|2@1+ (1,0) [0|3] ""  FCM_A0
 SG_ STS_Vehicle_Speed_Calc_QF : 134|2@1+ (1,0) [0|3] ""  FCM_A0
 SG_ STS_Gear_Position : 59|4@1+ (1,0) [0|15] ""  FCM_A0
 SG_ STS_RAIN_COUNT : 360|9@1+ (1,0) [0|400] ""  FCM_A0
 SG_ STS_Last_CAN_Det_Inst_Latency : 336|12@1+ (0.1,0) [0|255] "ms"  FCM_A0
 SG_ STS_First_CAN_Det_Inst_Latency : 348|12@1+ (0.1,0) [0|255] "ms"  FCM_A0
 SG_ STS_CAN_NM_State : 64|8@1+ (1,0) [0|255] ""  FCM_A0
 SG_ STS_Project_ACTV_FLT_BYTE_4_to_5 : 320|16@1+ (1,0) [0|65535] ""  FCM_A0
 SG_ STS_Project_ACTV_FLT_BYTE_0_to_3 : 288|32@1+ (1,0) [0|4294967295] ""  FCM_A0
 SG_ STS_CORE_ACTV_FLT_BYTE_11_to_15 : 256|32@1+ (1,0) [0|4294967295] ""  FCM_A0
 SG_ STS_CORE_ACTV_FLT_BYTE_8_to_11 : 224|32@1+ (1,0) [0|4294967295] ""  FCM_A0
 SG_ STS_CORE_ACTV_FLT_BYTE_0_to_3 : 192|32@1+ (1,0) [0|4294967295] ""  FCM_A0
 SG_ STS_MMIC_TEMP_TX0 : 168|8@1+ (1,-50) [-50|205] "C"  FCM_A0
 SG_ STS_VEHICLE_SUPPLY_VOLTAGE : 24|4@1+ (1,0) [0|15] ""  FCM_A0
 SG_ STS_MH_002_CYCLE_COUNTER : 16|8@1+ (1,0) [0|255] ""  FCM_A0
 SG_ STS_MH_002_CRC16 : 0|16@1+ (1,0) [0|65535] ""  FCM_A0
 SG_ STS_POINT_OF_TRIGGER : 48|10@1+ (0.1,0) [0|102.3] "ms"  FCM_A0
 SG_ STS_NO_TSYN_ERROR : 40|1@1+ (1,0) [0|1] ""  FCM_A0
 SG_ STS_BRR_STATUS : 41|2@1+ (1,0) [0|2] ""  FCM_A0
 SG_ STS_MMIC_TEMP_RX : 144|8@1+ (1,-50) [-50|205] "C"  FCM_A0
 SG_ STS_MMIC_RE_INIT_COUNT : 44|4@1+ (1,0) [0|15] ""  FCM_A0
 SG_ STS_MCU_TEMP : 88|8@1+ (1,-50) [-50|205] "C"  FCM_A0
 SG_ STS_MMIC_TEMP_TX3_4 : 80|8@1+ (1,-50) [-50|205] "C"  FCM_A0
 SG_ STS_MMIC_TEMP_TX1_2 : 72|8@1+ (1,-50) [-50|205] "C"  FCM_A0
 SG_ STS_RDD_CORE_THROUGHPUT : 136|6@1+ (1.588,0) [0|100] "%"  FCM_A0
 SG_ STS_AF_CORE_THROUGHPUT : 128|6@1+ (1.588,0) [0|100] "%"  FCM_A0
 SG_ STS_SCAN_TYPE : 58|1@1+ (1,0) [0|1] ""  FCM_A0
 SG_ STS_XCVR_OPERATIONAL : 43|1@1+ (1,0) [0|1] ""  FCM_A0
 SG_ STS_YAW_RATE_BIAS : 28|4@1+ (0.025,0) [0|0.375] "rad/s"  FCM_A0
 SG_ STS_CORE_ACTV_FLT_BYTE_4_to_7 : 96|32@1+ (1,0) [0|4294967295] ""  FCM_A0
 SG_ STS_VEH_SPEED_DIRECTION : 177|1@1+ (1,0) [0|1] ""  FCM_A0
 SG_ STS_STEERING_ANGLE_SIGN : 176|1@1+ (1,0) [0|1] ""  FCM_A0
 SG_ STS_STEERING_ANGLE : 32|8@1+ (0.0174533,0) [0|3.141599] "rad"  FCM_A0
 SG_ STS_VEHICLE_SPEED_CALC : 178|14@1+ (0.01,0) [0|163.83] "m/s"  FCM_A0
 SG_ STS_TIME_SYNC_OFFSET : 152|16@1- (1,0) [-32768|32767] "us"  FCM_A0

CM_ BO_ 3221225472 "This is a message for not used signals, created by Vector CANdb++ DBC OLE DB Provider.";
CM_ SG_ 3221225472 STS_AF_TIME_PEAK "Angle Finding Latency peak";
CM_ SG_ 3221225472 STS_AF_TIME_INST "Angle Finding Latency instantaneous";
CM_ SG_ 3221225472 STS_SW_VERSION_FIELD1 "Release_Number is incremented for major every release";
CM_ SG_ 3221225472 STS_SW_VERSION_FIELD2 "Promote_Revision, increment with every promote or minor release";
CM_ SG_ 3221225472 STS_SW_VERSION_FIELD3 "Field_Revision  or Variant number";
CM_ SG_ 3221225472 STS_SW_VERSION_FIELD4 "Increment with SW patch release";
CM_ SG_ 3221225472 STS_PBL_VERSION_FIELD1 "Release_Number is incremented for major every release";
CM_ SG_ 3221225472 STS_PBL_VERSION_FIELD2 "Promote_Revision, increment with every promote or minor release";
CM_ SG_ 3221225472 STS_PBL_VERSION_FIELD3 "Field_Revision  or Variant number";
CM_ SG_ 3221225472 STS_PBL_VERSION_FIELD4 "Increment with patch release";
CM_ SG_ 3221225472 STS_SMC_SECTION_COMPTBLITY "Section compatiblity bits as specified in EXEC spec";
CM_ SG_ 3221225472 STS_SMC_PLATFROM_VERSION "Variant ID";
CM_ SG_ 3221225472 STS_SENSOR_MOUNT_POS_X "Correction of the mounting position w.r.t. the optimal position. Correction is determined by calibration";
CM_ SG_ 3221225472 STS_SENSOR_MOUNT_ORNT_PITCH "Correction of the mounting position orientation w.r.t. the optimal orientation";
CM_ SG_ 3221225472 STS_SENSOR_HEIGHT "Radar height from ground to center of radar elevation field-of-view";
CM_ SG_ 3221225472 STS_DET_DBC_BASE_VER_MINOR "Detection base dbc Minor version";
CM_ SG_ 3221225472 STS_DET_DBC_BASE_VER_MAJOR "Detection base dbc Major version";
CM_ SG_ 3221225472 STS_INTRFC_VERSION_ID_PATCH "Version number for patch";
CM_ SG_ 3221225472 STS_INTRFC_VERSION_ID_MINOR "Version number for minor";
CM_ SG_ 3221225472 STS_INTRFC_VERSION_ID_MAJOR "Version number for major";
CM_ SG_ 3221225472 STS_POINT_OF_TRIGGER "Delay betwen TymSyc message received and actual trigger";
CM_ SG_ 3221225472 STS_BRR_STATUS "Current status of BRR , active/inactive/fault";
CM_ SG_ 3221225472 STS_MMIC_TEMP_TX1_2 "Internal MMIC Temperature #1";
CM_ SG_ 3221225472 STS_XCVR_OPERATIONAL "Indication that the transceiver is operational";
CM_ SG_ 3221225472 STS_VEH_SPEED_DIRECTION "Provides indication of vehicle direction of travel";
CM_ SG_ 3221225472 STS_STEERING_ANGLE_SIGN "Actual steering angle direction, from the centre position of the steering wheel.";
CM_ SG_ 3221225472 STS_STEERING_ANGLE "Actual steering wheel angle. Datum (zero) of the steering wheel position is determined at the time of calibration in the factory.   This is only the magnitude of the steering wheel angle.";
CM_ SG_ 3221225472 STS_VEHICLE_SPEED_CALC "Vehicle speed";
CM_ SG_ 3221225472 STS_TIME_SYNC_OFFSET "Current offset from desired Time Sync Sync point";
CM_ SG_ 3221225472 HED_NUM_OF_VALID_DETECTIONS "The current number of valid detections in the detections list";
CM_ SG_ 3221225472 HED_LOOK_ID "Indicates the look type values 1 to 4 base on medium/long look and near/far look. Each radar scan is a look.";
CM_ SG_ 3221225472 HED_SCAN_INDEX "Scan index";
CM_ SG_ 3221225472 HED_MH_CYCLE_COUNTER "ALIVE counter";
CM_ SG_ 3221225472 HED_DATA_QUALIFIER "Data qualifier communicates the overall availability of the interface or expresses to what extent the content of this event can be relied on ";
CM_ SG_ 3221225472 HED_DET_RANGE_MAX "Detection range max is the farthest possible detection with respect to the sensor origin.";
CM_ SG_ 3221225472 HED_DET_SPEED_RANGE_MAX "Describes the relative radial speed range in the sensor coordinate system. Range is defined by
two range values: negative values indicate lower speed than the ego-vehicle, positive values
indicate higher velocity than ego-vehicle";
CM_ SG_ 3221225472 HED_FOV_HOR_MAX "Field of view defined by opening angles in sensor XY-plane.";
CM_ SG_ 3221225472 HED_FOV_VER_MAX "Field of view defined by opening angles in sensor XZ-plane.";
CM_ SG_ 3221225472 HED_DET_RANGE_MIN "Detection range max is the Closest possible detection with respect to the sensor origin.";
CM_ SG_ 3221225472 HED_DET_SPEED_RANGE_MIN "Describes the relative radial speed range in the sensor coordinate system. Range is defined by
two range values: negative values indicate lower speed than the ego-vehicle, positive values
indicate higher velocity than ego-vehicle";
CM_ SG_ 3221225472 HED_FOV_HOR_MIN "Field of view defined by opening angles in sensor XY-plane.";
CM_ SG_ 3221225472 HED_FOV_VER_MIN "Field of view defined by opening angles in sensor XZ-plane.";
CM_ SG_ 3221225472 HED_ALIGN_HOR_REF "Alignment horizontal reference";
CM_ SG_ 3221225472 HED_SENSOR_TIME_STAMP_NS "sensor absolute time when the radar measurement was taken";
CM_ SG_ 3221225472 HED_TIME_SYNC_SRC_MASTER "Indicate if sensor is synch to global master or local master";
CM_ SG_ 3221225472 HED_TIME_SYNC_VALIDITY_FLAG "indicates the validity of Time Sync message data";
CM_ SG_ 3221225472 HED_TRIGGER_TIME "Data Acquisition start time";
CM_ SG_ 132 STS_INTRFC_VERSION_ID_PATCH "Version number for patch";
CM_ SG_ 132 STS_INTRFC_VERSION_ID_MINOR "Version number for minor";
CM_ SG_ 132 STS_INTRFC_VERSION_ID_MAJOR "Version number for major";
CM_ SG_ 132 STS_POINT_OF_TRIGGER "Delay betwen TymSyc message received and actual trigger";
CM_ SG_ 132 STS_BRR_STATUS "Current status of BRR , active/inactive/fault";
CM_ SG_ 132 STS_MMIC_TEMP_TX1_2 "Internal MMIC Temperature #1";
CM_ SG_ 132 STS_XCVR_OPERATIONAL "Indication that the transceiver is operational";
CM_ SG_ 132 STS_VEH_SPEED_DIRECTION "Provides indication of vehicle direction of travel";
CM_ SG_ 132 STS_STEERING_ANGLE_SIGN "Actual steering angle direction, from the centre position of the steering wheel.";
CM_ SG_ 132 STS_STEERING_ANGLE "Actual steering wheel angle. Datum (zero) of the steering wheel position is determined at the time of calibration in the factory.   This is only the magnitude of the steering wheel angle.";
CM_ SG_ 132 STS_VEHICLE_SPEED_CALC "Vehicle speed";
CM_ SG_ 132 STS_TIME_SYNC_OFFSET "Current offset from desired Time Sync Sync point";
CM_ SG_ 131 STS_AF_TIME_PEAK "Angle Finding Latency peak";
CM_ SG_ 131 STS_AF_TIME_INST "Angle Finding Latency instantaneous";
CM_ SG_ 131 STS_SW_VERSION_FIELD1 "Release_Number is incremented for major every release";
CM_ SG_ 131 STS_SW_VERSION_FIELD2 "Promote_Revision, increment with every promote or minor release";
CM_ SG_ 131 STS_SW_VERSION_FIELD3 "Field_Revision  or Variant number";
CM_ SG_ 131 STS_SW_VERSION_FIELD4 "Increment with SW patch release";
CM_ SG_ 131 STS_PBL_VERSION_FIELD1 "Release_Number is incremented for major every release";
CM_ SG_ 131 STS_PBL_VERSION_FIELD2 "Promote_Revision, increment with every promote or minor release";
CM_ SG_ 131 STS_PBL_VERSION_FIELD3 "Field_Revision  or Variant number";
CM_ SG_ 131 STS_PBL_VERSION_FIELD4 "Increment with patch release";
CM_ SG_ 131 STS_SMC_SECTION_COMPTBLITY "Section compatiblity bits as specified in EXEC spec";
CM_ SG_ 131 STS_SMC_PLATFROM_VERSION "Variant ID";
CM_ SG_ 131 STS_SENSOR_MOUNT_POS_X "Correction of the mounting position w.r.t. the optimal position. Correction is determined by calibration";
CM_ SG_ 131 STS_SENSOR_MOUNT_ORNT_PITCH "Correction of the mounting position orientation w.r.t. the optimal orientation";
CM_ SG_ 131 STS_SENSOR_HEIGHT "Radar height from ground to center of radar elevation field-of-view";
CM_ SG_ 131 STS_DET_DBC_BASE_VER_MINOR "Detection base dbc Minor version";
CM_ SG_ 131 STS_DET_DBC_BASE_VER_MAJOR "Detection base dbc Major version";
CM_ SG_ 128 HED_NUM_OF_VALID_DETECTIONS "The current number of valid detections in the detections list";
CM_ SG_ 128 HED_LOOK_ID "Indicates the look type values 1 to 4 base on medium/long look and near/far look. Each radar scan is a look.";
CM_ SG_ 128 HED_SCAN_INDEX "Scan index";
CM_ SG_ 128 HED_MH_CYCLE_COUNTER "ALIVE counter";
CM_ SG_ 128 HED_DATA_QUALIFIER "Data qualifier communicates the overall availability of the interface or expresses to what extent the content of this event can be relied on ";
CM_ SG_ 128 HED_DET_RANGE_MAX "Detection range max is the farthest possible detection with respect to the sensor origin.";
CM_ SG_ 128 HED_DET_SPEED_RANGE_MAX "Describes the relative radial speed range in the sensor coordinate system. Range is defined by
two range values: negative values indicate lower speed than the ego-vehicle, positive values
indicate higher velocity than ego-vehicle";
CM_ SG_ 128 HED_FOV_HOR_MAX "Field of view defined by opening angles in sensor XY-plane.";
CM_ SG_ 128 HED_FOV_VER_MAX "Field of view defined by opening angles in sensor XZ-plane.";
CM_ SG_ 128 HED_DET_RANGE_MIN "Detection range max is the Closest possible detection with respect to the sensor origin.";
CM_ SG_ 128 HED_DET_SPEED_RANGE_MIN "Describes the relative radial speed range in the sensor coordinate system. Range is defined by
two range values: negative values indicate lower speed than the ego-vehicle, positive values
indicate higher velocity than ego-vehicle";
CM_ SG_ 128 HED_FOV_HOR_MIN "Field of view defined by opening angles in sensor XY-plane.";
CM_ SG_ 128 HED_FOV_VER_MIN "Field of view defined by opening angles in sensor XZ-plane.";
CM_ SG_ 128 HED_ALIGN_HOR_REF "Alignment horizontal reference";
CM_ SG_ 128 HED_SENSOR_TIME_STAMP_NS "sensor absolute time when the radar measurement was taken";
CM_ SG_ 128 HED_TIME_SYNC_SRC_MASTER "Indicate if sensor is synch to global master or local master";
CM_ SG_ 128 HED_TIME_SYNC_VALIDITY_FLAG "indicates the validity of Time Sync message data";
CM_ SG_ 128 HED_TRIGGER_TIME "Data Acquisition start time";
CM_ SG_ 164 STS_INTRFC_VERSION_ID_PATCH "Version number for patch";
CM_ SG_ 164 STS_INTRFC_VERSION_ID_MINOR "Version number for minor";
CM_ SG_ 164 STS_INTRFC_VERSION_ID_MAJOR "Version number for major";
CM_ SG_ 164 STS_POINT_OF_TRIGGER "Delay betwen TymSyc message received and actual trigger";
CM_ SG_ 164 STS_BRR_STATUS "Current status of BRR , active/inactive/fault";
CM_ SG_ 164 STS_MMIC_TEMP_TX1_2 "Internal MMIC Temperature #1";
CM_ SG_ 164 STS_XCVR_OPERATIONAL "Indication that the transceiver is operational";
CM_ SG_ 164 STS_VEH_SPEED_DIRECTION "Provides indication of vehicle direction of travel";
CM_ SG_ 164 STS_STEERING_ANGLE_SIGN "Actual steering angle direction, from the centre position of the steering wheel.";
CM_ SG_ 164 STS_STEERING_ANGLE "Actual steering wheel angle. Datum (zero) of the steering wheel position is determined at the time of calibration in the factory.   This is only the magnitude of the steering wheel angle.";
CM_ SG_ 164 STS_VEHICLE_SPEED_CALC "Vehicle speed";
CM_ SG_ 164 STS_TIME_SYNC_OFFSET "Current offset from desired Time Sync Sync point";
BA_DEF_ BO_  "CanTpBs" INT 0 255;
BA_DEF_ BO_  "DiagRequest" ENUM  "No","Yes";
BA_DEF_ BO_  "DiagResponse" ENUM  "No","Yes";
BA_DEF_ BO_  "E2EDataId" INT 0 65535;
BA_DEF_ BO_  "E2EDataLength" INT 0 65535;
BA_DEF_ BO_  "E2EProfile" STRING ;
BA_DEF_ BO_  "EventRateOfChange" INT 10 10000;
BA_DEF_ BO_  "GenMsgCycleTime" INT 0 100000;
BA_DEF_ BO_  "GenMsgILSupport" ENUM  "No","Yes";
BA_DEF_ BO_  "GenMsgNrOfRepetition" INT 0 100;
BA_DEF_ BO_  "GenMsgSendType" ENUM  "FixedPeriodic","Event","EnabledPeriodic","NotUsed","NotUsed","EventPeriodic","NotUsed","NotUsed","NoMsgSendType";
BA_DEF_ BO_  "MessageGateway" ENUM  "No","Yes";
BA_DEF_ BO_  "NetworkInitialization" ENUM  "No","Yes";
BA_DEF_ BO_  "SCP_AuthInfoTxLength" INT 0 512;
BA_DEF_ BO_  "SCP_DataId" INT 0 65535;
BA_DEF_ BO_  "SCP_FreshnessValueId" INT 0 65535;
BA_DEF_ BO_  "SCP_FreshnessValueLength" INT 0 512;
BA_DEF_ BO_  "SCP_FreshnessValueTxLength" INT 0 512;
BA_DEF_ BO_  "SC_Message" ENUM  "No","Yes","Yes, split message";
BA_DEF_ BO_  "VFrameFormat" ENUM  "StandardCAN","ExtendedCAN","reserved","reserved","reserved","reserved","reserved","reserved","reserved","reserved","reserved","reserved","reserved","reserved","StandardCAN_FD","ExtendedCAN_FD";
BA_DEF_ SG_  "GenSigCmt" STRING ;
BA_DEF_ SG_  "GenSigCycleTime" INT 0 0;
BA_DEF_ SG_  "GenSigSendType" ENUM  "Cyclic","OnWrite","vector_leerstring","OnChange","vector_leerstring","IfActive","vector_leerstring","NoSigSendType";
BA_DEF_ SG_  "GenSigStartValue" INT 0 1000000000;
BA_DEF_ SG_  "GenSigTimeoutTime" INT 0 0;
BA_DEF_ SG_  "InvalidValue" STRING ;
BA_DEF_ BU_  "NmAsrNodeIdentifier" HEX 128 255;
BA_DEF_ BU_  "NmStationAddress" HEX 0 0;
BA_DEF_ BU_  "NodeStartUpTime" INT 0 10000;
BA_DEF_ BU_  "NodeWakeUpTime" INT 0 10000;
BA_DEF_ BU_  "PowerType" ENUM  "Switched","Latched","Sleep","vector_leerstring","vector_leerstring";
BA_DEF_  "Baudrate" INT 0 2000000;
BA_DEF_  "BaudrateCANFD" INT 0 2000000;
BA_DEF_  "BusType" STRING ;
BA_DEF_  "DBName" STRING ;
BA_DEF_  "E2EP05MaxDeltaCounter" INT 0 65535;
BA_DEF_  "E2EP05MaxErrorStateInit" INT 0 65535;
BA_DEF_  "E2EP05MaxErrorStateInvalid" INT 0 65535;
BA_DEF_  "E2EP05MaxErrorStateValid" INT 0 65535;
BA_DEF_  "E2EP05MinOkStateInit" INT 0 65535;
BA_DEF_  "E2EP05MinOkStateInvalid" INT 0 65535;
BA_DEF_  "E2EP05MinOkStateValid" INT 0 65535;
BA_DEF_  "E2EP05ProfileName" STRING ;
BA_DEF_  "E2EP05WindowSize" INT 0 65535;
BA_DEF_  "GenAuthor" STRING ;
BA_DEF_  "GenCompany" STRING ;
BA_DEF_  "GenDescription" STRING ;
BA_DEF_  "GenNetworkBaudrate" STRING ;
BA_DEF_  "GenNetworkMuxEn" STRING ;
BA_DEF_  "GenNetworkName" STRING ;
BA_DEF_  "GenRevision" STRING ;
BA_DEF_  "GenRevisionDate" STRING ;
BA_DEF_  "NmAsrBaseAddress" HEX 1280 1408;
BA_DEF_  "NmAsrMessageCount" INT 64 128;
BA_DEF_  "NmBaseAddress" HEX 1280 1280;
BA_DEF_  "NmMessageCount" INT 0 128;
BA_DEF_  "NmType" STRING ;
BA_DEF_  "VersionDay" INT 1 31;
BA_DEF_  "VersionMonth" INT 1 12;
BA_DEF_  "VersionYear" INT 2000 3000;
BA_DEF_DEF_  "CanTpBs" 255;
BA_DEF_DEF_  "DiagRequest" "No";
BA_DEF_DEF_  "DiagResponse" "No";
BA_DEF_DEF_  "E2EDataId" 0;
BA_DEF_DEF_  "E2EDataLength" 0;
BA_DEF_DEF_  "E2EProfile" "";
BA_DEF_DEF_  "EventRateOfChange" 10000;
BA_DEF_DEF_  "GenMsgCycleTime" 0;
BA_DEF_DEF_  "GenMsgILSupport" "Yes";
BA_DEF_DEF_  "GenMsgNrOfRepetition" 0;
BA_DEF_DEF_  "GenMsgSendType" "NoMsgSendType";
BA_DEF_DEF_  "MessageGateway" "No";
BA_DEF_DEF_  "NetworkInitialization" "Yes";
BA_DEF_DEF_  "SCP_AuthInfoTxLength" 28;
BA_DEF_DEF_  "SCP_DataId" 0;
BA_DEF_DEF_  "SCP_FreshnessValueId" 0;
BA_DEF_DEF_  "SCP_FreshnessValueLength" 48;
BA_DEF_DEF_  "SCP_FreshnessValueTxLength" 4;
BA_DEF_DEF_  "SC_Message" "No";
BA_DEF_DEF_  "VFrameFormat" "StandardCAN_FD";
BA_DEF_DEF_  "GenSigCmt" "";
BA_DEF_DEF_  "GenSigCycleTime" 0;
BA_DEF_DEF_  "GenSigSendType" "NoSigSendType";
BA_DEF_DEF_  "GenSigStartValue" 0;
BA_DEF_DEF_  "GenSigTimeoutTime" 0;
BA_DEF_DEF_  "InvalidValue" "";
BA_DEF_DEF_  "NmAsrNodeIdentifier" 128;
BA_DEF_DEF_  "NmStationAddress" 0;
BA_DEF_DEF_  "NodeStartUpTime" 250;
BA_DEF_DEF_  "NodeWakeUpTime" 10;
BA_DEF_DEF_  "PowerType" "Switched";
BA_DEF_DEF_  "Baudrate" 500000;
BA_DEF_DEF_  "BaudrateCANFD" 2000000;
BA_DEF_DEF_  "BusType" "CAN";
BA_DEF_DEF_  "DBName" "";
BA_DEF_DEF_  "E2EP05MaxDeltaCounter" 1;
BA_DEF_DEF_  "E2EP05MaxErrorStateInit" 1;
BA_DEF_DEF_  "E2EP05MaxErrorStateInvalid" 1;
BA_DEF_DEF_  "E2EP05MaxErrorStateValid" 1;
BA_DEF_DEF_  "E2EP05MinOkStateInit" 1;
BA_DEF_DEF_  "E2EP05MinOkStateInvalid" 2;
BA_DEF_DEF_  "E2EP05MinOkStateValid" 1;
BA_DEF_DEF_  "E2EP05ProfileName" "PROFILE_05";
BA_DEF_DEF_  "E2EP05WindowSize" 3;
BA_DEF_DEF_  "GenAuthor" "xx";
BA_DEF_DEF_  "GenCompany" "APTIV";
BA_DEF_DEF_  "GenDescription" "CAN bus that communicates the radars";
BA_DEF_DEF_  "GenNetworkBaudrate" "500 kbps";
BA_DEF_DEF_  "GenNetworkMuxEn" "FALSE";
BA_DEF_DEF_  "GenNetworkName" "PCAN";
BA_DEF_DEF_  "GenRevision" "v1.00";
BA_DEF_DEF_  "GenRevisionDate" "March 30, 2021";
BA_DEF_DEF_  "NmAsrBaseAddress" 1280;
BA_DEF_DEF_  "NmAsrMessageCount" 64;
BA_DEF_DEF_  "NmBaseAddress" 1280;
BA_DEF_DEF_  "NmMessageCount" 128;
BA_DEF_DEF_  "NmType" "NmAsr";
BA_DEF_DEF_  "VersionDay" 2;
BA_DEF_DEF_  "VersionMonth" 1;
BA_DEF_DEF_  "VersionYear" 2021;
BA_ "GenRevisionDate" "March 03, 2026";
BA_ "E2EP05MaxDeltaCounter" 3;
BA_ "E2EP05MinOkStateInvalid" 1;
BA_ "E2EP05WindowSize" 2;
BA_ "GenCompany" "Aptiv";
BA_ "GenNetworkBaudrate" "500000";
BA_ "GenRevision" "V04.02";
BA_ "NmMessageCount" 64;
BA_ "VersionDay" 3;
BA_ "VersionMonth" 3;
BA_ "VersionYear" 2026;
BA_ "DBName" "ADAS_DBC";
BA_ "NmStationAddress" BU_ Gateway_25 37;
BA_ "NmStationAddress" BU_ FCM_A0 160;
BA_ "NmStationAddress" BU_ FLR 208;
BA_ "NmStationAddress" BU_ SRR_RL 176;
BA_ "NmStationAddress" BU_ External_Tool 1;
BA_ "NmStationAddress" BU_ SRR_FL 177;
BA_ "NmStationAddress" BU_ Steering_E4 228;
BA_ "NmStationAddress" BU_ VCU_47 71;
BA_ "NmStationAddress" BU_ CLS_17 23;
BA_ "NmStationAddress" BU_ ESC_0B 11;
BA_ "GenMsgSendType" BO_ 1796 0;
BA_ "GenMsgCycleTime" BO_ 1796 50;
BA_ "E2EProfile" BO_ 1796 "P05";
BA_ "E2EDataLength" BO_ 1796 216;
BA_ "E2EDataId" BO_ 1796 1183;
BA_ "GenMsgSendType" BO_ 82 1;
BA_ "GenMsgSendType" BO_ 81 1;
BA_ "GenMsgSendType" BO_ 80 1;
BA_ "GenMsgSendType" BO_ 2564530421 1;
BA_ "DiagRequest" BO_ 2564530421 1;
BA_ "VFrameFormat" BO_ 2564530421 15;
BA_ "GenMsgSendType" BO_ 2564530420 1;
BA_ "DiagRequest" BO_ 2564530420 1;
BA_ "VFrameFormat" BO_ 2564530420 15;
BA_ "GenMsgSendType" BO_ 2564464885 1;
BA_ "DiagRequest" BO_ 2564464885 1;
BA_ "VFrameFormat" BO_ 2564464885 15;
BA_ "GenMsgSendType" BO_ 2564464884 1;
BA_ "DiagRequest" BO_ 2564464884 1;
BA_ "VFrameFormat" BO_ 2564464884 15;
BA_ "GenMsgSendType" BO_ 2564486560 1;
BA_ "DiagResponse" BO_ 2564486560 1;
BA_ "VFrameFormat" BO_ 2564486560 15;
BA_ "GenMsgSendType" BO_ 2564486304 1;
BA_ "DiagResponse" BO_ 2564486304 1;
BA_ "VFrameFormat" BO_ 2564486304 15;
BA_ "GenMsgSendType" BO_ 2564485536 1;
BA_ "DiagResponse" BO_ 2564485536 1;
BA_ "VFrameFormat" BO_ 2564485536 15;
BA_ "GenMsgSendType" BO_ 2564485280 2;
BA_ "VFrameFormat" BO_ 2564485280 3;
BA_ "GenMsgSendType" BO_ 2564552096 2;
BA_ "VFrameFormat" BO_ 2564552096 3;
BA_ "GenMsgSendType" BO_ 2564551840 2;
BA_ "VFrameFormat" BO_ 2564551840 3;
BA_ "GenMsgSendType" BO_ 2564551072 2;
BA_ "VFrameFormat" BO_ 2564551072 3;
BA_ "GenMsgSendType" BO_ 2564550816 2;
BA_ "VFrameFormat" BO_ 2564550816 3;
BA_ "GenMsgSendType" BO_ 2564464881 1;
BA_ "DiagRequest" BO_ 2564464881 1;
BA_ "VFrameFormat" BO_ 2564464881 15;
BA_ "GenMsgSendType" BO_ 2564464880 2;
BA_ "VFrameFormat" BO_ 2564464880 3;
BA_ "GenMsgSendType" BO_ 2564530417 1;
BA_ "DiagRequest" BO_ 2564530417 1;
BA_ "VFrameFormat" BO_ 2564530417 15;
BA_ "GenMsgSendType" BO_ 2564530416 2;
BA_ "VFrameFormat" BO_ 2564530416 3;
BA_ "GenMsgSendType" BO_ 2566843429 1;
BA_ "VFrameFormat" BO_ 2566843429 3;
BA_ "GenMsgSendType" BO_ 2566841879 0;
BA_ "GenMsgCycleTime" BO_ 2566841879 50;
BA_ "VFrameFormat" BO_ 2566841879 3;
BA_ "GenMsgSendType" BO_ 2566848791 0;
BA_ "GenMsgCycleTime" BO_ 2566848791 50;
BA_ "VFrameFormat" BO_ 2566848791 3;
BA_ "GenMsgSendType" BO_ 2566869015 0;
BA_ "GenMsgCycleTime" BO_ 2566869015 50;
BA_ "VFrameFormat" BO_ 2566869015 3;
BA_ "GenMsgSendType" BO_ 2365556759 0;
BA_ "GenMsgCycleTime" BO_ 2365556759 50;
BA_ "VFrameFormat" BO_ 2365556759 3;
BA_ "GenMsgSendType" BO_ 2565873124 0;
BA_ "GenMsgCycleTime" BO_ 2565873124 200;
BA_ "VFrameFormat" BO_ 2565873124 3;
BA_ "GenMsgSendType" BO_ 2365428224 0;
BA_ "GenMsgCycleTime" BO_ 2365428224 10;
BA_ "VFrameFormat" BO_ 2365428224 3;
BA_ "GenMsgSendType" BO_ 2566840320 0;
BA_ "GenMsgCycleTime" BO_ 2566840320 100;
BA_ "VFrameFormat" BO_ 2566840320 3;
BA_ "GenMsgCycleTime" BO_ 2565481936 50;
BA_ "GenMsgSendType" BO_ 2565481936 0;
BA_ "VFrameFormat" BO_ 2565481936 3;
BA_ "GenMsgSendType" BO_ 132 0;
BA_ "GenMsgCycleTime" BO_ 132 50;
BA_ "E2EDataId" BO_ 132 388;
BA_ "E2EProfile" BO_ 132 "P05";
BA_ "E2EDataLength" BO_ 132 400;
BA_ "GenMsgSendType" BO_ 131 0;
BA_ "GenMsgCycleTime" BO_ 131 1000;
BA_ "E2EDataId" BO_ 131 387;
BA_ "E2EProfile" BO_ 131 "P05";
BA_ "E2EDataLength" BO_ 131 504;
BA_ "SC_Message" BO_ 128 1;
BA_ "SCP_FreshnessValueTxLength" BO_ 128 56;
BA_ "SCP_FreshnessValueLength" BO_ 128 56;
BA_ "SCP_FreshnessValueId" BO_ 128 37945;
BA_ "SCP_DataId" BO_ 128 36943;
BA_ "SCP_AuthInfoTxLength" BO_ 128 40;
BA_ "GenMsgSendType" BO_ 128 1;
BA_ "E2EProfile" BO_ 128 "P05";
BA_ "E2EDataLength" BO_ 128 408;
BA_ "E2EDataId" BO_ 128 384;
BA_ "GenMsgCycleTime" BO_ 2565603249 1000;
BA_ "GenMsgSendType" BO_ 2565603249 0;
BA_ "VFrameFormat" BO_ 2565603249 3;
BA_ "GenMsgCycleTime" BO_ 2565668785 1000;
BA_ "GenMsgSendType" BO_ 2565668785 0;
BA_ "VFrameFormat" BO_ 2565668785 3;
BA_ "GenMsgSendType" BO_ 2565603248 0;
BA_ "GenMsgCycleTime" BO_ 2565603248 1000;
BA_ "VFrameFormat" BO_ 2565603248 3;
BA_ "GenMsgSendType" BO_ 2565668784 0;
BA_ "GenMsgCycleTime" BO_ 2565668784 1000;
BA_ "VFrameFormat" BO_ 2565668784 3;
BA_ "GenMsgSendType" BO_ 50 1;
BA_ "GenMsgSendType" BO_ 49 1;
BA_ "GenMsgSendType" BO_ 48 1;
BA_ "GenMsgSendType" BO_ 18 1;
BA_ "GenMsgSendType" BO_ 17 1;
BA_ "GenMsgSendType" BO_ 16 1;
BA_ "DiagResponse" BO_ 2564486576 1;
BA_ "GenMsgSendType" BO_ 2564486576 1;
BA_ "VFrameFormat" BO_ 2564486576 15;
BA_ "DiagResponse" BO_ 2564486320 1;
BA_ "GenMsgSendType" BO_ 2564486320 1;
BA_ "VFrameFormat" BO_ 2564486320 15;
BA_ "DiagResponse" BO_ 2564485552 1;
BA_ "GenMsgSendType" BO_ 2564485552 1;
BA_ "VFrameFormat" BO_ 2564485552 15;
BA_ "DiagResponse" BO_ 2564485296 1;
BA_ "GenMsgSendType" BO_ 2564485296 1;
BA_ "VFrameFormat" BO_ 2564485296 15;
BA_ "DiagResponse" BO_ 2564552112 1;
BA_ "GenMsgSendType" BO_ 2564552112 1;
BA_ "VFrameFormat" BO_ 2564552112 15;
BA_ "DiagResponse" BO_ 2564551856 1;
BA_ "GenMsgSendType" BO_ 2564551856 1;
BA_ "VFrameFormat" BO_ 2564551856 15;
BA_ "DiagResponse" BO_ 2564551088 1;
BA_ "GenMsgSendType" BO_ 2564551088 1;
BA_ "VFrameFormat" BO_ 2564551088 15;
BA_ "DiagResponse" BO_ 2564550832 1;
BA_ "GenMsgSendType" BO_ 2564550832 1;
BA_ "VFrameFormat" BO_ 2564550832 15;
BA_ "DiagRequest" BO_ 2564468981 1;
BA_ "GenMsgSendType" BO_ 2564468981 1;
BA_ "VFrameFormat" BO_ 2564468981 15;
BA_ "DiagRequest" BO_ 2564468980 1;
BA_ "GenMsgSendType" BO_ 2564468980 1;
BA_ "VFrameFormat" BO_ 2564468980 15;
BA_ "DiagRequest" BO_ 2564468976 1;
BA_ "GenMsgSendType" BO_ 2564468976 1;
BA_ "VFrameFormat" BO_ 2564468976 15;
BA_ "DiagRequest" BO_ 2564468977 1;
BA_ "GenMsgSendType" BO_ 2564468977 1;
BA_ "VFrameFormat" BO_ 2564468977 15;
BA_ "DiagRequest" BO_ 2564534517 1;
BA_ "GenMsgSendType" BO_ 2564534517 1;
BA_ "VFrameFormat" BO_ 2564534517 15;
BA_ "DiagRequest" BO_ 2564534516 1;
BA_ "GenMsgSendType" BO_ 2564534516 1;
BA_ "VFrameFormat" BO_ 2564534516 15;
BA_ "DiagRequest" BO_ 2564534513 1;
BA_ "GenMsgSendType" BO_ 2564534513 1;
BA_ "VFrameFormat" BO_ 2564534513 15;
BA_ "DiagRequest" BO_ 2564534512 1;
BA_ "GenMsgSendType" BO_ 2564534512 1;
BA_ "VFrameFormat" BO_ 2564534512 15;
BA_ "DiagRequest" BO_ 2564534773 1;
BA_ "GenMsgSendType" BO_ 2564534773 1;
BA_ "VFrameFormat" BO_ 2564534773 15;
BA_ "DiagRequest" BO_ 2564534772 1;
BA_ "GenMsgSendType" BO_ 2564534772 1;
BA_ "VFrameFormat" BO_ 2564534772 15;
BA_ "DiagRequest" BO_ 2564534768 1;
BA_ "GenMsgSendType" BO_ 2564534768 1;
BA_ "VFrameFormat" BO_ 2564534768 15;
BA_ "DiagRequest" BO_ 2564534769 1;
BA_ "GenMsgSendType" BO_ 2564534769 1;
BA_ "VFrameFormat" BO_ 2564534769 15;
BA_ "DiagResponse" BO_ 2564486577 1;
BA_ "GenMsgSendType" BO_ 2564486577 1;
BA_ "VFrameFormat" BO_ 2564486577 15;
BA_ "DiagResponse" BO_ 2564486321 1;
BA_ "GenMsgSendType" BO_ 2564486321 1;
BA_ "VFrameFormat" BO_ 2564486321 15;
BA_ "DiagResponse" BO_ 2564485553 1;
BA_ "GenMsgSendType" BO_ 2564485553 1;
BA_ "VFrameFormat" BO_ 2564485553 15;
BA_ "DiagResponse" BO_ 2564485297 1;
BA_ "GenMsgSendType" BO_ 2564485297 1;
BA_ "VFrameFormat" BO_ 2564485297 15;
BA_ "DiagResponse" BO_ 2564552113 1;
BA_ "GenMsgSendType" BO_ 2564552113 1;
BA_ "VFrameFormat" BO_ 2564552113 15;
BA_ "DiagResponse" BO_ 2564551857 1;
BA_ "GenMsgSendType" BO_ 2564551857 1;
BA_ "VFrameFormat" BO_ 2564551857 15;
BA_ "DiagResponse" BO_ 2564551089 1;
BA_ "GenMsgSendType" BO_ 2564551089 1;
BA_ "VFrameFormat" BO_ 2564551089 15;
BA_ "DiagResponse" BO_ 2564550833 1;
BA_ "GenMsgSendType" BO_ 2564550833 1;
BA_ "VFrameFormat" BO_ 2564550833 15;
BA_ "DiagRequest" BO_ 2564469237 1;
BA_ "GenMsgSendType" BO_ 2564469237 1;
BA_ "VFrameFormat" BO_ 2564469237 15;
BA_ "DiagRequest" BO_ 2564469236 1;
BA_ "GenMsgSendType" BO_ 2564469236 1;
BA_ "VFrameFormat" BO_ 2564469236 15;
BA_ "GenMsgSendType" BO_ 2564486352 1;
BA_ "DiagResponse" BO_ 2564486352 1;
BA_ "VFrameFormat" BO_ 2564486352 15;
BA_ "GenMsgSendType" BO_ 2564486608 1;
BA_ "DiagResponse" BO_ 2564486608 1;
BA_ "VFrameFormat" BO_ 2564486608 15;
BA_ "GenMsgSendType" BO_ 2564477173 1;
BA_ "DiagRequest" BO_ 2564477173 1;
BA_ "VFrameFormat" BO_ 2564477173 15;
BA_ "GenMsgSendType" BO_ 2564477172 1;
BA_ "DiagRequest" BO_ 2564477172 1;
BA_ "VFrameFormat" BO_ 2564477172 15;
BA_ "GenMsgSendType" BO_ 2564477169 1;
BA_ "DiagRequest" BO_ 2564477169 1;
BA_ "VFrameFormat" BO_ 2564477169 15;
BA_ "DiagResponse" BO_ 2564477168 1;
BA_ "GenMsgSendType" BO_ 2564477168 1;
BA_ "VFrameFormat" BO_ 2564477168 15;
BA_ "GenMsgSendType" BO_ 2564542709 1;
BA_ "DiagRequest" BO_ 2564542709 1;
BA_ "VFrameFormat" BO_ 2564542709 15;
BA_ "GenMsgSendType" BO_ 2564542708 1;
BA_ "DiagRequest" BO_ 2564542708 1;
BA_ "VFrameFormat" BO_ 2564542708 15;
BA_ "GenMsgSendType" BO_ 2564552144 2;
BA_ "VFrameFormat" BO_ 2564552144 3;
BA_ "GenMsgSendType" BO_ 2564551888 2;
BA_ "VFrameFormat" BO_ 2564551888 3;
BA_ "GenMsgSendType" BO_ 2564551120 2;
BA_ "VFrameFormat" BO_ 2564551120 3;
BA_ "GenMsgSendType" BO_ 2564550864 2;
BA_ "VFrameFormat" BO_ 2564550864 3;
BA_ "GenMsgSendType" BO_ 2565517591 2;
BA_ "VFrameFormat" BO_ 2565517591 3;
BA_ "GenMsgSendType" BO_ 2565517335 2;
BA_ "VFrameFormat" BO_ 2565517335 3;
BA_ "GenMsgSendType" BO_ 2565481904 2;
BA_ "VFrameFormat" BO_ 2565481904 3;
BA_ "GenMsgSendType" BO_ 2565481905 2;
BA_ "VFrameFormat" BO_ 2565481905 3;
BA_ "GenMsgSendType" BO_ 2566838961 1;
BA_ "VFrameFormat" BO_ 2566838961 3;
BA_ "GenMsgSendType" BO_ 2566838960 1;
BA_ "VFrameFormat" BO_ 2566838960 3;
BA_ "E2EProfile" BO_ 164 "P05";
BA_ "E2EDataLength" BO_ 164 400;
BA_ "E2EDataId" BO_ 164 1444;
BA_ "GenMsgCycleTime" BO_ 164 50;
BA_ "GenMsgSendType" BO_ 164 0;
BA_ "GenSigSendType" SG_ 3221225472 CAP_AngleAzimuthRangeEnd_Copy_1 0;
BA_ "GenSigCycleTime" SG_ 3221225472 CAP_AngleAzimuthRangeEnd_Copy_1 50;
BA_ "GenSigStartValue" SG_ 3221225472 STS_VehicleCondition 6;
BA_ "GenSigCycleTime" SG_ 3221225472 STS_StartRoll 50;
BA_ "GenSigSendType" SG_ 3221225472 STS_StartRoll 0;
BA_ "GenSigCycleTime" SG_ 3221225472 STS_AACurrentRoll 50;
BA_ "GenSigSendType" SG_ 3221225472 STS_AACurrentRoll 0;
BA_ "GenSigCycleTime" SG_ 3221225472 STS_AARoll_Std 50;
BA_ "GenSigSendType" SG_ 3221225472 STS_AARoll_Std 0;
BA_ "GenSigCycleTime" SG_ 3221225472 STS_RollErrorNegative 50;
BA_ "GenSigSendType" SG_ 3221225472 STS_RollErrorNegative 0;
BA_ "GenSigCycleTime" SG_ 3221225472 STS_Roll_Updates 50;
BA_ "GenSigSendType" SG_ 3221225472 STS_Roll_Updates 0;
BA_ "GenSigCycleTime" SG_ 3221225472 AL_STS_001_CYCLE_COUNTER 50;
BA_ "GenSigSendType" SG_ 3221225472 AL_STS_001_CYCLE_COUNTER 0;
BA_ "GenSigCycleTime" SG_ 3221225472 AL_STS_001_MH_CRC16 50;
BA_ "GenSigSendType" SG_ 3221225472 AL_STS_001_MH_CRC16 0;
BA_ "GenSigCycleTime" SG_ 3221225472 STS_ElevationUpdates 50;
BA_ "GenSigSendType" SG_ 3221225472 STS_ElevationUpdates 0;
BA_ "GenSigCycleTime" SG_ 3221225472 STS_AzimuthUpdates 50;
BA_ "GenSigSendType" SG_ 3221225472 STS_AzimuthUpdates 0;
BA_ "GenSigCycleTime" SG_ 3221225472 STS_HostSpdCompensationFactorQF 50;
BA_ "GenSigSendType" SG_ 3221225472 STS_HostSpdCompensationFactorQF 0;
BA_ "GenSigCycleTime" SG_ 3221225472 STS_HostSpeedCompensationFactor 50;
BA_ "GenSigSendType" SG_ 3221225472 STS_HostSpeedCompensationFactor 0;
BA_ "GenSigStartValue" SG_ 3221225472 STS_HostSpeedCompensationFactor 100;
BA_ "GenSigCycleTime" SG_ 3221225472 STS_ElevationErrorNegative 50;
BA_ "GenSigSendType" SG_ 3221225472 STS_ElevationErrorNegative 0;
BA_ "GenSigCycleTime" SG_ 3221225472 STS_AzimuthErrorNegative 50;
BA_ "GenSigSendType" SG_ 3221225472 STS_AzimuthErrorNegative 0;
BA_ "GenSigCycleTime" SG_ 3221225472 STS_RollErrorPositive 50;
BA_ "GenSigSendType" SG_ 3221225472 STS_RollErrorPositive 0;
BA_ "GenSigCycleTime" SG_ 3221225472 STS_ElevationErrorPositive 50;
BA_ "GenSigSendType" SG_ 3221225472 STS_ElevationErrorPositive 0;
BA_ "GenSigCycleTime" SG_ 3221225472 STS_AzimuthErrorPositive 50;
BA_ "GenSigSendType" SG_ 3221225472 STS_AzimuthErrorPositive 0;
BA_ "GenSigCycleTime" SG_ 3221225472 STS_AAElevationStd 50;
BA_ "GenSigSendType" SG_ 3221225472 STS_AAElevationStd 0;
BA_ "GenSigCycleTime" SG_ 3221225472 STS_AAAzimuthStd 50;
BA_ "GenSigSendType" SG_ 3221225472 STS_AAAzimuthStd 0;
BA_ "GenSigCycleTime" SG_ 3221225472 STS_AACurrentElevation 50;
BA_ "GenSigSendType" SG_ 3221225472 STS_AACurrentElevation 0;
BA_ "GenSigStartValue" SG_ 3221225472 STS_AACurrentElevation 872.5;
BA_ "GenSigCycleTime" SG_ 3221225472 STS_AACurrentAzimuth 50;
BA_ "GenSigSendType" SG_ 3221225472 STS_AACurrentAzimuth 0;
BA_ "GenSigStartValue" SG_ 3221225472 STS_AACurrentAzimuth 15708;
BA_ "GenSigCycleTime" SG_ 3221225472 STS_StartElevation 50;
BA_ "GenSigSendType" SG_ 3221225472 STS_StartElevation 0;
BA_ "GenSigCycleTime" SG_ 3221225472 STS_StartAzimuth 50;
BA_ "GenSigSendType" SG_ 3221225472 STS_StartAzimuth 0;
BA_ "GenSigCycleTime" SG_ 3221225472 STS_AutoAlignmentFailRootCause 50;
BA_ "GenSigSendType" SG_ 3221225472 STS_AutoAlignmentFailRootCause 0;
BA_ "GenSigStartValue" SG_ 3221225472 STS_AutoAlignmentFailRootCause 5;
BA_ "GenSigCycleTime" SG_ 3221225472 STS_AlignmentAutoStatus 50;
BA_ "GenSigSendType" SG_ 3221225472 STS_AlignmentAutoStatus 0;
BA_ "GenSigCycleTime" SG_ 3221225472 STS_CalDisplay 50;
BA_ "GenSigSendType" SG_ 3221225472 STS_CalDisplay 0;
BA_ "GenSigCycleTime" SG_ 3221225472 STS_AlignmentError 50;
BA_ "GenSigSendType" SG_ 3221225472 STS_AlignmentError 0;
BA_ "GenSigCycleTime" SG_ 3221225472 STS_ProgressPercent 50;
BA_ "GenSigSendType" SG_ 3221225472 STS_ProgressPercent 0;
BA_ "GenSigCycleTime" SG_ 3221225472 STS_CalTime 50;
BA_ "GenSigSendType" SG_ 3221225472 STS_CalTime 0;
BA_ "GenSigCycleTime" SG_ 3221225472 STS_ElevationStd 50;
BA_ "GenSigSendType" SG_ 3221225472 STS_ElevationStd 0;
BA_ "GenSigCycleTime" SG_ 3221225472 STS_AzimuthStd 50;
BA_ "GenSigSendType" SG_ 3221225472 STS_AzimuthStd 0;
BA_ "GenSigCycleTime" SG_ 3221225472 STS_AlignmentElevation 50;
BA_ "GenSigSendType" SG_ 3221225472 STS_AlignmentElevation 0;
BA_ "GenSigStartValue" SG_ 3221225472 STS_AlignmentElevation 10000;
BA_ "GenSigCycleTime" SG_ 3221225472 STS_AlignmentAzimuth 50;
BA_ "GenSigSendType" SG_ 3221225472 STS_AlignmentAzimuth 0;
BA_ "GenSigStartValue" SG_ 3221225472 STS_AlignmentAzimuth 10000;
BA_ "GenSigCycleTime" SG_ 3221225472 STS_InitAlignRsltHostSpdCompFac 50;
BA_ "GenSigSendType" SG_ 3221225472 STS_InitAlignRsltHostSpdCompFac 0;
BA_ "GenSigStartValue" SG_ 3221225472 STS_InitAlignRsltHostSpdCompFac 100;
BA_ "GenSigCycleTime" SG_ 3221225472 STS_InitAlignRsltElevationUpdate 50;
BA_ "GenSigSendType" SG_ 3221225472 STS_InitAlignRsltElevationUpdate 0;
BA_ "GenSigCycleTime" SG_ 3221225472 STS_InitAlignResultAzimuthUpdate 50;
BA_ "GenSigSendType" SG_ 3221225472 STS_InitAlignResultAzimuthUpdate 0;
BA_ "GenSigCycleTime" SG_ 3221225472 STS_AlignmentModeOut 50;
BA_ "GenSigSendType" SG_ 3221225472 STS_AlignmentModeOut 0;
BA_ "GenSigCycleTime" SG_ 3221225472 STS_InitLastSuccessfulAlignMode 50;
BA_ "GenSigSendType" SG_ 3221225472 STS_InitLastSuccessfulAlignMode 0;
BA_ "GenSigCycleTime" SG_ 3221225472 STS_InitAlignmentResultElevation 50;
BA_ "GenSigSendType" SG_ 3221225472 STS_InitAlignmentResultElevation 0;
BA_ "GenSigCycleTime" SG_ 3221225472 STS_InitAlignmentResultAzimuth 50;
BA_ "GenSigSendType" SG_ 3221225472 STS_InitAlignmentResultAzimuth 0;
BA_ "GenSigCycleTime" SG_ 3221225472 STS_RadarTypeInput 50;
BA_ "GenSigSendType" SG_ 3221225472 STS_RadarTypeInput 0;
BA_ "GenSigCycleTime" SG_ 3221225472 STS_CoordinateSystemInput 50;
BA_ "GenSigSendType" SG_ 3221225472 STS_CoordinateSystemInput 0;
BA_ "GenSigCycleTime" SG_ 3221225472 STS_AlignmentModeIn 50;
BA_ "GenSigSendType" SG_ 3221225472 STS_AlignmentModeIn 0;
BA_ "GenSigCycleTime" SG_ 3221225472 CAP_MaxDetRangePedestrian_2 50;
BA_ "GenSigSendType" SG_ 3221225472 CAP_MaxDetRangePedestrian_2 0;
BA_ "GenSigCycleTime" SG_ 3221225472 CAP_MaxDetRangePedestrian_1 50;
BA_ "GenSigSendType" SG_ 3221225472 CAP_MaxDetRangePedestrian_1 0;
BA_ "GenSigCycleTime" SG_ 3221225472 CAP_MaxDetRangeMotorbike_2 50;
BA_ "GenSigSendType" SG_ 3221225472 CAP_MaxDetRangeMotorbike_2 0;
BA_ "GenSigCycleTime" SG_ 3221225472 CAP_MaxDetRangeMotorbike_0 50;
BA_ "GenSigSendType" SG_ 3221225472 CAP_MaxDetRangeMotorbike_0 0;
BA_ "GenSigCycleTime" SG_ 3221225472 CAP_MaxDetectionRangeCar_2 50;
BA_ "GenSigSendType" SG_ 3221225472 CAP_MaxDetectionRangeCar_2 0;
BA_ "GenSigCycleTime" SG_ 3221225472 CAP_MaxDetectionRangeCar_1 50;
BA_ "GenSigSendType" SG_ 3221225472 CAP_MaxDetectionRangeCar_1 0;
BA_ "GenSigCycleTime" SG_ 3221225472 CAP_SideLobeLevelBeamformer 50;
BA_ "GenSigSendType" SG_ 3221225472 CAP_SideLobeLevelBeamformer 0;
BA_ "GenSigCycleTime" SG_ 3221225472 CAP_SLLMonitoringStatus 50;
BA_ "GenSigSendType" SG_ 3221225472 CAP_SLLMonitoringStatus 0;
BA_ "GenSigStartValue" SG_ 3221225472 CAP_SLLMonitoringStatus 3;
BA_ "InvalidValue" SG_ 3221225472 CAP_SLLMonitoringStatus "4";
BA_ "GenSigCycleTime" SG_ 3221225472 CAP_SLLMonitoringActive 50;
BA_ "GenSigSendType" SG_ 3221225472 CAP_SLLMonitoringActive 0;
BA_ "GenSigStartValue" SG_ 3221225472 CAP_SLLMonitoringActive 1;
BA_ "GenSigCycleTime" SG_ 3221225472 CAP_AngleAzimuthRangeEnd 50;
BA_ "GenSigSendType" SG_ 3221225472 CAP_AngleAzimuthRangeEnd 0;
BA_ "GenSigCycleTime" SG_ 3221225472 CAP_AngleAzimuthRangeStart 50;
BA_ "GenSigSendType" SG_ 3221225472 CAP_AngleAzimuthRangeStart 0;
BA_ "GenSigCycleTime" SG_ 3221225472 CAP_MaxDetRangePedestrian_0 50;
BA_ "GenSigSendType" SG_ 3221225472 CAP_MaxDetRangePedestrian_0 0;
BA_ "GenSigCycleTime" SG_ 3221225472 CAP_MaxDetRangeMotorbike_1 50;
BA_ "GenSigSendType" SG_ 3221225472 CAP_MaxDetRangeMotorbike_1 0;
BA_ "GenSigCycleTime" SG_ 3221225472 CAP_MaxDetectionRangeCar_0 50;
BA_ "GenSigSendType" SG_ 3221225472 CAP_MaxDetectionRangeCar_0 0;
BA_ "GenSigCycleTime" SG_ 3221225472 CAP_RangeEstimationStatus 50;
BA_ "GenSigSendType" SG_ 3221225472 CAP_RangeEstimationStatus 0;
BA_ "GenSigStartValue" SG_ 3221225472 CAP_RangeEstimationStatus 3;
BA_ "InvalidValue" SG_ 3221225472 CAP_RangeEstimationStatus "4";
BA_ "GenSigCycleTime" SG_ 3221225472 CAP_RangeEstimationActive 50;
BA_ "GenSigSendType" SG_ 3221225472 CAP_RangeEstimationActive 0;
BA_ "GenSigStartValue" SG_ 3221225472 CAP_RangeEstimationActive 1;
BA_ "GenSigCycleTime" SG_ 3221225472 CAP_DampingStandardDeviation 50;
BA_ "GenSigSendType" SG_ 3221225472 CAP_DampingStandardDeviation 0;
BA_ "GenSigCycleTime" SG_ 3221225472 CAP_DampingStatus 50;
BA_ "GenSigSendType" SG_ 3221225472 CAP_DampingStatus 0;
BA_ "GenSigStartValue" SG_ 3221225472 CAP_DampingStatus 3;
BA_ "InvalidValue" SG_ 3221225472 CAP_DampingStatus "4";
BA_ "GenSigCycleTime" SG_ 3221225472 CAP_DampingActive 50;
BA_ "GenSigSendType" SG_ 3221225472 CAP_DampingActive 0;
BA_ "GenSigCycleTime" SG_ 3221225472 CAP_DampingCurrent 50;
BA_ "GenSigSendType" SG_ 3221225472 CAP_DampingCurrent 0;
BA_ "GenSigStartValue" SG_ 3221225472 CAP_DampingCurrent 25500;
BA_ "GenSigCycleTime" SG_ 3221225472 CAP_SLBlockageFilterValue 50;
BA_ "GenSigSendType" SG_ 3221225472 CAP_SLBlockageFilterValue 0;
BA_ "GenSigCycleTime" SG_ 3221225472 CAP_SLBlockageFlag 50;
BA_ "GenSigSendType" SG_ 3221225472 CAP_SLBlockageFlag 0;
BA_ "GenSigCycleTime" SG_ 3221225472 CAP_FreeSightCheckStatus 50;
BA_ "GenSigSendType" SG_ 3221225472 CAP_FreeSightCheckStatus 0;
BA_ "GenSigStartValue" SG_ 3221225472 CAP_FreeSightCheckStatus 255;
BA_ "InvalidValue" SG_ 3221225472 CAP_FreeSightCheckStatus "2";
BA_ "GenSigCycleTime" SG_ 3221225472 CAP_FreeSightCheckActive 50;
BA_ "GenSigSendType" SG_ 3221225472 CAP_FreeSightCheckActive 0;
BA_ "GenSigStartValue" SG_ 3221225472 CAP_FreeSightCheckActive 1;
BA_ "InvalidValue" SG_ 3221225472 CAP_FreeSightCheckActive "3";
BA_ "GenSigCycleTime" SG_ 3221225472 CAP_BlockageProbability 50;
BA_ "GenSigSendType" SG_ 3221225472 CAP_BlockageProbability 0;
BA_ "GenSigStartValue" SG_ 3221225472 CAP_BlockageValue 5;
BA_ "InvalidValue" SG_ 3221225472 CAP_BlockageValue "6";
BA_ "GenSigCycleTime" SG_ 3221225472 CAP_BlockageStatus 50;
BA_ "GenSigSendType" SG_ 3221225472 CAP_BlockageStatus 0;
BA_ "GenSigStartValue" SG_ 3221225472 CAP_BlockageStatus 3;
BA_ "InvalidValue" SG_ 3221225472 CAP_BlockageStatus "4";
BA_ "GenSigCycleTime" SG_ 3221225472 CAP_BlockageActive 50;
BA_ "GenSigSendType" SG_ 3221225472 CAP_BlockageActive 0;
BA_ "GenSigStartValue" SG_ 3221225472 CAP_BlockageActive 1;
BA_ "GenSigCycleTime" SG_ 3221225472 CAP_BlockageSensitivity 50;
BA_ "GenSigSendType" SG_ 3221225472 CAP_BlockageSensitivity 0;
BA_ "GenSigStartValue" SG_ 3221225472 CAP_BlockageSensitivity 2;
BA_ "InvalidValue" SG_ 3221225472 CAP_BlockageSensitivity "3";
BA_ "GenSigCycleTime" SG_ 3221225472 STS_PCAN_PROTOCOL_VER_MINOR 50;
BA_ "GenSigSendType" SG_ 3221225472 STS_PCAN_PROTOCOL_VER_MINOR 0;
BA_ "GenSigTimeoutTime" SG_ 3221225472 STS_PCAN_PROTOCOL_VER_MINOR 150;
BA_ "GenSigCycleTime" SG_ 3221225472 STS_PCAN_PROTOCOL_VER_MAJOR 50;
BA_ "GenSigSendType" SG_ 3221225472 STS_PCAN_PROTOCOL_VER_MAJOR 0;
BA_ "GenSigTimeoutTime" SG_ 3221225472 STS_PCAN_PROTOCOL_VER_MAJOR 150;
BA_ "GenSigCycleTime" SG_ 3221225472 STS_SERIAL_NUMBER_SEQUENCE 50;
BA_ "GenSigSendType" SG_ 3221225472 STS_SERIAL_NUMBER_SEQUENCE 0;
BA_ "GenSigStartValue" SG_ 3221225472 STS_SERIAL_NUMBER_SEQUENCE 1234;
BA_ "GenSigTimeoutTime" SG_ 3221225472 STS_SERIAL_NUMBER_SEQUENCE 150;
BA_ "GenSigCycleTime" SG_ 3221225472 STS_SERIAL_NUM_JULIAN_YEAR 50;
BA_ "GenSigSendType" SG_ 3221225472 STS_SERIAL_NUM_JULIAN_YEAR 0;
BA_ "GenSigTimeoutTime" SG_ 3221225472 STS_SERIAL_NUM_JULIAN_YEAR 150;
BA_ "GenSigCycleTime" SG_ 3221225472 STS_SERIAL_NUM_JULIAN_DAY 50;
BA_ "GenSigSendType" SG_ 3221225472 STS_SERIAL_NUM_JULIAN_DAY 0;
BA_ "GenSigStartValue" SG_ 3221225472 STS_SERIAL_NUM_JULIAN_DAY 365;
BA_ "GenSigTimeoutTime" SG_ 3221225472 STS_SERIAL_NUM_JULIAN_DAY 150;
BA_ "GenSigStartValue" SG_ 3221225472 STS_SENSOR_MOUNT_POS_X 8192;
BA_ "GenSigStartValue" SG_ 3221225472 STS_SENSOR_MOUNT_POS_Y 32768;
BA_ "GenSigStartValue" SG_ 3221225472 STS_SENSOR_MOUNT_POS_Z 32768;
BA_ "GenSigStartValue" SG_ 3221225472 STS_SENSOR_MOUNT_ORNT_ROLL 7853.975;
BA_ "GenSigCmt" SG_ 3221225472 STS_Project_ACTV_FLT_BYTE_4_to_5 "Active faults";
BA_ "GenSigCmt" SG_ 3221225472 STS_Project_ACTV_FLT_BYTE_0_to_3 "Active faults";
BA_ "GenSigCmt" SG_ 3221225472 STS_CORE_ACTV_FLT_BYTE_11_to_15 "Active faults";
BA_ "GenSigCmt" SG_ 3221225472 STS_CORE_ACTV_FLT_BYTE_8_to_11 "Active faults";
BA_ "GenSigCycleTime" SG_ 3221225472 STS_SCAN_TYPE 50;
BA_ "GenSigSendType" SG_ 3221225472 STS_SCAN_TYPE 0;
BA_ "GenSigTimeoutTime" SG_ 3221225472 STS_SCAN_TYPE 150;
BA_ "GenSigCycleTime" SG_ 3221225472 STS_XCVR_OPERATIONAL 50;
BA_ "GenSigSendType" SG_ 3221225472 STS_XCVR_OPERATIONAL 0;
BA_ "GenSigTimeoutTime" SG_ 3221225472 STS_XCVR_OPERATIONAL 150;
BA_ "GenSigCycleTime" SG_ 3221225472 STS_YAW_RATE_BIAS 50;
BA_ "GenSigSendType" SG_ 3221225472 STS_YAW_RATE_BIAS 0;
BA_ "GenSigTimeoutTime" SG_ 3221225472 STS_YAW_RATE_BIAS 150;
BA_ "GenSigCmt" SG_ 3221225472 STS_CORE_ACTV_FLT_BYTE_4_to_7 "Active faults";
BA_ "GenSigCycleTime" SG_ 3221225472 STS_VEH_SPEED_DIRECTION 50;
BA_ "GenSigSendType" SG_ 3221225472 STS_VEH_SPEED_DIRECTION 0;
BA_ "GenSigTimeoutTime" SG_ 3221225472 STS_VEH_SPEED_DIRECTION 150;
BA_ "GenSigCycleTime" SG_ 3221225472 STS_STEERING_ANGLE_SIGN 50;
BA_ "GenSigSendType" SG_ 3221225472 STS_STEERING_ANGLE_SIGN 0;
BA_ "GenSigTimeoutTime" SG_ 3221225472 STS_STEERING_ANGLE_SIGN 150;
BA_ "GenSigCycleTime" SG_ 3221225472 STS_STEERING_ANGLE 50;
BA_ "GenSigSendType" SG_ 3221225472 STS_STEERING_ANGLE 0;
BA_ "GenSigTimeoutTime" SG_ 3221225472 STS_STEERING_ANGLE 150;
BA_ "GenSigCycleTime" SG_ 3221225472 STS_VEHICLE_SPEED_CALC 50;
BA_ "GenSigSendType" SG_ 3221225472 STS_VEHICLE_SPEED_CALC 0;
BA_ "GenSigTimeoutTime" SG_ 3221225472 STS_VEHICLE_SPEED_CALC 150;
BA_ "GenSigStartValue" SG_ 3221225472 HED_R_WRAPPING 90;
BA_ "GenSigCmt" SG_ 3221225472 HED_NUM_OF_VALID_DETECTIONS "Number of detections sent";
BA_ "GenSigCmt" SG_ 3221225472 HED_LOOK_ID "Indicates the look type values 1 to 4 base on medium/long look and near/far look";
BA_ "GenSigCmt" SG_ 3221225472 HED_SCAN_INDEX "Scan index for SODFL";
BA_ "GenSigStartValue" SG_ 3221225472 HED_DATA_QUALIFIER 1;
BA_ "GenSigCmt" SG_ 3221225472 HED_DET_RANGE_MAX "CAN range coverage";
BA_ "GenSigCmt" SG_ 3221225472 HED_DET_SPEED_RANGE_MAX "CAN range coverage";
BA_ "GenSigStartValue" SG_ 3221225472 HED_DET_SPEED_RANGE_MAX 32768;
BA_ "GenSigCmt" SG_ 3221225472 HED_FOV_HOR_MAX "CAN range coverage";
BA_ "GenSigCmt" SG_ 3221225472 HED_FOV_VER_MAX "CAN range coverage";
BA_ "GenSigStartValue" SG_ 3221225472 HED_DET_SPEED_RANGE_MIN 32768;
BA_ "GenSigCmt" SG_ 132 STS_Project_ACTV_FLT_BYTE_4_to_5 "Active faults";
BA_ "GenSigCmt" SG_ 132 STS_Project_ACTV_FLT_BYTE_0_to_3 "Active faults";
BA_ "GenSigCmt" SG_ 132 STS_CORE_ACTV_FLT_BYTE_11_to_15 "Active faults";
BA_ "GenSigCmt" SG_ 132 STS_CORE_ACTV_FLT_BYTE_8_to_11 "Active faults";
BA_ "GenSigCycleTime" SG_ 132 STS_SCAN_TYPE 50;
BA_ "GenSigSendType" SG_ 132 STS_SCAN_TYPE 0;
BA_ "GenSigTimeoutTime" SG_ 132 STS_SCAN_TYPE 150;
BA_ "GenSigCycleTime" SG_ 132 STS_XCVR_OPERATIONAL 50;
BA_ "GenSigSendType" SG_ 132 STS_XCVR_OPERATIONAL 0;
BA_ "GenSigTimeoutTime" SG_ 132 STS_XCVR_OPERATIONAL 150;
BA_ "GenSigCycleTime" SG_ 132 STS_YAW_RATE_BIAS 50;
BA_ "GenSigSendType" SG_ 132 STS_YAW_RATE_BIAS 0;
BA_ "GenSigTimeoutTime" SG_ 132 STS_YAW_RATE_BIAS 150;
BA_ "GenSigCmt" SG_ 132 STS_CORE_ACTV_FLT_BYTE_4_to_7 "Active faults";
BA_ "GenSigCycleTime" SG_ 132 STS_VEH_SPEED_DIRECTION 50;
BA_ "GenSigSendType" SG_ 132 STS_VEH_SPEED_DIRECTION 0;
BA_ "GenSigTimeoutTime" SG_ 132 STS_VEH_SPEED_DIRECTION 150;
BA_ "GenSigCycleTime" SG_ 132 STS_STEERING_ANGLE_SIGN 50;
BA_ "GenSigSendType" SG_ 132 STS_STEERING_ANGLE_SIGN 0;
BA_ "GenSigTimeoutTime" SG_ 132 STS_STEERING_ANGLE_SIGN 150;
BA_ "GenSigCycleTime" SG_ 132 STS_STEERING_ANGLE 50;
BA_ "GenSigSendType" SG_ 132 STS_STEERING_ANGLE 0;
BA_ "GenSigTimeoutTime" SG_ 132 STS_STEERING_ANGLE 150;
BA_ "GenSigCycleTime" SG_ 132 STS_VEHICLE_SPEED_CALC 50;
BA_ "GenSigSendType" SG_ 132 STS_VEHICLE_SPEED_CALC 0;
BA_ "GenSigTimeoutTime" SG_ 132 STS_VEHICLE_SPEED_CALC 150;
BA_ "GenSigCycleTime" SG_ 131 STS_PCAN_PROTOCOL_VER_MINOR 50;
BA_ "GenSigSendType" SG_ 131 STS_PCAN_PROTOCOL_VER_MINOR 0;
BA_ "GenSigTimeoutTime" SG_ 131 STS_PCAN_PROTOCOL_VER_MINOR 150;
BA_ "GenSigCycleTime" SG_ 131 STS_PCAN_PROTOCOL_VER_MAJOR 50;
BA_ "GenSigSendType" SG_ 131 STS_PCAN_PROTOCOL_VER_MAJOR 0;
BA_ "GenSigTimeoutTime" SG_ 131 STS_PCAN_PROTOCOL_VER_MAJOR 150;
BA_ "GenSigCycleTime" SG_ 131 STS_SERIAL_NUMBER_SEQUENCE 50;
BA_ "GenSigSendType" SG_ 131 STS_SERIAL_NUMBER_SEQUENCE 0;
BA_ "GenSigStartValue" SG_ 131 STS_SERIAL_NUMBER_SEQUENCE 1234;
BA_ "GenSigTimeoutTime" SG_ 131 STS_SERIAL_NUMBER_SEQUENCE 150;
BA_ "GenSigCycleTime" SG_ 131 STS_SERIAL_NUM_JULIAN_YEAR 50;
BA_ "GenSigSendType" SG_ 131 STS_SERIAL_NUM_JULIAN_YEAR 0;
BA_ "GenSigTimeoutTime" SG_ 131 STS_SERIAL_NUM_JULIAN_YEAR 150;
BA_ "GenSigCycleTime" SG_ 131 STS_SERIAL_NUM_JULIAN_DAY 50;
BA_ "GenSigSendType" SG_ 131 STS_SERIAL_NUM_JULIAN_DAY 0;
BA_ "GenSigStartValue" SG_ 131 STS_SERIAL_NUM_JULIAN_DAY 365;
BA_ "GenSigTimeoutTime" SG_ 131 STS_SERIAL_NUM_JULIAN_DAY 150;
BA_ "GenSigStartValue" SG_ 131 STS_SENSOR_MOUNT_POS_X 8192;
BA_ "GenSigStartValue" SG_ 131 STS_SENSOR_MOUNT_POS_Y 32768;
BA_ "GenSigStartValue" SG_ 131 STS_SENSOR_MOUNT_POS_Z 32768;
BA_ "GenSigStartValue" SG_ 131 STS_SENSOR_MOUNT_ORNT_ROLL 7853.975;
BA_ "GenSigStartValue" SG_ 128 HED_R_WRAPPING 90;
BA_ "GenSigCmt" SG_ 128 HED_NUM_OF_VALID_DETECTIONS "Number of detections sent";
BA_ "GenSigCmt" SG_ 128 HED_LOOK_ID "Indicates the look type values 1 to 4 base on medium/long look and near/far look";
BA_ "GenSigCmt" SG_ 128 HED_SCAN_INDEX "Scan index for SODFL";
BA_ "GenSigStartValue" SG_ 128 HED_DATA_QUALIFIER 1;
BA_ "GenSigCmt" SG_ 128 HED_DET_RANGE_MAX "CAN range coverage";
BA_ "GenSigCmt" SG_ 128 HED_DET_SPEED_RANGE_MAX "CAN range coverage";
BA_ "GenSigStartValue" SG_ 128 HED_DET_SPEED_RANGE_MAX 32768;
BA_ "GenSigCmt" SG_ 128 HED_FOV_HOR_MAX "CAN range coverage";
BA_ "GenSigCmt" SG_ 128 HED_FOV_VER_MAX "CAN range coverage";
BA_ "GenSigStartValue" SG_ 128 HED_DET_SPEED_RANGE_MIN 32768;
BA_ "GenSigStartValue" SG_ 128 HED_FOV_HOR_MIN 128;
BA_ "GenSigCmt" SG_ 164 STS_Project_ACTV_FLT_BYTE_4_to_5 "Active faults";
BA_ "GenSigCmt" SG_ 164 STS_Project_ACTV_FLT_BYTE_0_to_3 "Active faults";
BA_ "GenSigCmt" SG_ 164 STS_CORE_ACTV_FLT_BYTE_11_to_15 "Active faults";
BA_ "GenSigCmt" SG_ 164 STS_CORE_ACTV_FLT_BYTE_8_to_11 "Active faults";
BA_ "GenSigCycleTime" SG_ 164 STS_SCAN_TYPE 50;
BA_ "GenSigSendType" SG_ 164 STS_SCAN_TYPE 0;
BA_ "GenSigTimeoutTime" SG_ 164 STS_SCAN_TYPE 150;
BA_ "GenSigCycleTime" SG_ 164 STS_XCVR_OPERATIONAL 50;
BA_ "GenSigSendType" SG_ 164 STS_XCVR_OPERATIONAL 0;
BA_ "GenSigTimeoutTime" SG_ 164 STS_XCVR_OPERATIONAL 150;
BA_ "GenSigCycleTime" SG_ 164 STS_YAW_RATE_BIAS 50;
BA_ "GenSigSendType" SG_ 164 STS_YAW_RATE_BIAS 0;
BA_ "GenSigTimeoutTime" SG_ 164 STS_YAW_RATE_BIAS 150;
BA_ "GenSigCmt" SG_ 164 STS_CORE_ACTV_FLT_BYTE_4_to_7 "Active faults";
BA_ "GenSigCycleTime" SG_ 164 STS_VEH_SPEED_DIRECTION 50;
BA_ "GenSigSendType" SG_ 164 STS_VEH_SPEED_DIRECTION 0;
BA_ "GenSigTimeoutTime" SG_ 164 STS_VEH_SPEED_DIRECTION 150;
BA_ "GenSigCycleTime" SG_ 164 STS_STEERING_ANGLE_SIGN 50;
BA_ "GenSigSendType" SG_ 164 STS_STEERING_ANGLE_SIGN 0;
BA_ "GenSigTimeoutTime" SG_ 164 STS_STEERING_ANGLE_SIGN 150;
BA_ "GenSigCycleTime" SG_ 164 STS_STEERING_ANGLE 50;
BA_ "GenSigSendType" SG_ 164 STS_STEERING_ANGLE 0;
BA_ "GenSigTimeoutTime" SG_ 164 STS_STEERING_ANGLE 150;
BA_ "GenSigCycleTime" SG_ 164 STS_VEHICLE_SPEED_CALC 50;
BA_ "GenSigSendType" SG_ 164 STS_VEHICLE_SPEED_CALC 0;
BA_ "GenSigTimeoutTime" SG_ 164 STS_VEHICLE_SPEED_CALC 150;
VAL_ 3221225472 STS_AlignmentShortTrackStatus 0 "AShortTrackSts_Off" 1 "AShortTrackSts_Running" 2 "AShortTrackSts_Paused" 3 "AShortTrackSts_Failed" 4 "AShortTrackSts_Success" ;
VAL_ 3221225472 STS_VehicleCondition 0 "VelocityTooLow" 1 "VelocityTooHigh" 2 "YawRateTooHigh" 3 "QualityFctrVelocityInsufficient" 4 "QualityFctrYawRateInsufficient" 5 "VehicleInReverse" 6 "NoIssue" ;
VAL_ 3221225472 STS_AlignmentServiceStatus 0 "AServcStatus_Off" 1 "AServcStatus_Running" 2 "AServcStatus_Paused" 3 "AServcStatus_Failed" 4 "AServcStatus_Success" ;
VAL_ 3221225472 STS_AlignmentStaticStatus 0 "AlgnAuto_Off" 1 "AlgnAuto_Running" 2 "AlgnAuto_Paused" 3 "AlgnAuto_Failed" 4 "AlgnAuto_Success" ;
VAL_ 3221225472 STS_HostSpdCompensationFactorQF 0 "DRA_QF_UNKNOWN" 1 "DRA_QF_FAULTY" 2 "DRA_QF_INACCURATE" 3 "DRA_QF_ACCURATE" ;
VAL_ 3221225472 STS_AutoAlignmentFailRootCause 0 "InvalidInput" 1 "SensorFacingUpwards" 2 "SensorFacingDownwards" 3 "SensorFacingRight" 4 "SensorFacingLeft" 5 "VelocityTooLow" 6 "YawRateTooHigh" 7 "VehicleReverse" 8 "InvalidVehicleSignal" 9 "TargetsTooSlow" 10 "QualityTooLow" 11 "Blockage" 12 "OperationModeFaulty" 13 "DataQualifierInvalid" 14 "SuddenJumpDetection" 15 "CriticalMisalignment" 16 "CorruptedNVM" 17 "InaccurateMisalignValue" 18 "InitAlignNotDone" 19 "AlignQFNotOk" 20 "TrailerCncted_AutoAlgnLimited" 255 "AA_None" ;
VAL_ 3221225472 STS_AlignmentAutoStatus 0 "AAstatus_Off" 1 "AAstatus_Active" 2 "AAstatus_Paused" 3 "AAstatus_Failed" 4 "AAstatus_Success" ;
VAL_ 3221225472 STS_CalDisplay 0 "CalDisplay_None" 1 "CalDisplay_Display" ;
VAL_ 3221225472 STS_AlignmentError 0 "NoError" 1 "SensorFacingUpwards" 2 "SensorFacingDownwards" 3 "SensorFacingRight" 4 "SensorFacingLeft" 7 "TargetSignalTooWeak" 8 "TargetSignalTooStrong" 9 "TargetNotStatic" 10 "TargetDistanceTooHigh" 11 "TargetDistanceTooLow" 12 "TargetNotFound" 13 "Interference" 14 "InvalidInput" 15 "InvalidVehicleSignal" 16 "Blockage" 17 "MaxDistanceCrossed" 18 "MaxDurationCrossed" 19 "OperationModeFaulty _Dyn" 20 "DataQualifierInvalid_Dyn" ;
VAL_ 3221225472 STS_AlignmentModeOut 0 "AModeOut_Off" 1 "AutoAlignment" 2 "ShortTrackAlignment" 3 "ServiceAlignment" 4 "StaticAlignment" ;
VAL_ 3221225472 STS_InitLastSuccessfulAlignMode 0 "LastAMode_None" 1 "LastAMode_NotUsed" 2 "ShortTrackAlignment" 3 "ServiceAlignment" 4 "StaticAlignment" 5 "ExternalAlignment" ;
VAL_ 3221225472 STS_RadarTypeInput 0 "DRA_RADAR_TYPE_UNKNOWN" 1 "DRA_RADAR_TYPE_SRR6" 2 "DRA_RADAR_TYPE_SRR6P_HIGH_GAIN" 3 "DRA_RADAR_TYPE_SRR6P_LOW_GAIN" 4 "DRA_RADAR_TYPE_SRR7P" 5 "DRA_RADAR_TYPE_FLR4 " 6 "DRA_RADAR_TYPE_FLR4P" 7 "DRA_RADAR_TYPE_FLR7" ;
VAL_ 3221225472 STS_CoordinateSystemInput 0 "DRA_DET_COORD_SYS_UNDEFINED" 1 "DRA_DET_COORD_SYS_SAE" 2 "DRA_DET_COORD_SYS_ISO" ;
VAL_ 3221225472 STS_AlignmentModeIn 0 "AModeIn_Off" 1 "AutoAlignment" 2 "ShortTrackAlignment" 3 "ServiceAlignment" 4 "StaticAlignment" 5 "ManualAlignment" ;
VAL_ 3221225472 CAP_SLLMonitoringStatus 0 "SLL_Faulty" 1 "SLL_Ok" 2 "SLL_Reserved" 3 "SLL_Initialization" 4 "SLL_Invalid" ;
VAL_ 3221225472 CAP_SLLMonitoringActive 0 "SLLMonitor_Off" 1 "SLLMonitor_Active" ;
VAL_ 3221225472 CAP_RangeEstimationStatus 0 "RgeEstim_Faulty" 1 "RgeEstim_Ok" 2 "RgeEstim_Reserved" 3 "RgeEstim_Initialization" 4 "RgeEstim_Invalid" ;
VAL_ 3221225472 CAP_RangeEstimationActive 0 "RgeEstim_Off" 1 "RgeEstim_Active" ;
VAL_ 3221225472 CAP_DampingStatus 0 "Damp_Faulty" 1 "Damp_Ok" 2 "Damp_Reserved" 3 "Damp_Initialization" 4 "Damp_Invalid" ;
VAL_ 3221225472 CAP_DampingActive 0 "Damp_Off" 1 "Damp_Active" ;
VAL_ 3221225472 CAP_SLBlockageFlag 0 "Not_Degraded" 1 "Degraded" ;
VAL_ 3221225472 CAP_FreeSightCheckStatus 0 "CAP_SightCheckStatus_Ok" 1 "CAP_SightCheckStatus_Failed" 255 "CAP_SightCheckStatus_Invalid" ;
VAL_ 3221225472 CAP_FreeSightCheckActive 0 "CAP_SightCheck_Active" 1 "CAP_SightCheck_Inactive" 2 "CAP_SightCheck_Paused" 255 "CAP_SightCheck_Invalid" ;
VAL_ 3221225472 CAP_BlockageValue 0 "Not_Blocked" 1 "Slightly_Blocked" 2 "Moderately_Blocked" 3 "Highly_Blocked" 4 "Fully_Blocked" 5 "Limited_Sight" 6 "BlockgVal_Invalid" ;
VAL_ 3221225472 CAP_BlockageStatus 0 "BlockSts_Faulty" 1 "BlockSts_Ok" 2 "BlockSts_Reserved" 3 "BlockSts_Initialization" 4 "BlockSts_Invalid" ;
VAL_ 3221225472 CAP_BlockageActive 0 "Blockage_Active" 1 "Blockage_Off" ;
VAL_ 3221225472 CAP_BlockageSensitivity 0 "CAP_BlockgSens_Low" 1 "CAP_BlockgSens_Mid" 2 "CAP_BlockgSens_High" 255 "CAP_BlockgSens_Invalid" ;
VAL_ 3221225472 STS_PLATFORM_VARIANT 18 "VARIANT_FLR8" 17 " VARIANT_SRR8" 0 "VARIANT_INVALID" 1 "VARIANT_MRR3" 2 "VARIANT_SRR5" 3 "VARIANT_RACAM" 4 "VARIANT_MRR360" 5 "VARIANT_MRR3LLP" 6 "VARIANT_MRR3LLP_STD" 7 "VARIANT_MRR3LLP_AMOD" 8 "VARIANT_SRRAD" 9 "VARIANT_FLR4" 10 "VARIANT_FLR4PLUS" 11 "VARIANT_SRR6" 12 "VARIANT_SRR6PLUS" 13 "VARIANT_SRR_V2" 14 "VARIANT_FLR_V2" 15 "VARIANT_SRR_V1" 16 "VARIANT_FLR_V1" ;
VAL_ 3221225472 STS_HARDWARE_VERSION 0 "EDU" 1 "A1" 2 "B1_USCAR" 3 "CEER" 4 "UNDEFINED" 5 "RESERVED" ;
VAL_ 3221225472 STS_SMC_PLATFROM_VERSION 0 "INVALID" 1 "MRR3" 2 "SRR5" 3 "RACAM" 4 "MRR360" 5 "MRR3LLP" 6 "MRRLLP_STD" 7 "MRRLLP_AMOD" 8 "SRRAD" 9 "FLR4" 10 "FLR4PLUS" 11 "SRR6" 12 "SRR6PLUS" 13 "SRR8" 14 "FLR8" ;
VAL_ 3221225472 STS_SENSOR_POSITION 0 "Reserved_0" 1 "Rear_Left" 2 "Rear_Right" 3 "Front_Right" 4 "Front_Left" 5 "Front_Center" 6 "Reserved_6" 7 "Reserved_7" ;
VAL_ 3221225472 STS_Yaw_Rate_Calc_QF 0 "YawRateCalcQF_Undefined" 1 "YawRateCalcQF_TempUndefined" 2 "YawRateCalcQF_Innaccurate" 3 "YawRateCalcQF_Accurate" ;
VAL_ 3221225472 STS_Vehicle_Speed_Calc_QF 0 "VehSpdCalcQF_Undefined" 1 "VehSpdCalcQF_TempUndefined" 2 "VehSpdCalcQF_Innaccurate" 3 "VehSpdCalcQF_Accurate" ;
VAL_ 3221225472 STS_Gear_Position 0 "GearPosition_Park" 1 "GearPosition_Reverse" 2 "GearPosition_Neutral" 3 "GearPosition_Drive" 4 "GearPosition_Sport_DriveSport" 5 "GearPosition_Low" 6 "GearPosition_First" 7 "GearPosition_Second" 8 "GearPosition_Third" 9 "GearPosition_Fourth" 10 "GearPosition_Fifth" 11 "GearPosition_Sixth" 12 "GearPosition_NotUsed_1" 13 "GearPosition_NotUsed_2" 14 "GearPosition_Unknown_Position" 15 "GearPosition_Fault" ;
VAL_ 3221225472 STS_VEHICLE_SUPPLY_VOLTAGE 0 "Under Voltage " 1 "Low Voltage" 2 "Normal Voltage" 3 "High Voltage" 4 "Over Voltage" ;
VAL_ 3221225472 STS_BRR_STATUS 0 "BRR_Inactive" 1 "BRR_Active" 2 "BRR_Fault" ;
VAL_ 3221225472 STS_SCAN_TYPE 0 "MEDIUM_LOOK" 1 "LONG_LOOK" ;
VAL_ 3221225472 HED_Rain_Level 0 "No_Rain" 1 "Low_Medium" 2 "Medium_High" ;
VAL_ 3221225472 HED_SLOPE_CORR_EXECUTIONFLAG 0 "AzimuthElevationNotCompensated" 1 "AzimuthCompensated" 2 "ElevationCompensated" 3 "AzimuthElevationCompensated" ;
VAL_ 3221225472 HED_OPERATION_MODE 0 "Init_MCU" 1 "Radar_Not_Configured" 2 "Operational" 3 "OpMode_Faulty" 4 "Shutdown_Initiated" 5 "Shutdown_Completed" ;
VAL_ 3221225472 HED_LOOK_ID 0 "LOOK_A" 1 "LOOK_B" 2 "LOOK_C" 3 "LOOK_D" ;
VAL_ 3221225472 HED_DATA_QUALIFIER 0 "DataQual_Invalid" 1 "Not_Available" 2 "Reduced_In_Performance" 3 "Test_Mode" 4 "DataQual_Normal" 5 "Reduced_In_Coverage" 6 "Reduced_In_Perf_And_Cov" 7 "DataQual_Unknown" ;
VAL_ 3221225472 HED_TIME_SYNC_SRC_MASTER 0 "LOCAL" 1 "GLOBAL" ;
VAL_ 3221225472 HED_TIME_SYNC_VALIDITY_FLAG 0 "OUT_OF_SYNC" 1 "SYNCED_AT_LEAST_ONCE" 2 "SYNC_MSG_TIMEOUT_OR_CRC_ERR" ;
VAL_ 132 STS_Yaw_Rate_Calc_QF 0 "YawRateCalcQF_Undefined" 1 "YawRateCalcQF_TempUndefined" 2 "YawRateCalcQF_Innaccurate" 3 "YawRateCalcQF_Accurate" ;
VAL_ 132 STS_Vehicle_Speed_Calc_QF 0 "VehSpdCalcQF_Undefined" 1 "VehSpdCalcQF_TempUndefined" 2 "VehSpdCalcQF_Innaccurate" 3 "VehSpdCalcQF_Accurate" ;
VAL_ 132 STS_Gear_Position 0 "GearPosition_Park" 1 "GearPosition_Reverse" 2 "GearPosition_Neutral" 3 "GearPosition_Drive" 4 "GearPosition_Sport_DriveSport" 5 "GearPosition_Low" 6 "GearPosition_First" 7 "GearPosition_Second" 8 "GearPosition_Third" 9 "GearPosition_Fourth" 10 "GearPosition_Fifth" 11 "GearPosition_Sixth" 12 "GearPosition_NotUsed_1" 13 "GearPosition_NotUsed_2" 14 "GearPosition_Unknown_Position" 15 "GearPosition_Fault" ;
VAL_ 132 STS_VEHICLE_SUPPLY_VOLTAGE 0 "Under Voltage " 1 "Low Voltage" 2 "Normal Voltage" 3 "High Voltage" 4 "Over Voltage" ;
VAL_ 132 STS_BRR_STATUS 0 "BRR_Inactive" 1 "BRR_Active" 2 "BRR_Fault" ;
VAL_ 132 STS_SCAN_TYPE 0 "MEDIUM_LOOK" 1 "LONG_LOOK" ;
VAL_ 131 STS_PLATFORM_VARIANT 18 "VARIANT_FLR8" 17 " VARIANT_SRR8" 0 "VARIANT_INVALID" 1 "VARIANT_MRR3" 2 "VARIANT_SRR5" 3 "VARIANT_RACAM" 4 "VARIANT_MRR360" 5 "VARIANT_MRR3LLP" 6 "VARIANT_MRR3LLP_STD" 7 "VARIANT_MRR3LLP_AMOD" 8 "VARIANT_SRRAD" 9 "VARIANT_FLR4" 10 "VARIANT_FLR4PLUS" 11 "VARIANT_SRR6" 12 "VARIANT_SRR6PLUS" 13 "VARIANT_SRR_V2" 14 "VARIANT_FLR_V2" 15 "VARIANT_SRR_V1" 16 "VARIANT_FLR_V1" ;
VAL_ 131 STS_HARDWARE_VERSION 0 "EDU" 1 "A1" 2 "B1_USCAR" 3 "CEER" 4 "UNDEFINED" 5 "RESERVED" ;
VAL_ 131 STS_SMC_PLATFROM_VERSION 0 "INVALID" 1 "MRR3" 2 "SRR5" 3 "RACAM" 4 "MRR360" 5 "MRR3LLP" 6 "MRRLLP_STD" 7 "MRRLLP_AMOD" 8 "SRRAD" 9 "FLR4" 10 "FLR4PLUS" 11 "SRR6" 12 "SRR6PLUS" 13 "SRR8" 14 "FLR8" ;
VAL_ 131 STS_SENSOR_POSITION 0 "Reserved_0" 1 "Rear_Left" 2 "Rear_Right" 3 "Front_Right" 4 "Front_Left" 5 "Front_Center" 6 "Reserved_6" 7 "Reserved_7" ;
VAL_ 128 HED_Rain_Level 0 "No_Rain" 1 "Low_Medium" 2 "Medium_High" ;
VAL_ 128 HED_SLOPE_CORR_EXECUTIONFLAG 0 "AzimuthElevationNotCompensated" 1 "AzimuthCompensated" 2 "ElevationCompensated" 3 "AzimuthElevationCompensated" ;
VAL_ 128 HED_OPERATION_MODE 0 "Init_MCU" 1 "Radar_Not_Configured" 2 "Operational" 3 "OpMode_Faulty" 4 "Shutdown_Initiated" 5 "Shutdown_Completed" ;
VAL_ 128 HED_LOOK_ID 0 "LOOK_A" 1 "LOOK_B" 2 "LOOK_C" 3 "LOOK_D" ;
VAL_ 128 HED_DATA_QUALIFIER 0 "DataQual_Invalid" 1 "Not_Available" 2 "Reduced_In_Performance" 3 "Test_Mode" 4 "DataQual_Normal" 5 "Reduced_In_Coverage" 6 "Reduced_In_Perf_And_Cov" 7 "DataQual_Unknown" ;
VAL_ 128 HED_TIME_SYNC_SRC_MASTER 0 "LOCAL" 1 "GLOBAL" ;
VAL_ 128 HED_TIME_SYNC_VALIDITY_FLAG 0 "OUT_OF_SYNC" 1 "SYNCED_AT_LEAST_ONCE" 2 "SYNC_MSG_TIMEOUT_OR_CRC_ERR" ;
VAL_ 164 STS_Yaw_Rate_Calc_QF 0 "YawRateCalcQF_Undefined" 1 "YawRateCalcQF_TempUndefined" 2 "YawRateCalcQF_Innaccurate" 3 "YawRateCalcQF_Accurate" ;
VAL_ 164 STS_Vehicle_Speed_Calc_QF 0 "VehSpdCalcQF_Undefined" 1 "VehSpdCalcQF_TempUndefined" 2 "VehSpdCalcQF_Innaccurate" 3 "VehSpdCalcQF_Accurate" ;
VAL_ 164 STS_Gear_Position 0 "GearPosition_Park" 1 "GearPosition_Reverse" 2 "GearPosition_Neutral" 3 "GearPosition_Drive" 4 "GearPosition_Sport_DriveSport" 5 "GearPosition_Low" 6 "GearPosition_First" 7 "GearPosition_Second" 8 "GearPosition_Third" 9 "GearPosition_Fourth" 10 "GearPosition_Fifth" 11 "GearPosition_Sixth" 12 "GearPosition_NotUsed_1" 13 "GearPosition_NotUsed_2" 14 "GearPosition_Unknown_Position" 15 "GearPosition_Fault" ;
VAL_ 164 STS_VEHICLE_SUPPLY_VOLTAGE 0 "Under Voltage " 1 "Low Voltage" 2 "Normal Voltage" 3 "High Voltage" 4 "Over Voltage" ;
VAL_ 164 STS_BRR_STATUS 0 "BRR_Inactive" 1 "BRR_Active" 2 "BRR_Fault" ;
VAL_ 164 STS_SCAN_TYPE 0 "MEDIUM_LOOK" 1 "LONG_LOOK" ;
SIG_GROUP_ 1796 FCM_IFV_SWVersion 1 :;
SIG_GROUP_ 82 FCM_XCP_DAQ_RESP 1 : STS_XCP_RES_DAQ_Byte63 STS_XCP_RES_DAQ_Byte62 STS_XCP_RES_DAQ_Byte61 STS_XCP_RES_DAQ_Byte60 STS_XCP_RES_DAQ_Byte59 STS_XCP_RES_DAQ_Byte58 STS_XCP_RES_DAQ_Byte57 STS_XCP_RES_DAQ_Byte56 STS_XCP_RES_DAQ_Byte55 STS_XCP_RES_DAQ_Byte54 STS_XCP_RES_DAQ_Byte53 STS_XCP_RES_DAQ_Byte52 STS_XCP_RES_DAQ_Byte51 STS_XCP_RES_DAQ_Byte50 STS_XCP_RES_DAQ_Byte49 STS_XCP_RES_DAQ_Byte48 STS_XCP_RES_DAQ_Byte47 STS_XCP_RES_DAQ_Byte46 STS_XCP_RES_DAQ_Byte45 STS_XCP_RES_DAQ_Byte44 STS_XCP_RES_DAQ_Byte43 STS_XCP_RES_DAQ_Byte42 STS_XCP_RES_DAQ_Byte41 STS_XCP_RES_DAQ_Byte40 STS_XCP_RES_DAQ_Byte39 STS_XCP_RES_DAQ_Byte38 STS_XCP_RES_DAQ_Byte37 STS_XCP_RES_DAQ_Byte36 STS_XCP_RES_DAQ_Byte35 STS_XCP_RES_DAQ_Byte34 STS_XCP_RES_DAQ_Byte33 STS_XCP_RES_DAQ_Byte32 STS_XCP_RES_DAQ_Byte31 STS_XCP_RES_DAQ_Byte30 STS_XCP_RES_DAQ_Byte29 STS_XCP_RES_DAQ_Byte28 STS_XCP_RES_DAQ_Byte27 STS_XCP_RES_DAQ_Byte26 STS_XCP_RES_DAQ_Byte25 STS_XCP_RES_DAQ_Byte24 STS_XCP_RES_DAQ_Byte23 STS_XCP_RES_DAQ_Byte22 STS_XCP_RES_DAQ_Byte21 STS_XCP_RES_DAQ_Byte20 STS_XCP_RES_DAQ_Byte19 STS_XCP_RES_DAQ_Byte18 STS_XCP_RES_DAQ_Byte17 STS_XCP_RES_DAQ_Byte16 STS_XCP_RES_DAQ_Byte15 STS_XCP_RES_DAQ_Byte14 STS_XCP_RES_DAQ_Byte13 STS_XCP_RES_DAQ_Byte12 STS_XCP_RES_DAQ_Byte11 STS_XCP_RES_DAQ_Byte10 STS_XCP_RES_DAQ_Byte9 STS_XCP_RES_DAQ_Byte8 STS_XCP_RES_DAQ_Byte7 STS_XCP_RES_DAQ_Byte6 STS_XCP_RES_DAQ_Byte5 STS_XCP_RES_DAQ_Byte4 STS_XCP_RES_DAQ_Byte3 STS_XCP_RES_DAQ_Byte2 STS_XCP_RES_DAQ_Byte1 STS_XCP_RES_DAQ_Byte0;
SIG_GROUP_ 81 FCM_XCP_CTO_RESP 1 : STS_XCP_RES_CTO_Byte63 STS_XCP_RES_CTO_Byte62 STS_XCP_RES_CTO_Byte61 STS_XCP_RES_CTO_Byte60 STS_XCP_RES_CTO_Byte59 STS_XCP_RES_CTO_Byte58 STS_XCP_RES_CTO_Byte57 STS_XCP_RES_CTO_Byte56 STS_XCP_RES_CTO_Byte55 STS_XCP_RES_CTO_Byte54 STS_XCP_RES_CTO_Byte53 STS_XCP_RES_CTO_Byte52 STS_XCP_RES_CTO_Byte51 STS_XCP_RES_CTO_Byte50 STS_XCP_RES_CTO_Byte49 STS_XCP_RES_CTO_Byte48 STS_XCP_RES_CTO_Byte47 STS_XCP_RES_CTO_Byte46 STS_XCP_RES_CTO_Byte45 STS_XCP_RES_CTO_Byte44 STS_XCP_RES_CTO_Byte43 STS_XCP_RES_CTO_Byte42 STS_XCP_RES_CTO_Byte41 STS_XCP_RES_CTO_Byte40 STS_XCP_RES_CTO_Byte39 STS_XCP_RES_CTO_Byte38 STS_XCP_RES_CTO_Byte37 STS_XCP_RES_CTO_Byte36 STS_XCP_RES_CTO_Byte35 STS_XCP_RES_CTO_Byte34 STS_XCP_RES_CTO_Byte33 STS_XCP_RES_CTO_Byte32 STS_XCP_RES_CTO_Byte0 STS_XCP_RES_CTO_Byte1 STS_XCP_RES_CTO_Byte2 STS_XCP_RES_CTO_Byte3 STS_XCP_RES_CTO_Byte4 STS_XCP_RES_CTO_Byte5 STS_XCP_RES_CTO_Byte6 STS_XCP_RES_CTO_Byte7 STS_XCP_RES_CTO_Byte8 STS_XCP_RES_CTO_Byte9 STS_XCP_RES_CTO_Byte10 STS_XCP_RES_CTO_Byte11 STS_XCP_RES_CTO_Byte12 STS_XCP_RES_CTO_Byte13 STS_XCP_RES_CTO_Byte14 STS_XCP_RES_CTO_Byte15 STS_XCP_RES_CTO_Byte16 STS_XCP_RES_CTO_Byte17 STS_XCP_RES_CTO_Byte18 STS_XCP_RES_CTO_Byte19 STS_XCP_RES_CTO_Byte20 STS_XCP_RES_CTO_Byte21 STS_XCP_RES_CTO_Byte22 STS_XCP_RES_CTO_Byte23 STS_XCP_RES_CTO_Byte24 STS_XCP_RES_CTO_Byte25 STS_XCP_RES_CTO_Byte26 STS_XCP_RES_CTO_Byte27 STS_XCP_RES_CTO_Byte28 STS_XCP_RES_CTO_Byte29 STS_XCP_RES_CTO_Byte30 STS_XCP_RES_CTO_Byte31;
SIG_GROUP_ 80 FCM_XCP_CTO_REQ 1 : STS_XCP_REQ_CTO_Byte63 STS_XCP_REQ_CTO_Byte62 STS_XCP_REQ_CTO_Byte61 STS_XCP_REQ_CTO_Byte60 STS_XCP_REQ_CTO_Byte59 STS_XCP_REQ_CTO_Byte58 STS_XCP_REQ_CTO_Byte57 STS_XCP_REQ_CTO_Byte56 STS_XCP_REQ_CTO_Byte55 STS_XCP_REQ_CTO_Byte54 STS_XCP_REQ_CTO_Byte53 STS_XCP_REQ_CTO_Byte52 STS_XCP_REQ_CTO_Byte51 STS_XCP_REQ_CTO_Byte50 STS_XCP_REQ_CTO_Byte49 STS_XCP_REQ_CTO_Byte48 STS_XCP_REQ_CTO_Byte47 STS_XCP_REQ_CTO_Byte46 STS_XCP_REQ_CTO_Byte45 STS_XCP_REQ_CTO_Byte44 STS_XCP_REQ_CTO_Byte43 STS_XCP_REQ_CTO_Byte42 STS_XCP_REQ_CTO_Byte41 STS_XCP_REQ_CTO_Byte40 STS_XCP_REQ_CTO_Byte39 STS_XCP_REQ_CTO_Byte38 STS_XCP_REQ_CTO_Byte37 STS_XCP_REQ_CTO_Byte36 STS_XCP_REQ_CTO_Byte35 STS_XCP_REQ_CTO_Byte34 STS_XCP_REQ_CTO_Byte33 STS_XCP_REQ_CTO_Byte32 STS_PID STS_XCP_REQ_CTO_Byte1 STS_XCP_REQ_CTO_Byte2 STS_XCP_REQ_CTO_Byte3 STS_XCP_REQ_CTO_Byte4 STS_XCP_REQ_CTO_Byte5 STS_XCP_REQ_CTO_Byte6 STS_XCP_REQ_CTO_Byte7 STS_XCP_REQ_CTO_Byte8 STS_XCP_REQ_CTO_Byte9 STS_XCP_REQ_CTO_Byte10 STS_XCP_REQ_CTO_Byte11 STS_XCP_REQ_CTO_Byte12 STS_XCP_REQ_CTO_Byte13 STS_XCP_REQ_CTO_Byte14 STS_XCP_REQ_CTO_Byte15 STS_XCP_REQ_CTO_Byte16 STS_XCP_REQ_CTO_Byte17 STS_XCP_REQ_CTO_Byte18 STS_XCP_REQ_CTO_Byte19 STS_XCP_REQ_CTO_Byte20 STS_XCP_REQ_CTO_Byte21 STS_XCP_REQ_CTO_Byte22 STS_XCP_REQ_CTO_Byte23 STS_XCP_REQ_CTO_Byte24 STS_XCP_REQ_CTO_Byte25 STS_XCP_REQ_CTO_Byte26 STS_XCP_REQ_CTO_Byte27 STS_XCP_REQ_CTO_Byte28 STS_XCP_REQ_CTO_Byte29 STS_XCP_REQ_CTO_Byte30 STS_XCP_REQ_CTO_Byte31;
SIG_GROUP_ 132 SRR_RL_RadarStatus2 1 : STS_INTRFC_VERSION_ID_PATCH STS_INTRFC_VERSION_ID_MINOR STS_INTRFC_VERSION_ID_MAJOR STS_Yaw_Rate_Calc_QF STS_Vehicle_Speed_Calc_QF STS_Gear_Position STS_RAIN_COUNT STS_Last_CAN_Det_Inst_Latency STS_First_CAN_Det_Inst_Latency STS_CORE_ACTV_FLT_BYTE_0_to_3 STS_CORE_ACTV_FLT_BYTE_8_to_11 STS_CORE_ACTV_FLT_BYTE_11_to_15 STS_Project_ACTV_FLT_BYTE_0_to_3 STS_Project_ACTV_FLT_BYTE_4_to_5 STS_CAN_NM_State STS_TIME_SYNC_OFFSET STS_RDD_CORE_THROUGHPUT STS_MH_002_CRC16 STS_MH_002_CYCLE_COUNTER STS_NO_TSYN_ERROR STS_POINT_OF_TRIGGER STS_BRR_STATUS STS_CORE_ACTV_FLT_BYTE_4_to_7 STS_MMIC_TEMP_TX1_2 STS_MMIC_TEMP_TX3_4 STS_MCU_TEMP STS_MMIC_TEMP_RX STS_MMIC_TEMP_TX0 STS_XCVR_OPERATIONAL STS_SCAN_TYPE STS_AF_CORE_THROUGHPUT STS_MMIC_RE_INIT_COUNT STS_VEHICLE_SPEED_CALC STS_STEERING_ANGLE STS_STEERING_ANGLE_SIGN STS_VEH_SPEED_DIRECTION STS_YAW_RATE_BIAS STS_VEHICLE_SUPPLY_VOLTAGE;
SIG_GROUP_ 131 SRR_RL_RadarStatus1 1 : STS_DIST_FRNT_BMPR_TO_RR_AXL STS_MH_001_CYCLE_COUNTER STS_MH_001_CRC16 STS_SMC_PLATFROM_VERSION STS_SMC_SECTION_COMPTBLITY STS_SMC_CAL_VER_MINOR STS_SMC_CAL_VER_MAJOR STS_USC_SECTION_COMPTBLITY STS_USC_CAL_VER_MINOR STS_USC_CAL_VER_MAJOR STS_SENSOR_POSITION STS_SENSOR_HEIGHT STS_SENSOR_MOUNT_ORNT_ROLL STS_SENSOR_MOUNT_ORNT_PITCH STS_SENSOR_MOUNT_ORNT_YAW STS_SENSOR_MOUNT_POS_Z STS_SENSOR_MOUNT_POS_Y STS_SENSOR_MOUNT_POS_X STS_SENSOR_POLARITY STS_PBL_VERSION_FIELD4 STS_PBL_VERSION_FIELD3 STS_PBL_VERSION_FIELD2 STS_PBL_VERSION_FIELD1 STS_SW_VERSION_FIELD4 STS_SW_VERSION_FIELD3 STS_SW_VERSION_FIELD2 STS_SW_VERSION_FIELD1 STS_DET_DBC_BASE_VER_MAJOR STS_DET_DBC_BASE_VER_MINOR STS_SERIAL_NUM_JULIAN_DAY STS_SERIAL_NUM_JULIAN_YEAR STS_SERIAL_NUMBER_SEQUENCE STS_HARDWARE_VERSION STS_PCAN_PROTOCOL_VER_MAJOR STS_PLATFORM_VARIANT STS_PCAN_PROTOCOL_VER_MINOR STS_TIME_SINCE_POWER_ON STS_AF_TIME_INST STS_AF_TIME_PEAK STS_MAIN_CORE_TIME_INST STS_MAIN_CORE_TIME_PEAK STS_RDD_CORE_TIME_INST STS_RDD_CORE_TIME_PEAK STS_SP_CORE_TIME_INST STS_SP_CORE_TIME_PEAK;
SIG_GROUP_ 128 SRR_RL_RadarHeader 1 : HED_RDR_HEADER_CMAC HED_RDR_HEADER_FV HED_Rain_Level HED_MH_CRC16 HED_MH_CYCLE_COUNTER HED_Auth_CRC32 HED_FOV_VER_MIN HED_FOV_HOR_MIN HED_DET_SPEED_RANGE_MIN HED_DET_RANGE_MIN HED_FOV_VER_MAX HED_FOV_HOR_MAX HED_DET_SPEED_RANGE_MAX HED_DET_RANGE_MAX HED_R_WRAPPING HED_V_WRAPPING HED_DATA_QUALIFIER HED_SCAN_INDEX HED_LOOK_ID HED_NUM_OF_VALID_DETECTIONS HED_ALIGN_HOR_REF HED_LOOK_INDEX HED_ALIGN_VER_REF HED_TRIGGER_TIME HED_TIME_SYNC_VALIDITY_FLAG HED_TIME_SYNC_SRC_MASTER HED_SENSOR_TIME_STAMP_NS HED_SENSOR_TIME_STAMP_SEC HED_DET_BI_STATIC_COUNT HED_DET_NUM_OF_2PASS HED_DET_NUM_OF_1PASS HED_NUM_OF_RESTBINS_USED HED_MAX_NUM_OF_DETECTIONS HED_OPERATION_MODE HED_PROCESSED_RANGE HED_SLOPE_CORR_EXECUTIONFLAG;
SIG_GROUP_ 50 FLR_XCP_DAQ_RESP 1 : STS_XCP_RES_DAQ_Byte63 STS_XCP_RES_DAQ_Byte62 STS_XCP_RES_DAQ_Byte61 STS_XCP_RES_DAQ_Byte60 STS_XCP_RES_DAQ_Byte59 STS_XCP_RES_DAQ_Byte58 STS_XCP_RES_DAQ_Byte57 STS_XCP_RES_DAQ_Byte56 STS_XCP_RES_DAQ_Byte55 STS_XCP_RES_DAQ_Byte54 STS_XCP_RES_DAQ_Byte53 STS_XCP_RES_DAQ_Byte52 STS_XCP_RES_DAQ_Byte51 STS_XCP_RES_DAQ_Byte50 STS_XCP_RES_DAQ_Byte49 STS_XCP_RES_DAQ_Byte48 STS_XCP_RES_DAQ_Byte47 STS_XCP_RES_DAQ_Byte46 STS_XCP_RES_DAQ_Byte45 STS_XCP_RES_DAQ_Byte44 STS_XCP_RES_DAQ_Byte43 STS_XCP_RES_DAQ_Byte42 STS_XCP_RES_DAQ_Byte41 STS_XCP_RES_DAQ_Byte40 STS_XCP_RES_DAQ_Byte39 STS_XCP_RES_DAQ_Byte38 STS_XCP_RES_DAQ_Byte37 STS_XCP_RES_DAQ_Byte36 STS_XCP_RES_DAQ_Byte35 STS_XCP_RES_DAQ_Byte34 STS_XCP_RES_DAQ_Byte33 STS_XCP_RES_DAQ_Byte32 STS_XCP_RES_DAQ_Byte31 STS_XCP_RES_DAQ_Byte30 STS_XCP_RES_DAQ_Byte29 STS_XCP_RES_DAQ_Byte28 STS_XCP_RES_DAQ_Byte27 STS_XCP_RES_DAQ_Byte26 STS_XCP_RES_DAQ_Byte25 STS_XCP_RES_DAQ_Byte24 STS_XCP_RES_DAQ_Byte23 STS_XCP_RES_DAQ_Byte22 STS_XCP_RES_DAQ_Byte21 STS_XCP_RES_DAQ_Byte20 STS_XCP_RES_DAQ_Byte19 STS_XCP_RES_DAQ_Byte18 STS_XCP_RES_DAQ_Byte17 STS_XCP_RES_DAQ_Byte16 STS_XCP_RES_DAQ_Byte15 STS_XCP_RES_DAQ_Byte14 STS_XCP_RES_DAQ_Byte13 STS_XCP_RES_DAQ_Byte12 STS_XCP_RES_DAQ_Byte11 STS_XCP_RES_DAQ_Byte10 STS_XCP_RES_DAQ_Byte9 STS_XCP_RES_DAQ_Byte8 STS_XCP_RES_DAQ_Byte7 STS_XCP_RES_DAQ_Byte6 STS_XCP_RES_DAQ_Byte5 STS_XCP_RES_DAQ_Byte4 STS_XCP_RES_DAQ_Byte3 STS_XCP_RES_DAQ_Byte2 STS_XCP_RES_DAQ_Byte1 STS_XCP_RES_DAQ_Byte0;
SIG_GROUP_ 49 FLR_XCP_CTO_RESP 1 : STS_XCP_RES_CTO_Byte63 STS_XCP_RES_CTO_Byte62 STS_XCP_RES_CTO_Byte61 STS_XCP_RES_CTO_Byte60 STS_XCP_RES_CTO_Byte59 STS_XCP_RES_CTO_Byte58 STS_XCP_RES_CTO_Byte57 STS_XCP_RES_CTO_Byte56 STS_XCP_RES_CTO_Byte55 STS_XCP_RES_CTO_Byte54 STS_XCP_RES_CTO_Byte53 STS_XCP_RES_CTO_Byte52 STS_XCP_RES_CTO_Byte51 STS_XCP_RES_CTO_Byte50 STS_XCP_RES_CTO_Byte49 STS_XCP_RES_CTO_Byte48 STS_XCP_RES_CTO_Byte47 STS_XCP_RES_CTO_Byte46 STS_XCP_RES_CTO_Byte45 STS_XCP_RES_CTO_Byte44 STS_XCP_RES_CTO_Byte43 STS_XCP_RES_CTO_Byte42 STS_XCP_RES_CTO_Byte41 STS_XCP_RES_CTO_Byte40 STS_XCP_RES_CTO_Byte39 STS_XCP_RES_CTO_Byte38 STS_XCP_RES_CTO_Byte37 STS_XCP_RES_CTO_Byte36 STS_XCP_RES_CTO_Byte35 STS_XCP_RES_CTO_Byte34 STS_XCP_RES_CTO_Byte33 STS_XCP_RES_CTO_Byte32 STS_XCP_RES_CTO_Byte0 STS_XCP_RES_CTO_Byte1 STS_XCP_RES_CTO_Byte2 STS_XCP_RES_CTO_Byte3 STS_XCP_RES_CTO_Byte4 STS_XCP_RES_CTO_Byte5 STS_XCP_RES_CTO_Byte6 STS_XCP_RES_CTO_Byte7 STS_XCP_RES_CTO_Byte8 STS_XCP_RES_CTO_Byte9 STS_XCP_RES_CTO_Byte10 STS_XCP_RES_CTO_Byte11 STS_XCP_RES_CTO_Byte12 STS_XCP_RES_CTO_Byte13 STS_XCP_RES_CTO_Byte14 STS_XCP_RES_CTO_Byte15 STS_XCP_RES_CTO_Byte16 STS_XCP_RES_CTO_Byte17 STS_XCP_RES_CTO_Byte18 STS_XCP_RES_CTO_Byte19 STS_XCP_RES_CTO_Byte20 STS_XCP_RES_CTO_Byte21 STS_XCP_RES_CTO_Byte22 STS_XCP_RES_CTO_Byte23 STS_XCP_RES_CTO_Byte24 STS_XCP_RES_CTO_Byte25 STS_XCP_RES_CTO_Byte26 STS_XCP_RES_CTO_Byte27 STS_XCP_RES_CTO_Byte28 STS_XCP_RES_CTO_Byte29 STS_XCP_RES_CTO_Byte30 STS_XCP_RES_CTO_Byte31;
SIG_GROUP_ 48 FLR_XCP_CTO_REQ 1 : STS_XCP_REQ_CTO_Byte63 STS_XCP_REQ_CTO_Byte62 STS_XCP_REQ_CTO_Byte61 STS_XCP_REQ_CTO_Byte60 STS_XCP_REQ_CTO_Byte59 STS_XCP_REQ_CTO_Byte58 STS_XCP_REQ_CTO_Byte57 STS_XCP_REQ_CTO_Byte56 STS_XCP_REQ_CTO_Byte55 STS_XCP_REQ_CTO_Byte54 STS_XCP_REQ_CTO_Byte53 STS_XCP_REQ_CTO_Byte52 STS_XCP_REQ_CTO_Byte51 STS_XCP_REQ_CTO_Byte50 STS_XCP_REQ_CTO_Byte49 STS_XCP_REQ_CTO_Byte48 STS_XCP_REQ_CTO_Byte47 STS_XCP_REQ_CTO_Byte46 STS_XCP_REQ_CTO_Byte45 STS_XCP_REQ_CTO_Byte44 STS_XCP_REQ_CTO_Byte43 STS_XCP_REQ_CTO_Byte42 STS_XCP_REQ_CTO_Byte41 STS_XCP_REQ_CTO_Byte40 STS_XCP_REQ_CTO_Byte39 STS_XCP_REQ_CTO_Byte38 STS_XCP_REQ_CTO_Byte37 STS_XCP_REQ_CTO_Byte36 STS_XCP_REQ_CTO_Byte35 STS_XCP_REQ_CTO_Byte34 STS_XCP_REQ_CTO_Byte33 STS_XCP_REQ_CTO_Byte32 STS_PID STS_XCP_REQ_CTO_Byte1 STS_XCP_REQ_CTO_Byte2 STS_XCP_REQ_CTO_Byte3 STS_XCP_REQ_CTO_Byte4 STS_XCP_REQ_CTO_Byte5 STS_XCP_REQ_CTO_Byte6 STS_XCP_REQ_CTO_Byte7 STS_XCP_REQ_CTO_Byte8 STS_XCP_REQ_CTO_Byte9 STS_XCP_REQ_CTO_Byte10 STS_XCP_REQ_CTO_Byte11 STS_XCP_REQ_CTO_Byte12 STS_XCP_REQ_CTO_Byte13 STS_XCP_REQ_CTO_Byte14 STS_XCP_REQ_CTO_Byte15 STS_XCP_REQ_CTO_Byte16 STS_XCP_REQ_CTO_Byte17 STS_XCP_REQ_CTO_Byte18 STS_XCP_REQ_CTO_Byte19 STS_XCP_REQ_CTO_Byte20 STS_XCP_REQ_CTO_Byte21 STS_XCP_REQ_CTO_Byte22 STS_XCP_REQ_CTO_Byte23 STS_XCP_REQ_CTO_Byte24 STS_XCP_REQ_CTO_Byte25 STS_XCP_REQ_CTO_Byte26 STS_XCP_REQ_CTO_Byte27 STS_XCP_REQ_CTO_Byte28 STS_XCP_REQ_CTO_Byte29 STS_XCP_REQ_CTO_Byte30 STS_XCP_REQ_CTO_Byte31;
SIG_GROUP_ 18 SRR_RL_XCP_DAQ_RESP 1 : STS_XCP_RES_DAQ_Byte63 STS_XCP_RES_DAQ_Byte62 STS_XCP_RES_DAQ_Byte61 STS_XCP_RES_DAQ_Byte60 STS_XCP_RES_DAQ_Byte59 STS_XCP_RES_DAQ_Byte58 STS_XCP_RES_DAQ_Byte57 STS_XCP_RES_DAQ_Byte56 STS_XCP_RES_DAQ_Byte55 STS_XCP_RES_DAQ_Byte54 STS_XCP_RES_DAQ_Byte53 STS_XCP_RES_DAQ_Byte52 STS_XCP_RES_DAQ_Byte51 STS_XCP_RES_DAQ_Byte50 STS_XCP_RES_DAQ_Byte49 STS_XCP_RES_DAQ_Byte48 STS_XCP_RES_DAQ_Byte47 STS_XCP_RES_DAQ_Byte46 STS_XCP_RES_DAQ_Byte45 STS_XCP_RES_DAQ_Byte44 STS_XCP_RES_DAQ_Byte43 STS_XCP_RES_DAQ_Byte42 STS_XCP_RES_DAQ_Byte41 STS_XCP_RES_DAQ_Byte40 STS_XCP_RES_DAQ_Byte39 STS_XCP_RES_DAQ_Byte38 STS_XCP_RES_DAQ_Byte37 STS_XCP_RES_DAQ_Byte36 STS_XCP_RES_DAQ_Byte35 STS_XCP_RES_DAQ_Byte34 STS_XCP_RES_DAQ_Byte33 STS_XCP_RES_DAQ_Byte32 STS_XCP_RES_DAQ_Byte31 STS_XCP_RES_DAQ_Byte30 STS_XCP_RES_DAQ_Byte29 STS_XCP_RES_DAQ_Byte28 STS_XCP_RES_DAQ_Byte27 STS_XCP_RES_DAQ_Byte26 STS_XCP_RES_DAQ_Byte25 STS_XCP_RES_DAQ_Byte24 STS_XCP_RES_DAQ_Byte23 STS_XCP_RES_DAQ_Byte22 STS_XCP_RES_DAQ_Byte21 STS_XCP_RES_DAQ_Byte20 STS_XCP_RES_DAQ_Byte19 STS_XCP_RES_DAQ_Byte18 STS_XCP_RES_DAQ_Byte17 STS_XCP_RES_DAQ_Byte16 STS_XCP_RES_DAQ_Byte15 STS_XCP_RES_DAQ_Byte14 STS_XCP_RES_DAQ_Byte13 STS_XCP_RES_DAQ_Byte12 STS_XCP_RES_DAQ_Byte11 STS_XCP_RES_DAQ_Byte10 STS_XCP_RES_DAQ_Byte9 STS_XCP_RES_DAQ_Byte8 STS_XCP_RES_DAQ_Byte7 STS_XCP_RES_DAQ_Byte6 STS_XCP_RES_DAQ_Byte5 STS_XCP_RES_DAQ_Byte4 STS_XCP_RES_DAQ_Byte3 STS_XCP_RES_DAQ_Byte2 STS_XCP_RES_DAQ_Byte1 STS_XCP_RES_DAQ_Byte0;
SIG_GROUP_ 17 SRR_RL_XCP_CTO_RESP 1 : STS_XCP_RES_CTO_Byte63 STS_XCP_RES_CTO_Byte62 STS_XCP_RES_CTO_Byte61 STS_XCP_RES_CTO_Byte60 STS_XCP_RES_CTO_Byte59 STS_XCP_RES_CTO_Byte58 STS_XCP_RES_CTO_Byte57 STS_XCP_RES_CTO_Byte56 STS_XCP_RES_CTO_Byte55 STS_XCP_RES_CTO_Byte54 STS_XCP_RES_CTO_Byte53 STS_XCP_RES_CTO_Byte52 STS_XCP_RES_CTO_Byte51 STS_XCP_RES_CTO_Byte50 STS_XCP_RES_CTO_Byte49 STS_XCP_RES_CTO_Byte48 STS_XCP_RES_CTO_Byte47 STS_XCP_RES_CTO_Byte46 STS_XCP_RES_CTO_Byte45 STS_XCP_RES_CTO_Byte44 STS_XCP_RES_CTO_Byte43 STS_XCP_RES_CTO_Byte42 STS_XCP_RES_CTO_Byte41 STS_XCP_RES_CTO_Byte40 STS_XCP_RES_CTO_Byte39 STS_XCP_RES_CTO_Byte38 STS_XCP_RES_CTO_Byte37 STS_XCP_RES_CTO_Byte36 STS_XCP_RES_CTO_Byte35 STS_XCP_RES_CTO_Byte34 STS_XCP_RES_CTO_Byte33 STS_XCP_RES_CTO_Byte32 STS_XCP_RES_CTO_Byte0 STS_XCP_RES_CTO_Byte1 STS_XCP_RES_CTO_Byte2 STS_XCP_RES_CTO_Byte3 STS_XCP_RES_CTO_Byte4 STS_XCP_RES_CTO_Byte5 STS_XCP_RES_CTO_Byte6 STS_XCP_RES_CTO_Byte7 STS_XCP_RES_CTO_Byte8 STS_XCP_RES_CTO_Byte9 STS_XCP_RES_CTO_Byte10 STS_XCP_RES_CTO_Byte11 STS_XCP_RES_CTO_Byte12 STS_XCP_RES_CTO_Byte13 STS_XCP_RES_CTO_Byte14 STS_XCP_RES_CTO_Byte15 STS_XCP_RES_CTO_Byte16 STS_XCP_RES_CTO_Byte17 STS_XCP_RES_CTO_Byte18 STS_XCP_RES_CTO_Byte19 STS_XCP_RES_CTO_Byte20 STS_XCP_RES_CTO_Byte21 STS_XCP_RES_CTO_Byte22 STS_XCP_RES_CTO_Byte23 STS_XCP_RES_CTO_Byte24 STS_XCP_RES_CTO_Byte25 STS_XCP_RES_CTO_Byte26 STS_XCP_RES_CTO_Byte27 STS_XCP_RES_CTO_Byte28 STS_XCP_RES_CTO_Byte29 STS_XCP_RES_CTO_Byte30 STS_XCP_RES_CTO_Byte31;
SIG_GROUP_ 16 SRR_RL_XCP_CTO_REQ 1 : STS_XCP_REQ_CTO_Byte63 STS_XCP_REQ_CTO_Byte62 STS_XCP_REQ_CTO_Byte61 STS_XCP_REQ_CTO_Byte60 STS_XCP_REQ_CTO_Byte59 STS_XCP_REQ_CTO_Byte58 STS_XCP_REQ_CTO_Byte57 STS_XCP_REQ_CTO_Byte56 STS_XCP_REQ_CTO_Byte55 STS_XCP_REQ_CTO_Byte54 STS_XCP_REQ_CTO_Byte53 STS_XCP_REQ_CTO_Byte52 STS_XCP_REQ_CTO_Byte51 STS_XCP_REQ_CTO_Byte50 STS_XCP_REQ_CTO_Byte49 STS_XCP_REQ_CTO_Byte48 STS_XCP_REQ_CTO_Byte47 STS_XCP_REQ_CTO_Byte46 STS_XCP_REQ_CTO_Byte45 STS_XCP_REQ_CTO_Byte44 STS_XCP_REQ_CTO_Byte43 STS_XCP_REQ_CTO_Byte42 STS_XCP_REQ_CTO_Byte41 STS_XCP_REQ_CTO_Byte40 STS_XCP_REQ_CTO_Byte39 STS_XCP_REQ_CTO_Byte38 STS_XCP_REQ_CTO_Byte37 STS_XCP_REQ_CTO_Byte36 STS_XCP_REQ_CTO_Byte35 STS_XCP_REQ_CTO_Byte34 STS_XCP_REQ_CTO_Byte33 STS_XCP_REQ_CTO_Byte32 STS_PID STS_XCP_REQ_CTO_Byte1 STS_XCP_REQ_CTO_Byte2 STS_XCP_REQ_CTO_Byte3 STS_XCP_REQ_CTO_Byte4 STS_XCP_REQ_CTO_Byte5 STS_XCP_REQ_CTO_Byte6 STS_XCP_REQ_CTO_Byte7 STS_XCP_REQ_CTO_Byte8 STS_XCP_REQ_CTO_Byte9 STS_XCP_REQ_CTO_Byte10 STS_XCP_REQ_CTO_Byte11 STS_XCP_REQ_CTO_Byte12 STS_XCP_REQ_CTO_Byte13 STS_XCP_REQ_CTO_Byte14 STS_XCP_REQ_CTO_Byte15 STS_XCP_REQ_CTO_Byte16 STS_XCP_REQ_CTO_Byte17 STS_XCP_REQ_CTO_Byte18 STS_XCP_REQ_CTO_Byte19 STS_XCP_REQ_CTO_Byte20 STS_XCP_REQ_CTO_Byte21 STS_XCP_REQ_CTO_Byte22 STS_XCP_REQ_CTO_Byte23 STS_XCP_REQ_CTO_Byte24 STS_XCP_REQ_CTO_Byte25 STS_XCP_REQ_CTO_Byte26 STS_XCP_REQ_CTO_Byte27 STS_XCP_REQ_CTO_Byte28 STS_XCP_REQ_CTO_Byte29 STS_XCP_REQ_CTO_Byte30 STS_XCP_REQ_CTO_Byte31;
SIG_GROUP_ 164 FLR_RadarStatus2 1 : STS_INTRFC_VERSION_ID_PATCH STS_INTRFC_VERSION_ID_MINOR STS_INTRFC_VERSION_ID_MAJOR STS_Yaw_Rate_Calc_QF STS_Vehicle_Speed_Calc_QF STS_Gear_Position STS_RAIN_COUNT STS_Last_CAN_Det_Inst_Latency STS_First_CAN_Det_Inst_Latency STS_CORE_ACTV_FLT_BYTE_0_to_3 STS_CORE_ACTV_FLT_BYTE_8_to_11 STS_CORE_ACTV_FLT_BYTE_11_to_15 STS_Project_ACTV_FLT_BYTE_0_to_3 STS_Project_ACTV_FLT_BYTE_4_to_5 STS_CAN_NM_State STS_TIME_SYNC_OFFSET STS_RDD_CORE_THROUGHPUT STS_MH_002_CRC16 STS_MH_002_CYCLE_COUNTER STS_NO_TSYN_ERROR STS_POINT_OF_TRIGGER STS_BRR_STATUS STS_CORE_ACTV_FLT_BYTE_4_to_7 STS_MMIC_TEMP_TX1_2 STS_MMIC_TEMP_TX3_4 STS_MCU_TEMP STS_MMIC_TEMP_RX STS_MMIC_TEMP_TX0 STS_XCVR_OPERATIONAL STS_SCAN_TYPE STS_AF_CORE_THROUGHPUT STS_MMIC_RE_INIT_COUNT STS_VEHICLE_SPEED_CALC STS_STEERING_ANGLE STS_STEERING_ANGLE_SIGN STS_VEH_SPEED_DIRECTION STS_YAW_RATE_BIAS STS_VEHICLE_SUPPLY_VOLTAGE;
